VERSION "$Format:%h$"

NS_ :

BS_:

BU_: APB APP APS BCCEN BDY DAS DBG EAS EPAS EPAS2 EPAS3S EPB EPBM ESP GTW GTWU IBST IC MCU OCS PARK PARK3 RADAR RCM RT3000 SCCM SDM SEC TAS TAS2 TAS2DBG TOOL TPMS VCSEATD VCSEATP

BO_ 643 BODY_R1: 8 GTW
 SG_ DrRLtch_FL_Stat : 0|2@1+ (1,0) [0|0] "" Vector__XXX
 SG_ DrRLtch_FR_Stat : 2|2@1+ (1,0) [0|0] "" Vector__XXX
 SG_ DrRLtch_RL_Stat : 4|2@1+ (1,0) [0|0] "" Vector__XXX
 SG_ DrRLtch_RR_Stat : 6|2@1+ (1,0) [0|0] "" Vector__XXX
 SG_ DL_RLtch_Stat : 8|2@1+ (1,0) [0|0] "" Vector__XXX
 SG_ EngHd_Stat : 10|2@1+ (1,0) [0|0] "" Vector__XXX
 SG_ VTA_Alm_Actv : 13|1@1+ (1,0) [0|0] "" Vector__XXX
 SG_ LgtSens_Twlgt : 16|3@1+ (1,0) [0|7] "Steps" Vector__XXX
 SG_ LgtSens_SNA : 19|1@1+ (1,0) [0|0] "" Vector__XXX
 SG_ LgtSens_Tunnel : 20|1@1+ (1,0) [0|0] "" Vector__XXX
 SG_ LgtSens_Flt : 21|1@1+ (1,0) [0|0] "" Vector__XXX
 SG_ LgtSens_Night : 22|1@1+ (1,0) [0|0] "" SCCM
 SG_ ADL_LoBm_On_Rq : 23|1@1+ (1,0) [0|0] "" Vector__XXX
 SG_ Trlr_Stat : 24|2@1+ (1,0) [0|0] "" Vector__XXX
 SG_ Hrn_On : 26|1@1+ (1,0) [0|0] "" Vector__XXX
 SG_ Term54_Actv : 27|1@1+ (1,0) [0|0] "" Vector__XXX
 SG_ MPkBrk_Stat : 28|1@1+ (1,0) [0|0] "" Vector__XXX
 SG_ WprOutsdPkPosn : 29|1@1+ (1,0) [0|0] "" Vector__XXX
 SG_ LoBm_On_Rq : 32|1@1+ (1,0) [0|0] "" Vector__XXX
 SG_ HiBm_On : 33|1@1+ (1,0) [0|0] "" Vector__XXX
 SG_ IrLmp_D_Lt_Flt : 34|1@1+ (1,0) [0|0] "" Vector__XXX
 SG_ IrLmp_P_Rt_Flt : 35|1@1+ (1,0) [0|0] "" Vector__XXX
 SG_ LoBm_D_Lt_Flt : 36|1@1+ (1,0) [0|0] "" Vector__XXX
 SG_ LoBm_P_Rt_Flt : 37|1@1+ (1,0) [0|0] "" Vector__XXX
 SG_ RevGr_Engg : 38|2@1+ (1,0) [0|0] "" Vector__XXX
 SG_ AirTemp_Insd : 40|8@1+ (0.25,0) [0|58] "C" SCCM
 SG_ Bckl_Sw_RL_Stat_SAM_R : 48|2@1+ (1,0) [0|0] "" Vector__XXX
 SG_ Bckl_Sw_RR_Stat_SAM_R : 50|2@1+ (1,0) [0|0] "" Vector__XXX
 SG_ Bckl_Sw_RM_Stat_SAM_R : 52|2@1+ (1,0) [0|0] "" Vector__XXX
 SG_ StW_Cond_Stat : 54|2@1+ (1,0) [0|0] "" SCCM
 SG_ AirTemp_Outsd : 56|8@1+ (0.5,-40) [-40|85] "C" Vector__XXX

BO_ 15 CGW_STAT: 1 GTW
 SG_ CGW_Rout_Stat : 0|2@1+ (1,0) [0|0] "" SCCM
 SG_ BusFlt_PrmntActv : 2|1@1+ (1,0) [0|0] "" Vector__XXX

BO_ 556 CHG_status: 8 GTW
 SG_ CHG_evseAccept : 0|1@1+ (1,0) [0|0] "" Vector__XXX
 SG_ CHG_evseRequest : 1|1@1+ (1,0) [0|0] "" Vector__XXX
 SG_ CHG_retryCount : 2|2@1+ (1,0) [0|3] "" Vector__XXX
 SG_ CHG_mainState : 4|4@1+ (1,0) [0|0] "" Vector__XXX
 SG_ CHG_voltageLimitAchieved : 8|1@1+ (1,0) [0|0] "" Vector__XXX
 SG_ CHG_requestHVACPowerOn : 9|1@1+ (1,0) [0|0] "" Vector__XXX
 SG_ CHG_proximitySimUnlatched : 10|1@1+ (1,0) [0|0] "" Vector__XXX
 SG_ CHG_proximity : 11|2@1+ (1,0) [0|0] "" Vector__XXX
 SG_ CHG_pilot : 13|3@1+ (1,0) [0|0] "" Vector__XXX
 SG_ CHG_pilotCurrent : 16|8@1+ (0.5,0) [0|127.5] "A" Vector__XXX
 SG_ CHG_cableType : 24|3@1+ (1,0) [0|0] "" Vector__XXX
 SG_ CHG_cableState : 27|2@1+ (1,0) [0|0] "" EPB,EPBM
 SG_ CHG_phaseConfig : 29|3@1+ (1,0) [0|0] "" Vector__XXX
 SG_ CHG_v12V : 32|8@1+ (0.1,0) [0|0] "V" Vector__XXX
 SG_ CHG_lineChgShuttingDown : 40|1@1+ (1,0) [0|0] "" Vector__XXX
 SG_ CHG_subState : 41|6@1+ (1,0) [0|0] "" Vector__XXX
 SG_ CHG_waveformDataReady : 47|1@1+ (1,0) [0|0] "" Vector__XXX
 SG_ CHG_GFCICurrent : 48|7@1+ (0.4,0) [0|51] "mA" Vector__XXX
 SG_ CHG_maxLineCurrent : 55|7@1+ (1,0) [0|127] "A" Vector__XXX
 SG_ CHG_inputRelayState : 62|2@1+ (1,0) [0|0] "" Vector__XXX

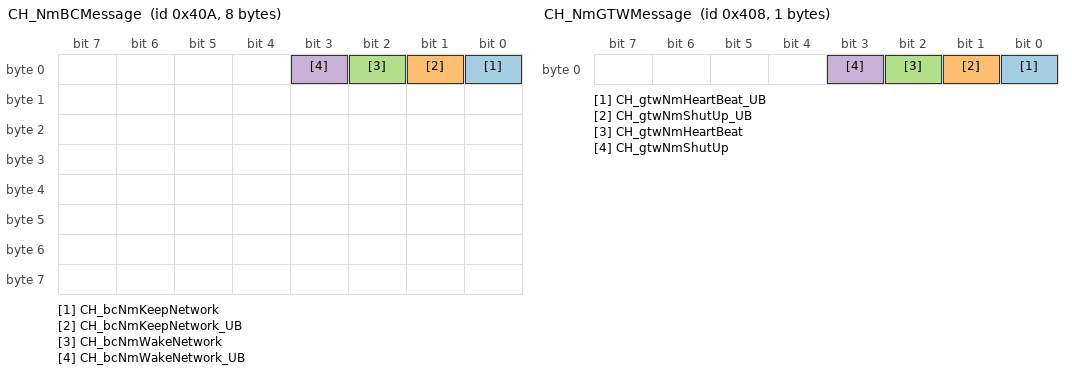
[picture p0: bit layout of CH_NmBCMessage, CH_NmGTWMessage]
BO_ 1034 CH_NmBCMessage: 8 BDY
 SG_ CH_bcNmKeepNetwork : 0|1@1+ (1,0) [0|0] "" GTW
 SG_ CH_bcNmKeepNetwork_UB : 1|1@1+ (1,0) [0|0] "" GTW
 SG_ CH_bcNmWakeNetwork : 2|1@1+ (1,0) [0|0] "" GTW
 SG_ CH_bcNmWakeNetwork_UB : 3|1@1+ (1,0) [0|0] "" GTW

BO_ 1032 CH_NmGTWMessage: 1 GTW
 SG_ CH_gtwNmHeartBeat_UB : 0|1@1+ (1,0) [0|0] "" BDY,SEC,BCCEN
 SG_ CH_gtwNmShutUp_UB : 1|1@1+ (1,0) [0|0] "" BDY,SEC,BCCEN
 SG_ CH_gtwNmHeartBeat : 2|1@1+ (1,0) [0|0] "" BDY,SEC,BCCEN
 SG_ CH_gtwNmShutUp : 3|1@1+ (1,0) [0|0] "" BDY,SEC,BCCEN

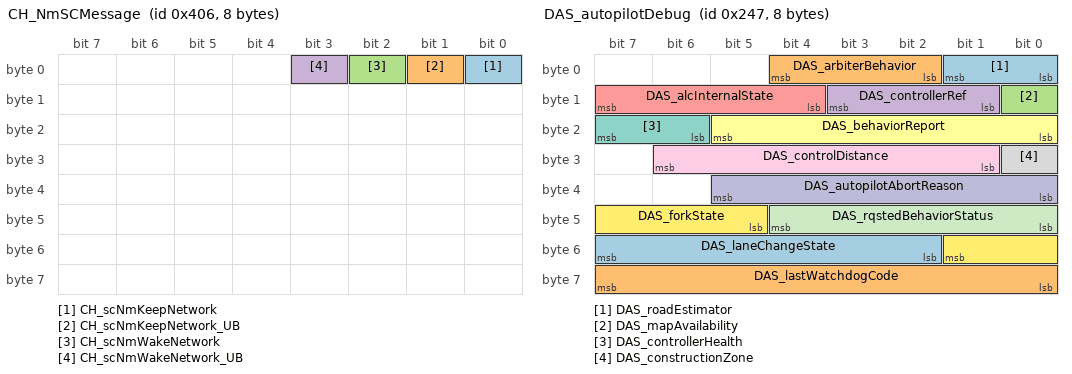
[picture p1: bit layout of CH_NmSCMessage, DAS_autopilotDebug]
BO_ 1030 CH_NmSCMessage: 8 SEC
 SG_ CH_scNmKeepNetwork : 0|1@1+ (1,0) [0|0] "" GTW
 SG_ CH_scNmKeepNetwork_UB : 1|1@1+ (1,0) [0|0] "" GTW
 SG_ CH_scNmWakeNetwork : 2|1@1+ (1,0) [0|0] "" GTW
 SG_ CH_scNmWakeNetwork_UB : 3|1@1+ (1,0) [0|0] "" GTW

BO_ 21 CTRL_U_A2: 4 GTW
 SG_ SwIllLvl : 0|8@1+ (1,0) [0|100] "%" SCCM
 SG_ DispBrt_IC : 8|8@1+ (1,0) [0|100] "%" Vector__XXX

BO_ 519 CVI: 8 GTW
 SG_ Group : 0|4@1+ (1,0) [0|0] "" SCCM
 SG_ Country : 4|4@1+ (1,0) [0|0] "" Vector__XXX
 SG_ VehLine : 8|6@1+ (1,0) [0|0] "" SCCM
 SG_ Guard : 14|2@1+ (1,0) [0|0] "" Vector__XXX
 SG_ VehLinePack : 16|2@1+ (1,0) [0|0] "" Vector__XXX
 SG_ VehLineYear : 18|5@1+ (1,2000) [2000|2029] "" Vector__XXX
 SG_ VSTS_Avl : 23|1@1+ (1,0) [0|0] "" Vector__XXX
 SG_ BodyStyle : 24|5@1+ (1,0) [0|0] "" Vector__XXX
 SG_ StStyle : 29|2@1+ (1,0) [0|0] "" SCCM
 SG_ PSTS_Avl : 31|1@1+ (1,0) [0|0] "" Vector__XXX
 SG_ EngStyle : 32|8@1+ (1,0) [0|0] "" Vector__XXX
 SG_ TCM_Avl : 40|1@1+ (1,0) [0|0] "" Vector__XXX
 SG_ HVAC_Avl : 41|1@1+ (1,0) [0|0] "" Vector__XXX
 SG_ TrlrHtch_Avl : 42|1@1+ (1,0) [0|0] "" Vector__XXX
 SG_ VTA_Avl : 43|1@1+ (1,0) [0|0] "" Vector__XXX
 SG_ PCD_Avl : 44|1@1+ (1,0) [0|0] "" Vector__XXX
 SG_ ICH_Avl : 45|1@1+ (1,0) [0|0] "" Vector__XXX
 SG_ LgtSens_Avl : 46|1@1+ (1,0) [0|0] "" Vector__XXX
 SG_ RainSens_Avl : 47|1@1+ (1,0) [0|0] "" Vector__XXX
 SG_ HVACStyle : 48|2@1+ (1,0) [0|0] "" Vector__XXX
 SG_ VehOPTPack : 50|2@1+ (1,0) [0|0] "" Vector__XXX
 SG_ Cplt_SL_Enbl : 52|1@1+ (1,0) [0|0] "" Vector__XXX
 SG_ RoofStyle : 53|3@1+ (1,0) [0|0] "" Vector__XXX
 SG_ CRC_CVI : 56|8@1+ (1,0) [0|0] "" Vector__XXX

BO_ 1817 DAS_IsotermAP: 8 DAS
 SG_ DAS_IsotermAP : 0|64@1+ (1,0) [0|0] "" DBG

BO_ 1849 DAS_IsotermSMS: 8 DAS
 SG_ DAS_IsotermSMS : 0|64@1+ (1,0) [0|0] "" DBG

BO_ 1465 DAS_alertLog: 8 DAS
 SG_ DAS_alertID M : 0|14@1+ (1,0) [0|0] "" GTW
 SG_ DAS_alertType : 15|1@1+ (1,0) [0|0] "" GTW
 SG_ DAS_alertDataW0 m0 : 16|16@1+ (1,0) [0|0] "" GTW
 SG_ DAS_alertDataW1 m0 : 32|16@1+ (1,0) [0|0] "" GTW
 SG_ DAS_alertDataW2 m0 : 48|16@1+ (1,0) [0|0] "" GTW
 SG_ DAS_sw004_radIssue m4 : 16|1@1+ (1,0) [0|0] "" GTW
 SG_ DAS_sw004_radHWFailure m4 : 17|1@1+ (1,0) [0|0] "" GTW
 SG_ DAS_sw004_radSensorBlind m4 : 18|1@1+ (1,0) [0|0] "" GTW
 SG_ DAS_sw004_radSGUFailure m4 : 19|1@1+ (1,0) [0|0] "" GTW
 SG_ DAS_sw004_radMia m4 : 20|1@1+ (1,0) [0|0] "" GTW
 SG_ DAS_sw004_radDynamicsError m4 : 21|1@1+ (1,0) [0|0] "" GTW
 SG_ DAS_sw004_espMIA m4 : 23|1@1+ (1,0) [0|0] "" GTW
 SG_ DAS_sw004_accState m4 : 24|4@1+ (1,0) [0|0] "" GTW
 SG_ DAS_sw004_appMobileyeStatus m4 : 28|5@1+ (1,0) [0|0] "" GTW
 SG_ DAS_sw004_diCruiseStateFault m4 : 33|1@1+ (1,0) [0|0] "" GTW
 SG_ DAS_sw004_diMIA m4 : 34|1@1+ (1,0) [0|0] "" GTW
 SG_ DAS_sw004_accelPedalInvalid m4 : 35|1@1+ (1,0) [0|0] "" GTW
 SG_ DAS_sw004_stwAngleInvalid m4 : 36|1@1+ (1,0) [0|0] "" GTW
 SG_ DAS_sw004_accelerationInvalid m4 : 37|1@1+ (1,0) [0|0] "" GTW
 SG_ DAS_sw004_diSpeedInvalid m4 : 38|1@1+ (1,0) [0|0] "" GTW
 SG_ DAS_sw004_DASFeaturesDisabled m4 : 40|1@1+ (1,0) [0|0] "" GTW
 SG_ DAS_sw004_appMobileyeNotInVision m4 : 41|1@1+ (1,0) [0|0] "" GTW
 SG_ DAS_sw004_CamCommonMIA m4 : 42|1@1+ (1,0) [0|0] "" GTW
 SG_ DAS_sw004_CamObjectsMIA m4 : 43|1@1+ (1,0) [0|0] "" GTW
 SG_ DAS_sw004_CamWatchdog m4 : 44|1@1+ (1,0) [0|0] "" GTW
 SG_ DAS_sw004_RadarLowVisibility m4 : 45|1@1+ (1,0) [0|0] "" GTW
 SG_ DAS_sw004_RadarMisalignment m4 : 46|1@1+ (1,0) [0|0] "" GTW
 SG_ DAS_sw004_OutOfFocusImage m4 : 47|1@1+ (1,0) [0|0] "" GTW
 SG_ DAS_sw004_ImpairedVD m4 : 48|1@1+ (1,0) [0|0] "" GTW
 SG_ DAS_sw004_SunRay m4 : 49|1@1+ (1,0) [0|0] "" GTW
 SG_ DAS_sw004_Splashes m4 : 50|1@1+ (1,0) [0|0] "" GTW
 SG_ DAS_sw004_BlurredImage m4 : 51|1@1+ (1,0) [0|0] "" GTW
 SG_ DAS_sw004_LowSun m4 : 52|1@1+ (1,0) [0|0] "" GTW
 SG_ DAS_sw004_SmearedSpots m4 : 53|1@1+ (1,0) [0|0] "" GTW
 SG_ DAS_sw004_PartialBlockage m4 : 54|1@1+ (1,0) [0|0] "" GTW
 SG_ DAS_sw004_AutofixOutOfCalib m4 : 55|1@1+ (1,0) [0|0] "" GTW
 SG_ DAS_sw004_AutofixOutOfCalibHorzn m4 : 56|1@1+ (1,0) [0|0] "" GTW
 SG_ DAS_sw004_AutofixOutOfCalibYaw m4 : 57|1@1+ (1,0) [0|0] "" GTW
 SG_ DAS_sw004_FullBlockage m4 : 58|1@1+ (1,0) [0|0] "" GTW
 SG_ DAS_sw004_SmearedHalos m4 : 59|1@1+ (1,0) [0|0] "" GTW
 SG_ DAS_sw004_FoggyLights m4 : 60|1@1+ (1,0) [0|0] "" GTW
 SG_ DAS_sw004_SelfGlare m4 : 61|1@1+ (1,0) [0|0] "" GTW
 SG_ DAS_sw004_visionNotRunning m4 : 62|1@1+ (1,0) [0|1] "" GTW
 SG_ DAS_sw005_AutofixOutOfCalib m5 : 16|1@1+ (1,0) [0|0] "" GTW
 SG_ DAS_sw005_AutofixOutOfCalibYaw m5 : 17|1@1+ (1,0) [0|0] "" GTW
 SG_ DAS_sw005_RadarMisalignment m5 : 18|1@1+ (1,0) [0|0] "" GTW
 SG_ DAS_sw005_partialBlockage m5 : 20|1@1+ (1,0) [0|0] "" GTW
 SG_ DAS_sw005_fullBlockage m5 : 21|1@1+ (1,0) [0|0] "" GTW
 SG_ DAS_sw005_camObjHeader m5 : 22|1@1+ (1,0) [0|0] "" GTW
 SG_ DAS_sw005_camCommonMsg m5 : 23|1@1+ (1,0) [0|0] "" GTW
 SG_ DAS_sw005_camFcwPcwMsg m5 : 24|1@1+ (1,0) [0|0] "" GTW
 SG_ DAS_sw005_radHWFailure m5 : 25|1@1+ (1,0) [0|0] "" GTW
 SG_ DAS_sw005_radSensorBlind m5 : 26|1@1+ (1,0) [0|0] "" GTW
 SG_ DAS_sw005_radSGUFailure m5 : 27|1@1+ (1,0) [0|0] "" GTW
 SG_ DAS_sw005_radMia m5 : 28|1@1+ (1,0) [0|0] "" GTW
 SG_ DAS_sw005_brakePedal m5 : 29|1@1+ (1,0) [0|0] "" GTW
 SG_ DAS_sw005_steeringAngle m5 : 30|1@1+ (1,0) [0|0] "" GTW
 SG_ DAS_sw005_steeringAngleRate m5 : 31|1@1+ (1,0) [0|0] "" GTW
 SG_ DAS_sw005_speed m5 : 32|1@1+ (1,0) [0|0] "" GTW
 SG_ DAS_sw005_gear m5 : 33|1@1+ (1,0) [0|0] "" GTW
 SG_ DAS_sw005_stabilityControl m5 : 34|1@1+ (1,0) [0|0] "" GTW
 SG_ DAS_sw005_blinkers m5 : 35|1@1+ (1,0) [0|0] "" GTW
 SG_ DAS_sw005_yaw m5 : 36|1@1+ (1,0) [0|0] "" GTW
 SG_ DAS_sw005_longAccel m5 : 37|1@1+ (1,0) [0|0] "" GTW
 SG_ DAS_sw005_accelPedal m5 : 38|1@1+ (1,0) [0|0] "" GTW
 SG_ DAS_sw005_fcmSensitivity m5 : 41|1@1+ (1,0) [0|0] "" GTW
 SG_ DAS_sw005_dasDisabled m5 : 42|1@1+ (1,0) [0|0] "" GTW
 SG_ DAS_sw005_speedDerivative m5 : 43|1@1+ (1,0) [0|0] "" GTW
 SG_ DAS_sw005_camWatchdog m5 : 44|1@1+ (1,0) [0|0] "" GTW
 SG_ DAS_sw005_AutofixOutOfCalibHorzn m5 : 45|1@1+ (1,0) [0|0] "" GTW
 SG_ DAS_sw005_RadarLowVisibility m5 : 46|1@1+ (1,0) [0|0] "" GTW
 SG_ DAS_sw005_radCalibration m5 : 47|1@1+ (1,0) [0|0] "" GTW
 SG_ DAS_sw006_RadarLowVisibility m6 : 16|1@1+ (1,0) [0|0] "" GTW
 SG_ DAS_sw006_RadarMisaligned m6 : 17|1@1+ (1,0) [0|0] "" GTW
 SG_ DAS_sw006_OutOfFocusImage m6 : 18|1@1+ (1,0) [0|0] "" GTW
 SG_ DAS_sw006_SunRay m6 : 19|1@1+ (1,0) [0|0] "" GTW
 SG_ DAS_sw006_Splashes m6 : 20|1@1+ (1,0) [0|0] "" GTW
 SG_ DAS_sw006_BlurredImage m6 : 21|1@1+ (1,0) [0|0] "" GTW
 SG_ DAS_sw006_LowSun m6 : 22|1@1+ (1,0) [0|0] "" GTW
 SG_ DAS_sw006_SmearedSpots m6 : 23|1@1+ (1,0) [0|0] "" GTW
 SG_ DAS_sw006_PartialBlockage m6 : 24|1@1+ (1,0) [0|0] "" GTW
 SG_ DAS_sw006_AutofixOutOfCalib m6 : 25|1@1+ (1,0) [0|0] "" GTW
 SG_ DAS_sw006_AutofixOutOfCalibHorzn m6 : 26|1@1+ (1,0) [0|0] "" GTW
 SG_ DAS_sw006_AutofixOutOfCalibYaw m6 : 27|1@1+ (1,0) [0|0] "" GTW
 SG_ DAS_sw006_FullBlockage m6 : 28|1@1+ (1,0) [0|0] "" GTW
 SG_ DAS_sw006_SmearedHalos m6 : 29|1@1+ (1,0) [0|0] "" GTW
 SG_ DAS_sw006_FoggyLights m6 : 30|1@1+ (1,0) [0|0] "" GTW
 SG_ DAS_sw006_SelfGlare m6 : 31|1@1+ (1,0) [0|0] "" GTW
 SG_ DAS_sw006_blinkers m6 : 32|1@1+ (1,0) [0|0] "" GTW
 SG_ DAS_sw006_seatbelt m6 : 33|1@1+ (1,0) [0|0] "" GTW
 SG_ DAS_sw006_accelPedal m6 : 34|1@1+ (1,0) [0|0] "" GTW
 SG_ DAS_sw006_radMia m6 : 35|1@1+ (1,0) [0|0] "" GTW
 SG_ DAS_sw006_radHWFailure m6 : 37|1@1+ (1,0) [0|0] "" GTW
 SG_ DAS_sw006_radSensorBlind m6 : 38|1@1+ (1,0) [0|0] "" GTW
 SG_ DAS_sw006_radSGUFailure m6 : 39|1@1+ (1,0) [0|0] "" GTW
 SG_ DAS_sw006_brakePedal m6 : 40|1@1+ (1,0) [0|0] "" GTW
 SG_ DAS_sw006_steeringAngle m6 : 41|1@1+ (1,0) [0|0] "" GTW
 SG_ DAS_sw006_steeringAngleRate m6 : 42|1@1+ (1,0) [0|0] "" GTW
 SG_ DAS_sw006_speed m6 : 43|1@1+ (1,0) [0|0] "" GTW
 SG_ DAS_sw006_gear m6 : 44|1@1+ (1,0) [0|0] "" GTW
 SG_ DAS_sw006_stabilityControl m6 : 45|1@1+ (1,0) [0|0] "" GTW
 SG_ DAS_sw006_dasDisabled m6 : 47|1@1+ (1,0) [0|0] "" GTW
 SG_ DAS_sw006_speedDerivative m6 : 48|1@1+ (1,0) [0|0] "" GTW
 SG_ DAS_sw006_camWatchdog m6 : 49|1@1+ (1,0) [0|0] "" GTW
 SG_ DAS_sw006_camObjHeader m6 : 50|1@1+ (1,0) [0|0] "" GTW
 SG_ DAS_sw006_camCommonMsg m6 : 51|1@1+ (1,0) [0|0] "" GTW
 SG_ DAS_sw006_camFcwPcwMsg m6 : 52|1@1+ (1,0) [0|0] "" GTW
 SG_ DAS_sw006_longAccel m6 : 53|1@1+ (1,0) [0|0] "" GTW
 SG_ DAS_sw006_yawRate m6 : 54|1@1+ (1,0) [0|0] "" GTW
 SG_ DAS_sw006_DIaebState_SNA m6 : 55|1@1+ (1,0) [0|0] "" GTW
 SG_ DAS_sw006_DIaebStateUnavailable m6 : 56|1@1+ (1,0) [0|0] "" GTW
 SG_ DAS_sw006_brakeLights m6 : 57|1@1+ (1,0) [0|0] "" GTW
 SG_ DAS_sw006_trailerMode m6 : 58|1@1+ (1,0) [0|0] "" GTW
 SG_ DAS_sw006_timeOfDay m6 : 59|2@1+ (1,0) [0|0] "" GTW
 SG_ DAS_sw006_radCalibration m6 : 61|1@1+ (1,0) [0|0] "" GTW
 SG_ DAS_sw009_DIaebState_fault m9 : 16|1@1+ (1,0) [0|0] "" GTW
 SG_ DAS_sw009_DI_aeb_unresponsive m9 : 17|1@1+ (1,0) [0|0] "" GTW
 SG_ DAS_sw009_DI_MIA m9 : 18|1@1+ (1,0) [0|0] "" GTW
 SG_ DAS_sw010_a04calibNotDone m10 : 16|1@1+ (1,0) [0|0] "" GTW
 SG_ DAS_sw010_a05calibReqd m10 : 17|1@1+ (1,0) [0|0] "" GTW
 SG_ DAS_sw010_a06calibNotOK m10 : 18|1@1+ (1,0) [0|0] "" GTW
 SG_ DAS_sw010_a08PlantMode m10 : 19|1@1+ (1,0) [0|0] "" GTW
 SG_ DAS_sw010_HorizontalMisalignment m10 : 20|16@1+ (0.00137332,-45) [-45|45.0005262] "deg" GTW
 SG_ DAS_sw010_VerticalMisalignment m10 : 36|10@1+ (0.087977,-45) [-45|45.000471] "deg" GTW
 SG_ DAS_sw010_unusedBits m10 : 46|2@1+ (1,0) [0|0] "" GTW
 SG_ DAS_sw010_VmaPlausibility m10 : 48|16@1+ (1.52587890625005E-05,0) [0|0.99998474121097] "" GTW
 SG_ DAS_sw011_scaState m11 : 16|3@1+ (1,0) [0|7] "" GTW
 SG_ DAS_sw011_scaLeft m11 : 19|1@1+ (1,0) [0|1] "" GTW
 SG_ DAS_sw011_scaRight m11 : 20|1@1+ (1,0) [0|1] "" GTW
 SG_ DAS_sw011_scaBlinker m11 : 21|2@1+ (1,0) [0|3] "" GTW
 SG_ DAS_sw011_scaThreshold m11 : 23|1@1+ (1,0) [0|1] "" GTW
 SG_ DAS_sw011_scaSpeed m11 : 24|7@1+ (1,0) [0|127] "MPH" GTW
 SG_ DAS_sw011_scaSonicDist m11 : 31|5@1+ (0.05,0) [0|1.5] "m" GTW
 SG_ DAS_sw011_scaSteerAngle m11 : 38|10@1+ (0.1,-51.2) [-51.2|51.1] "deg" GTW
 SG_ DAS_sw011_egoRightOfCenter m11 : 48|1@1+ (1,0) [0|1] "" GTW
 SG_ DAS_sw011_egoMovingRight m11 : 49|1@1+ (1,0) [0|1] "" GTW
 SG_ DAS_sw011_egoLeftOfCenter m11 : 50|1@1+ (1,0) [0|1] "" GTW
 SG_ DAS_sw011_egoMovingLeft m11 : 51|1@1+ (1,0) [0|1] "" GTW
 SG_ DAS_sw011_polyValid m11 : 52|1@1+ (1,0) [0|1] "" GTW
 SG_ DAS_sw011_egoCentered m11 : 53|1@1+ (1,0) [0|1] "" GTW
 SG_ DAS_sw011_scaReasonEldw m11 : 54|1@1+ (1,0) [0|1] "" GTW
 SG_ DAS_sw011_laneWidth m11 : 56|8@1+ (0.025,0) [0|6.375] "m" GTW
 SG_ DAS_sw012_bootTestResults m12 : 16|16@1+ (1,0) [0|65535] "" GTW
 SG_ DAS_sw012_bootDDRTempStatus m12 : 32|2@1+ (1,0) [0|3] "" GTW
 SG_ DAS_sw012_mespFatalErrCode m12 : 34|8@1+ (1,0) [0|255] "" GTW
 SG_ DAS_sw012_mespFatalErrDetails m12 : 42|8@1+ (1,0) [0|255] "" GTW
 SG_ DAS_sw012_mespDDRTempStatus m12 : 50|3@1+ (1,0) [0|7] "" GTW
 SG_ DAS_sw012_freescaleTemp m12 : 56|8@1- (1,0) [-128|127] "degC" GTW
 SG_ DAS_sw013_stateBeforeWatchdog m13 : 16|5@1+ (1,0) [0|0] "" GTW
 SG_ DAS_sw013_numEyeqResets m13 : 21|3@1+ (1,0) [0|0] "" GTW
 SG_ DAS_sw013_numCrcErrors m13 : 24|8@1+ (1,0) [0|0] "" GTW
 SG_ DAS_sw013_numSeqErrors m13 : 32|8@1+ (1,0) [0|0] "" GTW
 SG_ DAS_sw013_numNaksReceived m13 : 40|8@1+ (1,0) [0|0] "" GTW
 SG_ DAS_sw013_highestSeqRecd m13 : 48|12@1+ (1,0) [0|0] "" GTW
 SG_ DAS_sw013_numTransportErrors m13 : 60|4@1+ (1,0) [0|0] "" GTW
 SG_ DAS_sw014_fileNameHash m14 : 16|16@1+ (1,0) [0|0] "" GTW
 SG_ DAS_sw014_lineNumberInCode m14 : 32|16@1+ (1,0) [0|0] "" GTW
 SG_ DAS_sw014_assertData m14 : 48|16@1+ (1,0) [0|0] "" GTW
 SG_ DAS_sw015_RadarLowVisibility m15 : 16|2@1+ (1,0) [0|1] "" GTW
 SG_ DAS_sw015_RadarMisalignment m15 : 18|2@1+ (1,0) [0|1] "" GTW
 SG_ DAS_sw015_LowSun m15 : 20|2@1+ (1,0) [0|1] "" GTW
 SG_ DAS_sw015_BlurredImage m15 : 22|2@1+ (1,0) [0|1] "" GTW
 SG_ DAS_sw015_FullBlockage m15 : 24|2@1+ (1,0) [0|1] "" GTW
 SG_ DAS_sw015_PartialBlockage m15 : 26|2@1+ (1,0) [0|1] "" GTW
 SG_ DAS_sw015_AutofixOutOfCalib m15 : 28|2@1+ (1,0) [0|1] "" GTW
 SG_ DAS_sw015_AutofixOutOfCalibYaw m15 : 30|2@1+ (1,0) [0|1] "" GTW
 SG_ DAS_sw015_AutofixOOfCalibHorizon m15 : 32|2@1+ (1,0) [0|1] "" GTW
 SG_ DAS_sw015_Splashes m15 : 34|2@1+ (1,0) [0|1] "" GTW
 SG_ DAS_sw015_SmearedSpots m15 : 36|2@1+ (1,0) [0|1] "" GTW
 SG_ DAS_sw015_SmearedHalos m15 : 38|2@1+ (1,0) [0|1] "" GTW
 SG_ DAS_sw015_FoggyLights m15 : 40|2@1+ (1,0) [0|1] "" GTW
 SG_ DAS_sw015_SunRay m15 : 42|2@1+ (1,0) [0|1] "" GTW
 SG_ DAS_sw015_ImpairedVD m15 : 44|2@1+ (1,0) [0|1] "" GTW
 SG_ DAS_sw015_SelfGlare m15 : 46|2@1+ (1,0) [0|1] "" GTW
 SG_ DAS_sw015_OutOfFocusImage m15 : 48|2@1+ (1,0) [0|1] "" GTW
 SG_ DAS_sw016_targetDist m16 : 16|9@1+ (0.2,0) [0|102.2] "m" GTW
 SG_ DAS_sw016_targetRelSpeed m16 : 25|9@1+ (0.0625,-31) [-31|0.9375] "m/s" GTW
 SG_ DAS_sw016_targetOverlap m16 : 34|6@1+ (0.1,0) [0|6.3] "m" GTW
 SG_ DAS_sw016_hostSpeed m16 : 40|8@1+ (1,0) [0|255] "kph" GTW
 SG_ DAS_sw016_hostLongAccel m16 : 48|7@1+ (0.15625,-10) [-10|10] "m/s^2" GTW
 SG_ DAS_sw016_driverPressedAccelPed m16 : 55|1@1+ (1,0) [0|1] "" GTW
 SG_ DAS_sw016_driverPressedBrakePed m16 : 56|1@1+ (1,0) [0|1] "" GTW
 SG_ DAS_sw016_aebEnable m16 : 57|1@1+ (1,0) [0|1] "" GTW
 SG_ DAS_sw016_overrideBlinker m16 : 58|1@1+ (1,0) [0|1] "" GTW
 SG_ DAS_sw016_overrideBrake m16 : 59|1@1+ (1,0) [0|1] "" GTW
 SG_ DAS_sw016_overrideSteer m16 : 60|1@1+ (1,0) [0|1] "" GTW
 SG_ DAS_sw016_fcmModeAtEvent m16 : 61|2@1+ (1,0) [0|3] "" GTW
 SG_ DAS_sw016_accActive m16 : 63|1@1+ (1,0) [0|1] "" GTW
 SG_ DAS_sw017_Camera_Msg_Lanes_MIA m17 : 16|1@1+ (1,0) [0|1] "" GTW
 SG_ DAS_sw017_Camera_Msg_Objects_MIA m17 : 17|1@1+ (1,0) [0|1] "" GTW
 SG_ DAS_sw017_Camera_Msg_Tsr_MIA m17 : 18|1@1+ (1,0) [0|1] "" GTW
 SG_ DAS_sw017_Camera_Msg_Hlb_MIA m17 : 19|1@1+ (1,0) [0|1] "" GTW
 SG_ DAS_sw017_Camera_Msg_Common_MIA m17 : 20|1@1+ (1,0) [0|1] "" GTW
 SG_ DAS_sw017_Camera_Msg_FCW_PCW_MIA m17 : 21|1@1+ (1,0) [0|1] "" GTW
 SG_ DAS_sw017_Camera_Msg_TFL_MIA m17 : 22|1@1+ (1,0) [0|1] "" GTW
 SG_ DAS_sw017_Any_Lanes_Msg_Recd m17 : 23|1@1+ (1,0) [0|1] "" GTW
 SG_ DAS_sw017_Any_Objects_Msg_Recd m17 : 24|1@1+ (1,0) [0|1] "" GTW
 SG_ DAS_sw017_Any_TFL_Msg_Recd m17 : 25|1@1+ (1,0) [0|1] "" GTW
 SG_ DAS_sw017_numCrcErrors m17 : 26|6@1+ (1,0) [0|63] "" GTW
 SG_ DAS_sw017_numSeqErrors m17 : 32|8@1+ (1,0) [0|255] "" GTW
 SG_ DAS_sw017_numTransportErrors m17 : 40|8@1+ (1,0) [0|0] "" GTW
 SG_ DAS_sw017_highestSeqRecd m17 : 48|12@1+ (1,0) [0|0] "" GTW
 SG_ DAS_sw017_Any_Tsr_Msg_Recd m17 : 60|1@1+ (1,0) [0|1] "" GTW
 SG_ DAS_sw017_Any_Hlb_Msg_Recd m17 : 61|1@1+ (1,0) [0|1] "" GTW
 SG_ DAS_sw017_Any_Common_Msg_Recd m17 : 62|1@1+ (1,0) [0|1] "" GTW
 SG_ DAS_sw017_Any_FCW_PCW_Msg_Recd m17 : 63|1@1+ (1,0) [0|1] "" GTW
 SG_ DAS_sw018_minThreshold m18 : 16|13@1+ (1,0) [0|4500] "mV" GTW
 SG_ DAS_sw018_railID m18 : 29|2@1+ (1,0) [0|3] "" GTW
 SG_ DAS_sw018_powerSequnceError m18 : 31|1@1+ (1,0) [0|3] "" GTW
 SG_ DAS_sw018_maxThreshold m18 : 32|15@1+ (1,0) [50|5500] "mV" GTW
 SG_ DAS_sw018_railControl m18 : 47|1@1+ (1,0) [0|1] "" GTW
 SG_ DAS_sw018_currentVoltage m18 : 48|16@1+ (1,0) [0|6600] "mV" GTW
 SG_ DAS_sw019_taskId m19 : 16|8@1+ (1,0) [0|0] "" GTW
 SG_ DAS_sw019_numFreeBytes m19 : 24|8@1+ (1,-191) [-191|64] "# of bytes" GTW
 SG_ DAS_sw019_timeStamp m19 : 32|32@1+ (1,0) [0|4294967295] "ms" GTW
 SG_ DAS_sw020_unusedW0 m20 : 16|16@1+ (1,0) [0|0] "" GTW
 SG_ DAS_sw020_unusedW1 m20 : 32|16@1+ (1,0) [0|0] "" GTW
 SG_ DAS_sw020_unusedW2 m20 : 48|16@1+ (1,0) [0|0] "" GTW
 SG_ DAS_sw021_tempSensorId m21 : 16|8@1+ (1,0) [0|4] "" GTW
 SG_ DAS_sw021_minThreshold m21 : 24|8@1- (1,0) [-128|127] "degC" GTW
 SG_ DAS_sw021_maxThreshold m21 : 32|8@1- (1,0) [-128|127] "degC" GTW
 SG_ DAS_sw021_currentTemperature m21 : 40|8@1- (1,0) [-128|127] "degC" GTW
 SG_ DAS_sw021_unusedWord m21 : 48|16@1+ (1,0) [0|0] "" GTW
 SG_ DAS_sw022_operation m22 : 16|4@1+ (1,0) [0|0] "" GTW
 SG_ DAS_sw022_recordId m22 : 20|12@1+ (1,0) [0|0] "" GTW
 SG_ DAS_sw022_errorCode m22 : 32|32@1+ (1,0) [0|0] "" GTW
 SG_ DAS_sw024_Task_ID m24 : 16|4@1+ (1,0) [0|0] "" GTW
 SG_ DAS_sw024_numVirtualLaneVeh m24 : 20|4@1+ (1,0) [0|0] "" GTW
 SG_ DAS_sw024_currentVehicleApp m24 : 24|8@1+ (1,0) [0|0] "" GTW
 SG_ DAS_sw024_taskProgramCounter m24 : 32|32@1+ (1,0) [0|0] "" GTW
 SG_ DAS_sw025_state_before_override m25 : 16|4@1+ (1,0) [0|15] "" GTW
 SG_ DAS_sw025_road_class m25 : 20|3@1+ (1,0) [0|0] "" GTW
 SG_ DAS_sw025_road_match m25 : 23|1@1+ (1,0) [0|0] "" GTW
 SG_ DAS_sw025_controlled_access m25 : 24|1@1+ (1,0) [0|0] "" GTW
 SG_ DAS_sw025_leftLaneUsage m25 : 25|2@1+ (1,0) [0|3] "" GTW
 SG_ DAS_sw025_rightLaneUsage m25 : 27|2@1+ (1,0) [0|3] "" GTW
 SG_ DAS_sw025_vehiclesUsage m25 : 29|2@1+ (1,0) [0|3] "" GTW
 SG_ DAS_sw025_hppUsage m25 : 31|2@1+ (1,0) [0|3] "" GTW
 SG_ DAS_sw025_navigationUsage m25 : 33|2@1+ (1,0) [0|3] "" GTW
 SG_ DAS_sw025_modelUsage m25 : 35|2@1+ (1,0) [0|3] "" GTW
 SG_ DAS_sw025_bottsDotsUsage m25 : 37|2@1+ (1,0) [0|3] "" GTW
 SG_ DAS_sw025_offsetSide m25 : 39|2@1+ (1,0) [0|3] "" GTW
 SG_ DAS_sw025_torsionBarTorque m25 : 41|8@1+ (0.1,-12.8) [-12.8|12.7] "Nm" GTW
 SG_ DAS_sw026_task_id m26 : 16|2@1+ (1,0) [0|3] "" GTW
 SG_ DAS_sw026_tardiness m26 : 18|9@1+ (0.25,0) [0|127.75] "ms" GTW
 SG_ DAS_sw026_execution_time m26 : 27|9@1+ (0.125,0) [0|65.411] "ms" GTW
 SG_ DAS_sw026_can_mean_utilization m26 : 36|7@1+ (1,0) [0|127] "percent" GTW
 SG_ DAS_sw026_uds_mean_utilization m26 : 43|7@1+ (1,0) [0|127] "percent" GTW
 SG_ DAS_sw026_mob_mean_utilization m26 : 50|7@1+ (1,0) [0|127] "percent" GTW
 SG_ DAS_sw026_veh_mean_utilization m26 : 57|7@1+ (1,0) [0|127] "percent" GTW
 SG_ DAS_sw027_JTAG_Reset m27 : 16|1@1+ (1,0) [0|0] "" GTW
 SG_ DAS_sw027_Core_Reset m27 : 17|1@1+ (1,0) [0|0] "" GTW
 SG_ DAS_sw027_Unused_Bit_0 m27 : 18|1@1+ (1,0) [0|0] "" GTW
 SG_ DAS_sw027_CPU_Checkstop_Error m27 : 19|1@1+ (1,0) [0|0] "" GTW
 SG_ DAS_sw027_PLL_0_Failure m27 : 20|1@1+ (1,0) [0|0] "" GTW
 SG_ DAS_sw027_Clock_Monitor_0_Low m27 : 21|1@1+ (1,0) [0|0] "" GTW
 SG_ DAS_sw027_Clock_Monitor_0_Off m27 : 22|1@1+ (1,0) [0|0] "" GTW
 SG_ DAS_sw027_LVD_4v5 m27 : 23|1@1+ (1,0) [0|0] "" GTW
 SG_ DAS_sw027_Flash_Fatal_Error m27 : 24|1@1+ (1,0) [0|0] "" GTW
 SG_ DAS_sw027_PLL_1_Failure m27 : 25|1@1+ (1,0) [0|0] "" GTW
 SG_ DAS_sw027_Unused_Bit_1 m27 : 26|1@1+ (1,0) [0|0] "" GTW
 SG_ DAS_sw027_f_PLL_1_Off m27 : 27|1@1+ (1,0) [0|0] "" GTW
 SG_ DAS_sw027_Unused_Nibble m27 : 28|4@1+ (1,0) [0|0] "" GTW
 SG_ DAS_sw027_LVD_1v2 m27 : 32|1@1+ (1,0) [0|0] "" GTW
 SG_ DAS_sw027_Unused_Bit_2 m27 : 33|1@1+ (1,0) [0|0] "" GTW
 SG_ DAS_sw027_Watchdog m27 : 34|1@1+ (1,0) [0|0] "" GTW
 SG_ DAS_sw027_Unused_Bit_3 m27 : 35|1@1+ (1,0) [0|0] "" GTW
 SG_ DAS_sw027_LVD_2v7_VREG m27 : 36|1@1+ (1,0) [0|0] "" GTW
 SG_ DAS_sw027_LVD_2v7_Flash m27 : 37|1@1+ (1,0) [0|0] "" GTW
 SG_ DAS_sw027_LVD_2v7_IO m27 : 38|1@1+ (1,0) [0|0] "" GTW
 SG_ DAS_sw027_Unused_Bit_4 m27 : 39|1@1+ (1,0) [0|0] "" GTW
 SG_ DAS_sw027_Unused_Byte m27 : 40|8@1+ (1,0) [0|0] "" GTW
 SG_ DAS_sw027_ESR0 m27 : 48|1@1+ (1,0) [0|0] "" GTW
 SG_ DAS_sw027_ESR1 m27 : 49|1@1+ (1,0) [0|0] "" GTW
 SG_ DAS_sw027_SW m27 : 50|1@1+ (1,0) [0|0] "" GTW
 SG_ DAS_sw027_STM0 m27 : 51|1@1+ (1,0) [0|0] "" GTW
 SG_ DAS_sw027_STM1 m27 : 52|1@1+ (1,0) [0|0] "" GTW
 SG_ DAS_sw027_STM2 m27 : 53|1@1+ (1,0) [0|0] "" GTW
 SG_ DAS_sw027_CBS_SYSTEM m27 : 54|1@1+ (1,0) [0|0] "" GTW
 SG_ DAS_sw027_CBS_DEBUG m27 : 55|1@1+ (1,0) [0|0] "" GTW
 SG_ DAS_sw027_CBS_APP m27 : 56|1@1+ (1,0) [0|0] "" GTW
 SG_ DAS_sw027_EVR13 m27 : 57|1@1+ (1,0) [0|0] "" GTW
 SG_ DAS_sw027_EVR33 m27 : 58|1@1+ (1,0) [0|0] "" GTW
 SG_ DAS_sw027_SWD m27 : 59|1@1+ (1,0) [0|0] "" GTW
 SG_ DAS_sw027_STDBY_WDG m27 : 60|1@1+ (1,0) [0|0] "" GTW
 SG_ DAS_sw027_PORST m27 : 61|1@1+ (1,0) [0|0] "" GTW
 SG_ DAS_sw027_Unused_word m27 : 62|2@1+ (1,0) [0|0] "" GTW
 SG_ DAS_sw028_rx_buffer_full m28 : 16|1@1+ (1,0) [0|0] "" GTW
 SG_ DAS_sw028_rx_inv_len m28 : 17|1@1+ (1,0) [0|0] "" GTW
 SG_ DAS_sw028_inv_multifrm_1st m28 : 18|1@1+ (1,0) [0|0] "" GTW
 SG_ DAS_sw028_inv_multifrm_id m28 : 19|1@1+ (1,0) [0|0] "" GTW
 SG_ DAS_sw028_inv_multifrm_next m28 : 20|1@1+ (1,0) [0|0] "" GTW
 SG_ DAS_sw028_unusedBits m28 : 21|11@1+ (1,0) [0|0] "" GTW
 SG_ DAS_sw028_highestSeqRcvd m28 : 32|16@1+ (1,0) [0|0] "" GTW
 SG_ DAS_sw028_multifrm_rx_len m28 : 48|16@1+ (1,0) [0|0] "" GTW
 SG_ DAS_sw029_tx_buffer_full m29 : 16|1@1+ (1,0) [0|0] "" GTW
 SG_ DAS_sw029_unusedBits m29 : 17|15@1+ (1,0) [0|0] "" GTW
 SG_ DAS_sw029_highestSeqRcvd m29 : 32|16@1+ (1,0) [0|0] "" GTW
 SG_ DAS_sw029_unusedW1 m29 : 48|16@1+ (1,0) [0|0] "" GTW
 SG_ DAS_sw030_heaterState m30 : 16|8@1+ (1,0) [0|0] "" GTW
 SG_ DAS_sw030_unusedByte m30 : 24|8@1+ (1,0) [0|0] "" GTW
 SG_ DAS_sw030_unusedW0 m30 : 32|16@1+ (1,0) [0|0] "" GTW
 SG_ DAS_sw030_unusedW1 m30 : 48|16@1+ (1,0) [0|0] "" GTW
 SG_ DAS_sw031_canBus m31 : 16|4@1+ (1,0) [0|0] "" GTW
 SG_ DAS_sw031_errorType m31 : 24|8@1+ (1,0) [0|0] "" GTW
 SG_ DAS_sw031_errorData1 m31 : 32|16@1+ (1,0) [0|0] "" GTW
 SG_ DAS_sw031_errorData2 m31 : 48|16@1+ (1,0) [0|0] "" GTW
 SG_ DAS_sw032_canBus m32 : 16|4@1+ (1,0) [0|0] "" GTW
 SG_ DAS_sw032_errorType m32 : 24|8@1+ (1,0) [0|0] "" GTW
 SG_ DAS_sw032_errorData1 m32 : 32|16@1+ (1,0) [0|0] "" GTW
 SG_ DAS_sw032_errorData2 m32 : 48|16@1+ (1,0) [0|0] "" GTW
 SG_ DAS_sw033_gtwMia m33 : 16|8@1+ (1,0) [0|0] "" GTW
 SG_ DAS_sw033_unusedByte m33 : 24|8@1+ (1,0) [0|0] "" GTW
 SG_ DAS_sw033_bcStatus m33 : 32|1@1+ (1,0) [0|0] "" GTW
 SG_ DAS_sw033_carConfig m33 : 33|1@1+ (1,0) [0|0] "" GTW
 SG_ DAS_sw033_carState m33 : 34|1@1+ (1,0) [0|0] "" GTW
 SG_ DAS_sw033_chNm m33 : 35|1@1+ (1,0) [0|0] "" GTW
 SG_ DAS_sw033_odo m33 : 36|1@1+ (1,0) [0|0] "" GTW
 SG_ DAS_sw033_status m33 : 37|1@1+ (1,0) [0|0] "" GTW
 SG_ DAS_sw033_vip m33 : 38|1@1+ (1,0) [0|0] "" GTW
 SG_ DAS_sw034_sccmMia m34 : 16|8@1+ (1,0) [0|0] "" GTW
 SG_ DAS_sw034_unusedByte m34 : 24|8@1+ (1,0) [0|0] "" GTW
 SG_ DAS_sw034_sbwRq m34 : 32|1@1+ (1,0) [0|0] "" GTW
 SG_ DAS_sw034_stwActnRq m34 : 33|1@1+ (1,0) [0|0] "" GTW
 SG_ DAS_sw034_stwAnglHpStat m34 : 34|1@1+ (1,0) [0|0] "" GTW
 SG_ DAS_sw035_espMia m35 : 16|8@1+ (1,0) [0|0] "" GTW
 SG_ DAS_sw035_unusedByte m35 : 24|8@1+ (1,0) [0|0] "" GTW
 SG_ DAS_sw035_115h m35 : 32|1@1+ (1,0) [0|0] "" GTW
 SG_ DAS_sw035_125h m35 : 33|1@1+ (1,0) [0|0] "" GTW
 SG_ DAS_sw035_135h m35 : 34|1@1+ (1,0) [0|0] "" GTW
 SG_ DAS_sw035_145h m35 : 35|1@1+ (1,0) [0|0] "" GTW
 SG_ DAS_sw035_B m35 : 36|1@1+ (1,0) [0|0] "" GTW
 SG_ DAS_sw035_C m35 : 37|1@1+ (1,0) [0|0] "" GTW
 SG_ DAS_sw035_wheelSpeeds m35 : 38|1@1+ (1,0) [0|0] "" GTW
 SG_ DAS_sw036_bdyMia m36 : 16|8@1+ (1,0) [0|0] "" GTW
 SG_ DAS_sw036_unusedByte m36 : 24|8@1+ (1,0) [0|0] "" GTW
 SG_ DAS_sw036_status m36 : 32|1@1+ (1,0) [0|0] "" GTW
 SG_ DAS_sw037_camera m37 : 16|8@1+ (1,0) [0|0] "" GTW
 SG_ DAS_sw037_issue m37 : 24|8@1+ (1,0) [0|0] "" GTW
 SG_ DAS_sw037_unusedW0 m37 : 32|16@1+ (1,0) [0|0] "" GTW
 SG_ DAS_sw037_unusedW1 m37 : 48|16@1+ (1,0) [0|0] "" GTW
 SG_ DAS_sw038_RadarMisalignment m38 : 17|1@1+ (1,0) [0|1] "" GTW
 SG_ DAS_sw038_OutOfFocusImage m38 : 18|1@1+ (1,0) [0|1] "" GTW
 SG_ DAS_sw038_AutofixOutOfCalib m38 : 19|1@1+ (1,0) [0|1] "" GTW
 SG_ DAS_sw038_AutofixOutOfCalibHorzn m38 : 20|1@1+ (1,0) [0|1] "" GTW
 SG_ DAS_sw038_AutofixOutOfCalibYaw m38 : 21|1@1+ (1,0) [0|1] "" GTW
 SG_ DAS_sw038_FullBlockage m38 : 22|1@1+ (1,0) [0|1] "" GTW
 SG_ DAS_sw038_TooManyResets m38 : 23|1@1+ (1,0) [0|1] "" GTW
 SG_ DAS_sw039_sdm_rcm_Mia m39 : 16|8@1+ (1,0) [0|0] "" GTW
 SG_ DAS_sw039_unusedByte m39 : 24|8@1+ (1,0) [0|0] "" GTW
 SG_ DAS_sw039_status m39 : 32|1@1+ (1,0) [0|0] "" GTW
 SG_ DAS_sw039_sdm1 m39 : 33|1@1+ (1,0) [0|0] "" GTW
 SG_ DAS_sw040_accel_pedal_pos m40 : 16|8@1+ (0.5,0) [0|127.5] "%" GTW
 SG_ DAS_sw040_ego_veh_speed m40 : 24|8@1+ (0.2,0) [0|51] "m/s" GTW
 SG_ DAS_sw040_das_steering_req m40 : 32|8@1+ (1,-128) [-128|127] "deg" GTW
 SG_ DAS_sw040_epas_internal_sas m40 : 40|8@1+ (1,-128) [-128|127] "deg" GTW
 SG_ DAS_sw040_torsion_bar_torque m40 : 48|8@1+ (0.1,-12.8) [-12.8|12.7] "Nm" GTW
 SG_ DAS_sw040_view_range m40 : 56|8@1+ (1,0) [0|255] "m" GTW
 SG_ DAS_sw041_rate m41 : 16|10@1- (1,0) [-512|511] "deg/s" GTW
 SG_ DAS_sw041_max_rate m41 : 26|10@1- (1,0) [-512|511] "deg/s" GTW
 SG_ DAS_sw041_ego_speed m41 : 36|10@1+ (0.05,0) [0|51.15] "m/s" GTW
 SG_ DAS_sw041_unusedW2 m41 : 46|18@1+ (1,0) [0|0] "" GTW
 SG_ DAS_sw042_health_state m42 : 16|3@1+ (1,0) [0|0] "" GTW
 SG_ DAS_sw042_abort_reason m42 : 19|5@1+ (1,0) [0|31] "" GTW
 SG_ DAS_sw042_view_range m42 : 24|8@1+ (1,0) [0|0] "" GTW
 SG_ DAS_sw042_state_before_abort m42 : 32|4@1+ (1,0) [0|15] "" GTW
 SG_ DAS_sw042_epas_error_code m42 : 36|4@1+ (1,0) [0|15] "" GTW
 SG_ DAS_sw042_cam_SunRay m42 : 40|1@1+ (1,0) [0|1] "" GTW
 SG_ DAS_sw042_cam_RoadSpray m42 : 41|1@1+ (1,0) [0|1] "" GTW
 SG_ DAS_sw042_cam_BlurredImage m42 : 42|1@1+ (1,0) [0|1] "" GTW
 SG_ DAS_sw042_cam_LowSun m42 : 43|1@1+ (1,0) [0|1] "" GTW
 SG_ DAS_sw042_cam_SmearedSpots m42 : 44|1@1+ (1,0) [0|1] "" GTW
 SG_ DAS_sw042_cam_PartialBlock m42 : 45|1@1+ (1,0) [0|1] "" GTW
 SG_ DAS_sw042_cam_Autofix m42 : 46|1@1+ (1,0) [0|1] "" GTW
 SG_ DAS_sw042_cam_AutofixHorizon m42 : 47|1@1+ (1,0) [0|1] "" GTW
 SG_ DAS_sw042_cam_AutofixYaw m42 : 48|1@1+ (1,0) [0|1] "" GTW
 SG_ DAS_sw042_cam_FullBlock m42 : 49|1@1+ (1,0) [0|1] "" GTW
 SG_ DAS_sw042_cam_SmearedHalos m42 : 50|1@1+ (1,0) [0|1] "" GTW
 SG_ DAS_sw042_cam_FoggySpots m42 : 51|1@1+ (1,0) [0|1] "" GTW
 SG_ DAS_sw042_cam_SelfGlare m42 : 52|1@1+ (1,0) [0|1] "" GTW
 SG_ DAS_sw042_cam_OutofFocus m42 : 53|1@1+ (1,0) [0|1] "" GTW
 SG_ DAS_sw042_road_match m42 : 54|1@1+ (1,0) [0|1] "" GTW
 SG_ DAS_sw042_controlled_access m42 : 55|1@1+ (1,0) [0|1] "" GTW
 SG_ DAS_sw042_road_class m42 : 56|3@1+ (1,0) [0|7] "" GTW
 SG_ DAS_sw043_mobileye_status m43 : 16|16@1+ (1,0) [0|0] "" GTW
 SG_ DAS_sw043_mesp_health_main_state m43 : 32|16@1+ (1,0) [0|0] "" GTW
 SG_ DAS_sw043_camLongRunTime_unused m43 : 48|16@1+ (1,0) [0|0] "" GTW
 SG_ DAS_sw044_countLSB m44 : 16|8@1+ (1,0) [0|0] "" GTW
 SG_ DAS_sw044_meMainState m44 : 28|4@1+ (1,0) [0|15] "" GTW
 SG_ DAS_sw044_timestampms m44 : 32|24@1+ (1,0) [0|16777215] "ms" GTW
 SG_ DAS_sw044_appStatus m44 : 56|8@1+ (1,0) [0|63] "" GTW
 SG_ DAS_sw045_radMia m45 : 16|8@1+ (1,0) [0|0] "" GTW
 SG_ DAS_sw045_unusedByte m45 : 24|8@1+ (1,0) [0|0] "" GTW
 SG_ DAS_sw045_radcAlertMatrix m45 : 32|1@1+ (1,0) [0|0] "" GTW
 SG_ DAS_sw045_radcInfo m45 : 33|1@1+ (1,0) [0|0] "" GTW
 SG_ DAS_sw045_radcAccTargObj1A m45 : 34|1@1+ (1,0) [0|0] "" GTW
 SG_ DAS_sw045_lrrAlertMatrix0 m45 : 35|1@1+ (1,0) [0|0] "" GTW
 SG_ DAS_sw045_lrrPacketEnder m45 : 36|1@1+ (1,0) [0|0] "" GTW
 SG_ DAS_sw045_lrrRadarStatus m45 : 37|1@1+ (1,0) [0|0] "" GTW
 SG_ DAS_sw045_lrrObj00A m45 : 38|1@1+ (1,0) [0|0] "" GTW
 SG_ DAS_sw046_recordId m46 : 16|16@1+ (1,0) [0|0] "" GTW
 SG_ DAS_sw046_errorCode m46 : 32|32@1+ (1,0) [0|0] "" GTW
 SG_ DAS_sw047_edrStatus m47 : 16|4@1+ (1,0) [0|0] "" GTW
 SG_ DAS_sw047_roadClass m47 : 20|3@1+ (1,0) [0|0] "" GTW
 SG_ DAS_sw047_controlledAccess m47 : 23|1@1+ (1,0) [0|0] "" GTW
 SG_ DAS_sw047_edrType m47 : 24|6@1+ (1,0) [0|0] "" GTW
 SG_ DAS_sw047_edrBlackBox m47 : 30|2@1+ (1,0) [0|0] "" GTW
 SG_ DAS_sw047_edrReturn m47 : 32|16@1+ (1,0) [0|0] "" GTW
 SG_ DAS_sw047_edrStateMachine m47 : 48|8@1+ (1,0) [0|0] "" GTW
 SG_ DAS_sw047_edrLoggerBuffer m47 : 56|2@1+ (1,0) [0|0] "" GTW
 SG_ DAS_sw047_unused m47 : 58|6@1+ (1,0) [0|0] "" GTW
 SG_ DAS_sw048_swAssert m48 : 16|1@1+ (1,0) [0|1] "" GTW
 SG_ DAS_sw048_thermalIssue m48 : 17|1@1+ (1,0) [0|1] "" GTW
 SG_ DAS_sw048_powerIssue m48 : 18|1@1+ (1,0) [0|1] "" GTW
 SG_ DAS_sw048_stackOverflow m48 : 19|1@1+ (1,0) [0|1] "" GTW
 SG_ DAS_sw048_checkStop m48 : 20|1@1+ (1,0) [0|1] "" GTW
 SG_ DAS_sw048_ecuWatchdog m48 : 21|1@1+ (1,0) [0|1] "" GTW
 SG_ DAS_sw048_ecuReset m48 : 22|1@1+ (1,0) [0|1] "" GTW
 SG_ DAS_sw048_radcVersionMismatch m48 : 23|1@1+ (1,0) [0|1] "" GTW
 SG_ DAS_sw048_radcCalibration m48 : 24|1@1+ (1,0) [0|1] "" GTW
 SG_ DAS_sw048_radcMia m48 : 25|1@1+ (1,0) [0|1] "" GTW
 SG_ DAS_sw048_eyeQVersionMismatch m48 : 26|1@1+ (1,0) [0|1] "" GTW
 SG_ DAS_sw048_camIssue m48 : 27|1@1+ (1,0) [0|1] "" GTW
 SG_ DAS_sw048_parkerIssue m48 : 28|1@1+ (1,0) [0|1] "" GTW
 SG_ DAS_sw048_prolongedUiMia m48 : 29|1@1+ (1,0) [0|1] "" GTW
 SG_ DAS_sw048_uiMiaAtBootup m48 : 30|1@1+ (1,0) [0|1] "" GTW
 SG_ DAS_sw049_boot_version_msw m49 : 16|16@1+ (1,0) [0|0] "" GTW
 SG_ DAS_sw049_app_version_msw m49 : 32|16@1+ (1,0) [0|0] "" GTW
 SG_ DAS_sw049_ffs_version_msw m49 : 48|16@1+ (1,0) [0|0] "" GTW
 SG_ DAS_sw050_targetDist m50 : 16|9@1+ (0.2,0) [0|102.2] "m" GTW
 SG_ DAS_sw050_targetRelSpeed m50 : 25|9@1+ (0.0625,-31) [-31|0.9375] "m/s" GTW
 SG_ DAS_sw050_targetOverlap m50 : 34|6@1+ (0.1,0) [0|6.3] "m" GTW
 SG_ DAS_sw050_hostSpeed m50 : 40|8@1+ (1,0) [0|255] "kph" GTW
 SG_ DAS_sw050_hostLongAccel m50 : 48|7@1+ (0.15625,-10) [-10|10] "m/s^2" GTW
 SG_ DAS_sw050_driverPressedAccelPed m50 : 55|1@1+ (1,0) [0|1] "" GTW
 SG_ DAS_sw050_driverPressedBrakePed m50 : 56|1@1+ (1,0) [0|1] "" GTW
 SG_ DAS_sw050_aebEnable m50 : 57|1@1+ (1,0) [0|1] "" GTW
 SG_ DAS_sw050_overrideBlinker m50 : 58|1@1+ (1,0) [0|1] "" GTW
 SG_ DAS_sw050_overrideBrake m50 : 59|1@1+ (1,0) [0|1] "" GTW
 SG_ DAS_sw050_overrideSteer m50 : 60|1@1+ (1,0) [0|1] "" GTW
 SG_ DAS_sw050_fcmModeAtEvent m50 : 61|2@1+ (1,0) [0|3] "" GTW
 SG_ DAS_sw050_accActive m50 : 63|1@1+ (1,0) [0|1] "" GTW
 SG_ DAS_sw051_a01ecuInternalPerf m51 : 16|1@1+ (1,0) [0|1] "" GTW
 SG_ DAS_sw051_a02flashPerformance m51 : 17|1@1+ (1,0) [0|1] "" GTW
 SG_ DAS_sw051_a03vBatHigh m51 : 18|1@1+ (1,0) [0|1] "" GTW
 SG_ DAS_sw051_a09configMismatch m51 : 19|1@1+ (1,0) [0|1] "" GTW
 SG_ DAS_sw051_a52radomeHtrInop m51 : 20|1@1+ (1,0) [0|1] "" GTW
 SG_ DAS_sw051_unused m51 : 21|3@1+ (1,0) [0|1] "" GTW
 SG_ DAS_sw051_SCUTemperature m51 : 24|8@1- (1,0) [-128|127] "" GTW
 SG_ DAS_sw051_HWFail m51 : 32|1@1+ (1,0) [0|1] "" GTW
 SG_ DAS_sw051_SGUFail m51 : 33|1@1+ (1,0) [0|1] "" GTW
 SG_ DAS_sw051_unusedBits m51 : 34|6@1+ (1,0) [0|1] "" GTW
 SG_ DAS_sw051_unusedB0 m51 : 40|8@1+ (1,0) [0|1] "" GTW
 SG_ DAS_sw051_unusedW1 m51 : 48|16@1+ (1,0) [0|1] "" GTW
 SG_ DAS_sw052_a07sensorBlinded m52 : 16|1@1+ (1,0) [0|1] "" GTW
 SG_ DAS_sw052_sensorDirty m52 : 17|1@1+ (1,0) [0|1] "" GTW
 SG_ DAS_sw052_HWFail m52 : 18|1@1+ (1,0) [0|1] "" GTW
 SG_ DAS_sw052_overTemperature m52 : 19|1@1+ (1,0) [0|1] "" GTW
 SG_ DAS_sw052_underTemperature m52 : 20|1@1+ (1,0) [0|1] "" GTW
 SG_ DAS_sw052_chirpError m52 : 21|1@1+ (1,0) [0|1] "" GTW
 SG_ DAS_sw052_rspError m52 : 22|1@1+ (1,0) [0|1] "" GTW
 SG_ DAS_sw052_sensorBlocked m52 : 23|1@1+ (1,0) [0|1] "" GTW
 SG_ DAS_sw053_a10canBusOff m53 : 16|1@1+ (1,0) [0|1] "" GTW
 SG_ DAS_sw053_a11bdyMIA m53 : 17|1@1+ (1,0) [0|1] "" GTW
 SG_ DAS_sw053_a12espMIA m53 : 18|1@1+ (1,0) [0|1] "" GTW
 SG_ DAS_sw053_a13gtwMIA m53 : 19|1@1+ (1,0) [0|1] "" GTW
 SG_ DAS_sw053_a14sccmMIA m53 : 20|1@1+ (1,0) [0|1] "" GTW
 SG_ DAS_sw053_a15adasMIA m53 : 21|1@1+ (1,0) [0|1] "" GTW
 SG_ DAS_sw053_a16bdyInvalidCount m53 : 22|1@1+ (1,0) [0|1] "" GTW
 SG_ DAS_sw053_a17adasInvalidCount m53 : 23|1@1+ (1,0) [0|1] "" GTW
 SG_ DAS_sw053_a18espInvalidCount m53 : 24|1@1+ (1,0) [0|1] "" GTW
 SG_ DAS_sw053_a19sccmInvalidCount m53 : 25|1@1+ (1,0) [0|1] "" GTW
 SG_ DAS_sw053_a20bdyInvalidChkSm m53 : 26|1@1+ (1,0) [0|1] "" GTW
 SG_ DAS_sw053_a21espInvalidChkSm m53 : 27|1@1+ (1,0) [0|1] "" GTW
 SG_ DAS_sw053_a22sccmInvalidChkSm m53 : 28|1@1+ (1,0) [0|1] "" GTW
 SG_ DAS_sw053_a23sccmInvalidChkSm m53 : 29|1@1+ (1,0) [0|1] "" GTW
 SG_ DAS_sw053_a24absValidity m53 : 30|1@1+ (1,0) [0|1] "" GTW
 SG_ DAS_sw053_a25ambTValidity m53 : 31|1@1+ (1,0) [0|1] "" GTW
 SG_ DAS_sw053_a26brakeValidity m53 : 32|1@1+ (1,0) [0|1] "" GTW
 SG_ DAS_sw053_a27CntryCdValidity m53 : 33|1@1+ (1,0) [0|1] "" GTW
 SG_ DAS_sw053_a28espValidity m53 : 34|1@1+ (1,0) [0|0] "" GTW
 SG_ DAS_sw053_a29longAccOffValidity m53 : 35|1@1+ (1,0) [0|1] "" GTW
 SG_ DAS_sw053_a30longAccValidity m53 : 36|1@1+ (1,0) [0|1] "" GTW
 SG_ DAS_sw053_a31odoValidity m53 : 37|1@1+ (1,0) [0|1] "" GTW
 SG_ DAS_sw053_a32gearValidity m53 : 38|1@1+ (1,0) [0|1] "" GTW
 SG_ DAS_sw053_a33steerAngValidity m53 : 39|1@1+ (1,0) [0|1] "" GTW
 SG_ DAS_sw053_a34steerAngSpdValidity m53 : 40|1@1+ (1,0) [0|1] "" GTW
 SG_ DAS_sw053_a35indctrValidity m53 : 41|1@1+ (1,0) [0|1] "" GTW
 SG_ DAS_sw053_a36vehStndStllValidty m53 : 42|1@1+ (1,0) [0|1] "" GTW
 SG_ DAS_sw053_a37vinValidity m53 : 43|1@1+ (1,0) [0|1] "" GTW
 SG_ DAS_sw053_a38whlRotValidity m53 : 44|1@1+ (1,0) [0|1] "" GTW
 SG_ DAS_sw053_a39whlSpdValidity m53 : 45|1@1+ (1,0) [0|1] "" GTW
 SG_ DAS_sw053_a40whlStndStllValidty m53 : 46|1@1+ (1,0) [0|1] "" GTW
 SG_ DAS_sw053_a41wiperValidity m53 : 47|1@1+ (1,0) [0|1] "" GTW
 SG_ DAS_sw053_a42xwdValidity m53 : 48|1@1+ (1,0) [0|1] "" GTW
 SG_ DAS_sw053_a43yawOffValidity m53 : 49|1@1+ (1,0) [0|1] "" GTW
 SG_ DAS_sw053_a44yawValidity m53 : 50|1@1+ (1,0) [0|1] "" GTW
 SG_ DAS_sw053_a48steerAngOffSanity m53 : 51|1@1+ (1,0) [0|1] "" GTW
 SG_ DAS_sw053_a49tireSizeSanity m53 : 52|1@1+ (1,0) [0|1] "" GTW
 SG_ DAS_sw053_a50velocitySanity m53 : 53|1@1+ (1,0) [0|1] "" GTW
 SG_ DAS_sw053_a51yawSanity m53 : 54|1@1+ (1,0) [0|1] "" GTW
 SG_ DAS_sw053_a53espmodValidity m53 : 55|1@1+ (1,0) [0|1] "" GTW
 SG_ DAS_sw053_a54gtwmodValidity m53 : 56|1@1+ (1,0) [0|1] "" GTW
 SG_ DAS_sw053_a55stwmodValidity m53 : 57|1@1+ (1,0) [0|1] "" GTW
 SG_ DAS_sw053_a56bcmodValidity m53 : 58|1@1+ (1,0) [0|1] "" GTW
 SG_ DAS_sw053_a57dimodValidity m53 : 59|1@1+ (1,0) [0|1] "" GTW
 SG_ DAS_sw053_a59drmiInvalidChkSm m53 : 60|1@1+ (1,0) [0|1] "" GTW
 SG_ DAS_sw053_a60drmiInvalidCount m53 : 61|1@1+ (1,0) [0|1] "" GTW
 SG_ DAS_sw053_a61radPositionMismatch m53 : 62|1@1+ (1,0) [0|1] "" GTW
 SG_ DAS_sw053_a62strRackMismatch m53 : 63|1@1+ (1,0) [0|1] "" GTW
 SG_ DAS_sw054_Autofix_cnvrgnceStatus m54 : 16|8@1+ (1,0) [0|0] "" GTW
 SG_ DAS_sw054_Autofix_horizon m54 : 24|8@1+ (1,0) [0|0] "" GTW
 SG_ DAS_sw054_Autofix_yaw m54 : 32|8@1+ (1,0) [0|0] "" GTW
 SG_ DAS_sw054_unusedByte m54 : 40|8@1+ (1,0) [0|0] "" GTW
 SG_ DAS_sw054_unusedW0 m54 : 48|16@1+ (1,0) [0|0] "" GTW
 SG_ DAS_sw055_detectedRadcVersion m55 : 16|32@1+ (1,0) [0|0] "" GTW
 SG_ DAS_sw055_expectedCrcLsw m55 : 48|16@1+ (1,0) [0|0] "" GTW
 SG_ DAS_sw056_diMia m56 : 16|8@1+ (1,0) [0|1] "" GTW
 SG_ DAS_sw056_unusedByte m56 : 24|8@1+ (1,0) [0|0] "" GTW
 SG_ DAS_sw056_espControl m56 : 32|1@1+ (1,0) [0|0] "" GTW
 SG_ DAS_sw056_state2 m56 : 33|1@1+ (1,0) [0|0] "" GTW
 SG_ DAS_sw056_state m56 : 34|1@1+ (1,0) [0|0] "" GTW
 SG_ DAS_sw056_torque1 m56 : 35|1@1+ (1,0) [0|0] "" GTW
 SG_ DAS_sw056_torque2 m56 : 36|1@1+ (1,0) [0|0] "" GTW
 SG_ DAS_sw057_chCtrlMia m57 : 32|1@1+ (1,0) [0|1] "" GTW
 SG_ DAS_sw057_csaOfframpCurvMia m57 : 33|1@1+ (1,0) [0|1] "" GTW
 SG_ DAS_sw057_csaRoadCurvMia m57 : 34|1@1+ (1,0) [0|1] "" GTW
 SG_ DAS_sw057_dasControlMia m57 : 35|1@1+ (1,0) [0|1] "" GTW
 SG_ DAS_sw057_dasMapDataMia m57 : 36|1@1+ (1,0) [0|1] "" GTW
 SG_ DAS_sw057_gpsVehSpeedMia m57 : 37|1@1+ (1,0) [0|1] "" GTW
 SG_ DAS_sw057_locStatusMia m57 : 38|1@1+ (1,0) [0|1] "" GTW
 SG_ DAS_sw057_radarMapDataMia m57 : 39|1@1+ (1,0) [0|1] "" GTW
 SG_ DAS_sw057_roadCurvMia m57 : 40|1@1+ (1,0) [0|1] "" GTW
 SG_ DAS_sw057_solarDataMia m57 : 41|1@1+ (1,0) [0|1] "" GTW
 SG_ DAS_sw057_telemetryControlMia m57 : 42|1@1+ (1,0) [0|1] "" GTW
 SG_ DAS_sw057_statusMia m57 : 43|1@1+ (1,0) [0|1] "" GTW
 SG_ DAS_sw057_autopilotControlMia m57 : 44|1@1+ (1,0) [0|1] "" GTW
 SG_ DAS_sw057_phoneLocStatusMia m57 : 45|1@1+ (1,0) [0|1] "" GTW
 SG_ DAS_sw058_epbMia m58 : 16|8@1+ (1,0) [0|1] "" GTW
 SG_ DAS_sw058_unusedByte m58 : 24|8@1+ (1,0) [0|0] "" GTW
 SG_ DAS_sw058_status m58 : 32|1@1+ (1,0) [0|0] "" GTW
 SG_ DAS_sw059_parkMia m59 : 16|8@1+ (1,0) [0|1] "" GTW
 SG_ DAS_sw059_unusedByte m59 : 24|8@1+ (1,0) [0|0] "" GTW
 SG_ DAS_sw059_oloDict m59 : 32|1@1+ (1,0) [0|0] "" GTW
 SG_ DAS_sw059_oocStatus m59 : 33|1@1+ (1,0) [0|0] "" GTW
 SG_ DAS_sw059_pasFrontMiddle m59 : 34|1@1+ (1,0) [0|0] "" GTW
 SG_ DAS_sw059_pasRearMiddle m59 : 35|1@1+ (1,0) [0|0] "" GTW
 SG_ DAS_sw059_pscStatus m59 : 36|1@1+ (1,0) [0|0] "" GTW
 SG_ DAS_sw059_pscVehSlot m59 : 37|1@1+ (1,0) [0|0] "" GTW
 SG_ DAS_sw059_sdiFront m59 : 38|1@1+ (1,0) [0|0] "" GTW
 SG_ DAS_sw059_sdiRear m59 : 39|1@1+ (1,0) [0|0] "" GTW
 SG_ DAS_sw059_sensorStatusFront m59 : 40|1@1+ (1,0) [0|0] "" GTW
 SG_ DAS_sw059_sensorStatusRear m59 : 41|1@1+ (1,0) [0|0] "" GTW
 SG_ DAS_sw059_status2 m59 : 42|1@1+ (1,0) [0|0] "" GTW
 SG_ DAS_sw059_status m59 : 43|1@1+ (1,0) [0|0] "" GTW
 SG_ DAS_sw060_targetDist m60 : 16|9@1+ (0.2,0) [0|102.2] "m" GTW
 SG_ DAS_sw060_targetRelSpeed m60 : 25|9@1+ (0.0625,-31) [-31|0.9375] "m/s" GTW
 SG_ DAS_sw060_targetOverlap m60 : 34|6@1+ (0.1,0) [0|6.3] "m" GTW
 SG_ DAS_sw060_hostSpeed m60 : 40|7@1+ (2,0) [0|254] "kph" GTW
 SG_ DAS_sw060_hostLongAccel m60 : 47|4@1+ (1,-7.5) [-7.5|7.5] "m/s^2" GTW
 SG_ DAS_sw060_RadarAssociationAge m60 : 51|4@1+ (100,0) [0|1500] "ms" GTW
 SG_ DAS_sw060_driverPressedBrakePed m60 : 55|1@1+ (1,0) [0|1] "" GTW
 SG_ DAS_sw060_overrideAccelPed m60 : 56|1@1+ (1,0) [0|1] "" GTW
 SG_ DAS_sw060_overrideBlinker m60 : 57|1@1+ (1,0) [0|1] "" GTW
 SG_ DAS_sw060_overrideBrake m60 : 58|1@1+ (1,0) [0|1] "" GTW
 SG_ DAS_sw060_overrideSteer m60 : 59|1@1+ (1,0) [0|1] "" GTW
 SG_ DAS_sw060_collisionWarningSource m60 : 60|3@1+ (1,0) [0|7] "" GTW
 SG_ DAS_sw060_accActive m60 : 63|1@1+ (1,0) [0|1] "" GTW
 SG_ DAS_sw061_airSuspensionMia m61 : 16|8@1+ (1,0) [0|1] "" GTW
 SG_ DAS_sw061_unusedByte m61 : 24|8@1+ (1,0) [0|0] "" GTW
 SG_ DAS_sw061_asdA2 m61 : 32|1@1+ (1,0) [0|0] "" GTW
 SG_ DAS_sw061_states m61 : 33|1@1+ (1,0) [0|0] "" GTW
 SG_ DAS_sw062_HorizontalMisalignment m62 : 16|16@1+ (0.00137332,-45) [-45|45.0005262] "deg" GTW
 SG_ DAS_sw062_VerticalMisalignment m62 : 32|10@1+ (0.087977,-45) [-45|45.000471] "deg" GTW
 SG_ DAS_sw062_unusedBits m62 : 42|6@1+ (1,0) [0|1] "" GTW
 SG_ DAS_sw062_VmaPlausibility m62 : 48|16@1+ (1.52587890625005E-05,0) [0|0.99998474121097] "" GTW
 SG_ DAS_sw063_expectedMajorVer m63 : 16|8@1+ (1,0) [0|255] "" GTW
 SG_ DAS_sw063_detectedMajorVer m63 : 24|8@1+ (1,0) [0|255] "" GTW
 SG_ DAS_sw063_expectedMinorVer m63 : 32|8@1+ (1,0) [0|255] "" GTW
 SG_ DAS_sw063_detectedMinorVer m63 : 40|8@1+ (1,0) [0|255] "" GTW
 SG_ DAS_sw063_expectedSubMinorVer m63 : 48|8@1+ (1,0) [0|255] "" GTW
 SG_ DAS_sw063_detectedSubMinorVer m63 : 56|8@1+ (1,0) [0|255] "" GTW
 SG_ DAS_sw064_epasMia m64 : 16|8@1+ (1,0) [0|1] "" GTW
 SG_ DAS_sw064_unusedByte m64 : 24|8@1+ (1,0) [0|0] "" GTW
 SG_ DAS_sw064_sysStatus m64 : 32|1@1+ (1,0) [0|0] "" GTW
 SG_ DAS_sw065_app_mobileye_status m65 : 16|8@1+ (1,0) [0|21] "" GTW
 SG_ DAS_sw065_mobileye_main_state m65 : 24|8@1+ (1,0) [0|255] "" GTW
 SG_ DAS_sw065_unusedW0 m65 : 32|16@1+ (1,0) [0|0] "" GTW
 SG_ DAS_sw065_unusedW1 m65 : 48|16@1+ (1,0) [0|0] "" GTW
 SG_ DAS_sw066_app_mobileye_status m66 : 16|8@1+ (1,0) [0|21] "" GTW
 SG_ DAS_sw066_mobileye_main_state m66 : 24|8@1+ (1,0) [0|255] "" GTW
 SG_ DAS_sw066_unusedW0 m66 : 32|16@1+ (1,0) [0|0] "" GTW
 SG_ DAS_sw066_unusedW1 m66 : 48|16@1+ (1,0) [0|0] "" GTW
 SG_ DAS_sw067_sccmSTW m67 : 16|14@1+ (0.1,-819.2) [-819.2|819] "deg" GTW
 SG_ DAS_sw067_epasSTW m67 : 30|14@1+ (0.1,-819.2) [-819.2|819] "deg" GTW
 SG_ DAS_sw067_vehSpeed m67 : 44|12@1+ (0.1,-50) [-50|359.6] "kph" GTW
 SG_ DAS_sw067_offsetEstimator m67 : 56|8@1+ (0.1,-12.8) [-12.8|12.8] "deg" GTW
 SG_ DAS_sw068_percentConsistency m68 : 16|10@1+ (0.1,0) [0|100] "%" GTW
 SG_ DAS_sw068_virtualLaneSTW m68 : 32|14@1+ (0.1,-819.2) [-819.2|819.2] "deg" GTW
 SG_ DAS_sw068_navigationSTW m68 : 48|14@1+ (0.1,-819.2) [-819.2|819.2] "deg" GTW
 SG_ DAS_sw069_epasMia m69 : 16|1@1+ (1,0) [0|1] "" GTW
 SG_ DAS_sw069_espMia m69 : 17|1@1+ (1,0) [0|1] "" GTW
 SG_ DAS_sw069_parkMia m69 : 18|1@1+ (1,0) [0|1] "" GTW
 SG_ DAS_sw069_sccmMia m69 : 19|1@1+ (1,0) [0|1] "" GTW
 SG_ DAS_sw069_parkMismatch m69 : 20|1@1+ (1,0) [0|1] "" GTW
 SG_ DAS_sw069_eacStatus m69 : 21|4@1+ (1,0) [0|1] "" GTW
 SG_ DAS_sw069_diAPState m69 : 25|4@1+ (1,0) [0|1] "" GTW
 SG_ DAS_sw069_parkCal m69 : 29|1@1+ (1,0) [0|1] "" GTW
 SG_ DAS_sw069_torsionBar m69 : 32|12@1+ (0.01,-20.5) [-20.5|20.45] "Nm" GTW
 SG_ DAS_sw069_roadClass m69 : 44|4@1+ (1,0) [0|15] "" GTW
 SG_ DAS_sw069_drivingLaneLeft m69 : 48|8@1+ (1,0) [0|255] "" GTW
 SG_ DAS_sw069_drivingLaneRight m69 : 56|8@1+ (1,0) [0|255] "" GTW
 SG_ DAS_sw070_currTireFitment m70 : 16|3@1+ (1,0) [0|7] "" GTW
 SG_ DAS_sw070_lastTireFitment m70 : 19|3@1+ (1,0) [0|7] "" GTW
 SG_ DAS_sw070_diGear m70 : 22|3@1+ (1,0) [0|7] "" GTW
 SG_ DAS_sw070_driveRail m70 : 25|1@1+ (1,0) [0|1] "" GTW
 SG_ DAS_sw070_accRail m70 : 26|1@1+ (1,0) [0|1] "" GTW
 SG_ DAS_sw070_temperature m70 : 32|8@1+ (0.5,-40) [-40|87.5] "C" GTW
 SG_ DAS_sw070_currentSpeed m70 : 40|12@1+ (0.1,-204.7) [-204.7|204.8] "mph" GTW
 SG_ DAS_sw071_selfParkType m71 : 16|4@1+ (1,0) [0|15] "" GTW
 SG_ DAS_sw071_endPosX m71 : 20|10@1+ (0.05,-25.6) [-25.6|25.5] "m" GTW
 SG_ DAS_sw071_endPosY m71 : 30|10@1+ (0.05,-25.6) [-25.6|25.5] "m" GTW
 SG_ DAS_sw071_roadClass m71 : 40|3@1+ (1,0) [0|7] "" GTW
 SG_ DAS_sw071_driverPresent m71 : 43|1@1+ (1,0) [0|1] "" GTW
 SG_ DAS_sw071_airSuspension m71 : 44|3@1+ (1,0) [0|7] "" GTW
 SG_ DAS_sw071_temperature m71 : 47|8@1+ (0.5,-40) [-40|87.5] "C" GTW
 SG_ DAS_sw071_activationType m71 : 55|2@1+ (1,0) [0|3] "" GTW
 SG_ DAS_sw072_vehicleX m72 : 16|10@1+ (0.05,-25.6) [-25.6|25.5] "m" GTW
 SG_ DAS_sw072_vehicleY m72 : 26|10@1+ (0.05,-25.6) [-25.6|25.5] "m" GTW
 SG_ DAS_sw072_vehicleHeading m72 : 36|10@1+ (0.005,-2.56) [-2.56|2.55] "rad" GTW
 SG_ DAS_sw072_endDistance m72 : 46|8@1+ (1,0) [0|255] "cm" GTW
 SG_ DAS_sw072_guidanceComplete m72 : 54|1@1+ (1,0) [0|1] "" GTW
 SG_ DAS_sw072_guidanceRunaway m72 : 55|1@1+ (1,0) [0|1] "" GTW
 SG_ DAS_sw072_guidanceTimer m72 : 56|1@1+ (1,0) [0|1] "" GTW
 SG_ DAS_sw072_handlePress m72 : 57|1@1+ (1,0) [0|1] "" GTW
 SG_ DAS_sw072_keyfobPress m72 : 58|1@1+ (1,0) [0|1] "" GTW
 SG_ DAS_sw072_garageOpened m72 : 59|1@1+ (1,0) [0|1] "" GTW
 SG_ DAS_sw072_userTimeout m72 : 60|1@1+ (1,0) [0|1] "" GTW
 SG_ DAS_sw073_escalateLDWs m73 : 16|1@1+ (1,0) [0|1] "" GTW
 SG_ DAS_sw073_silentEscalatedLDW m73 : 17|1@1+ (1,0) [0|1] "" GTW
 SG_ DAS_sw073_escalateLDWreason m73 : 18|2@1+ (1,0) [0|3] "" GTW
 SG_ DAS_sw073_rawMobileyeLDW m73 : 20|2@1+ (1,0) [0|3] "" GTW
 SG_ DAS_sw073_freespaceLDW m73 : 22|2@1+ (1,0) [0|3] "" GTW
 SG_ DAS_sw073_freespaceLeftC0 m73 : 24|8@1+ (0.1,-12.8) [-12.8|12.7] "m" GTW
 SG_ DAS_sw073_freespaceRightC0 m73 : 32|8@1+ (0.1,-12.8) [-12.8|12.7] "m" GTW
 SG_ DAS_sw073_freespaceLeftC1 m73 : 40|8@1+ (0.0016,-0.2) [-0.2|0.2] "rad" GTW
 SG_ DAS_sw073_freespaceRightC1 m73 : 48|8@1+ (0.0016,-0.2) [-0.2|0.2] "rad" GTW
 SG_ DAS_sw073_freespaceLeftFarZ m73 : 56|4@1+ (4,0) [0|60] "m" GTW
 SG_ DAS_sw073_freespaceRightFarZ m73 : 60|4@1+ (4,0) [0|60] "m" GTW
 SG_ DAS_sw074_ipsoDx m74 : 16|6@1+ (2,0) [0|126] "m" GTW
 SG_ DAS_sw074_ipsoDy m74 : 22|6@1+ (0.1,-3.2) [-3.2|3.1] "m" GTW
 SG_ DAS_sw074_ipsoDz m74 : 28|6@1+ (0.2,-6.4) [-6.4|6.2] "m" GTW
 SG_ DAS_sw074_ipsoRCS m74 : 34|8@1+ (1,0) [0|255] "db" GTW
 SG_ DAS_sw074_ipsoConfidence m74 : 42|6@1+ (2,0) [0|126] "percent" GTW
 SG_ DAS_sw074_ipsowExist m74 : 48|5@1+ (1,0) [0|31] "" GTW
 SG_ DAS_sw074_roadClass m74 : 54|3@1+ (1,0) [0|7] "" GTW
 SG_ DAS_sw074_cruiseActive m74 : 57|1@1+ (1,0) [0|1] "" GTW
 SG_ DAS_sw074_autopilotActive m74 : 58|1@1+ (1,0) [0|1] "" GTW
 SG_ DAS_sw075_scMia m75 : 16|8@1+ (1,0) [0|255] "" GTW
 SG_ DAS_sw075_unusedByte m75 : 24|8@1+ (1,0) [0|0] "" GTW
 SG_ DAS_sw075_status m75 : 32|1@1+ (1,0) [0|0] "" GTW
 SG_ DAS_sw076_targetDist m76 : 16|9@1+ (0.2,0) [0|102.2] "m" GTW
 SG_ DAS_sw076_targetRelSpeed m76 : 25|9@1+ (0.0625,-31) [-31|0.9375] "m/s" GTW
 SG_ DAS_sw076_targetOverlap m76 : 34|6@1+ (0.1,0) [0|6.3] "m" GTW
 SG_ DAS_sw076_hostSpeed m76 : 40|8@1+ (1,0) [0|255] "kph" GTW
 SG_ DAS_sw076_hostLongAccel m76 : 48|7@1+ (0.15625,-10) [-10|10] "m/s^2" GTW
 SG_ DAS_sw076_driverPressedAccelPed m76 : 55|1@1+ (1,0) [0|1] "" GTW
 SG_ DAS_sw076_driverPressedBrakePed m76 : 56|1@1+ (1,0) [0|1] "" GTW
 SG_ DAS_sw076_overrideAccelPed m76 : 57|1@1+ (1,0) [0|1] "" GTW
 SG_ DAS_sw076_overrideBlinker m76 : 58|1@1+ (1,0) [0|1] "" GTW
 SG_ DAS_sw076_overrideBrake m76 : 59|1@1+ (1,0) [0|1] "" GTW
 SG_ DAS_sw076_overrideSteer m76 : 60|1@1+ (1,0) [0|1] "" GTW
 SG_ DAS_sw076_fcmModeAtEvent m76 : 61|2@1+ (1,0) [0|3] "" GTW
 SG_ DAS_sw076_accActive m76 : 63|1@1+ (1,0) [0|1] "" GTW
 SG_ DAS_sw077_oocDistance m77 : 16|9@1+ (1,0) [0|512] "cm" GTW
 SG_ DAS_sw077_oocConfidence m77 : 25|7@1+ (1,0) [0|100] "%" GTW
 SG_ DAS_sw077_oocCollisionSide m77 : 32|3@1+ (1,0) [0|7] "" GTW
 SG_ DAS_sw077_oocHeight m77 : 35|2@1+ (1,0) [0|4] "" GTW
 SG_ DAS_sw077_vehicleSpeed m77 : 37|10@1+ (0.05,-25) [-25|26.15] "MPH" GTW
 SG_ DAS_sw077_oocUntrackedTime m77 : 48|6@1+ (0.1,0) [0|6.3] "s" GTW
 SG_ DAS_sw077_oocOffCourseDist_cm m77 : 54|10@1- (1,0) [-512|511] "" GTW
 SG_ DAS_sw078_camCipv_dx m78 : 16|8@1+ (0.2,0) [0|51] "m" GTW
 SG_ DAS_sw078_ttc m78 : 24|8@1+ (0.02,0) [0|5.11] "seconds" GTW
 SG_ DAS_sw078_radarTarg5_dx m78 : 32|8@1+ (0.0625,0) [0|15.9375] "m" GTW
 SG_ DAS_sw078_radarTarg5_VxRel m78 : 40|8@1+ (0.2,-25.6) [-25.6|25.4] "m/s" GTW
 SG_ DAS_sw078_radarTarg1_dx m78 : 48|8@1+ (0.0625,0) [0|15.9375] "m" GTW
 SG_ DAS_sw078_radarTarg1_VxRel m78 : 56|8@1+ (0.2,-25.6) [-25.6|25.4] "m/s" GTW
 SG_ DAS_sw080_sensors_healty_check m80 : 16|1@1+ (1,0) [0|1] "" GTW
 SG_ DAS_sw080_dist_travelled_check m80 : 17|1@1+ (1,0) [0|1] "" GTW
 SG_ DAS_sw080_road_class_check m80 : 18|1@1+ (1,0) [0|1] "" GTW
 SG_ DAS_sw080_stw_angle_check m80 : 19|1@1+ (1,0) [0|1] "" GTW
 SG_ DAS_sw080_rad_tar_5_check m80 : 20|1@1+ (1,0) [0|1] "" GTW
 SG_ DAS_sw080_ultrasonic_obs_check m80 : 21|1@1+ (1,0) [0|1] "" GTW
 SG_ DAS_sw080_freespace_check m80 : 22|1@1+ (1,0) [0|1] "" GTW
 SG_ DAS_sw080_pedestrian_check m80 : 23|1@1+ (1,0) [0|1] "" GTW
 SG_ DAS_sw080_rad_tar_5_dist m80 : 24|6@1+ (1,0) [0|63] "m" GTW
 SG_ DAS_sw080_stw_angle_deg m80 : 32|8@1+ (1,0) [0|255] "deg" GTW
 SG_ DAS_sw080_road_class m80 : 40|3@1+ (1,0) [0|7] "" GTW
 SG_ DAS_sw080_ego_speed m80 : 43|5@1+ (1,0) [0|31] "mph" GTW
 SG_ DAS_sw080_cipv_valid m80 : 48|1@1+ (1,0) [0|1] "" GTW
 SG_ DAS_sw080_min_speed_check m80 : 49|1@1+ (1,0) [0|1] "" GTW
 SG_ DAS_sw080_cruise_lever_state m80 : 50|3@1+ (1,0) [0|7] "" GTW
 SG_ DAS_sw080_cruise_speed_check m80 : 53|1@1+ (1,0) [0|1] "" GTW
 SG_ DAS_sw081_radarDistance m81 : 16|8@1+ (0.0625,0) [0|15.9375] "m" GTW
 SG_ DAS_sw081_radarTTC m81 : 24|8@1+ (0.02,0) [0|5.11] "seconds" GTW
 SG_ DAS_sw081_cameraDistance m81 : 32|8@1+ (0.0625,0) [0|15.9375] "m" GTW
 SG_ DAS_sw081_cameraTTC m81 : 40|8@1+ (0.02,0) [0|5.11] "seconds" GTW
 SG_ DAS_sw081_pedalPosition m81 : 48|7@1+ (1,0) [0|127] "%" GTW
 SG_ DAS_sw082_L_VL m82 : 16|8@1+ (0.05,-6.4) [-6.4|6.35] "m" GTW
 SG_ DAS_sw082_R_VL m82 : 24|8@1+ (0.05,-6.4) [-6.4|6.35] "m" GTW
 SG_ DAS_sw082_L_Lane m82 : 32|8@1+ (0.05,-6.4) [-6.4|6.35] "m" GTW
 SG_ DAS_sw082_R_Lane m82 : 40|8@1+ (0.05,-6.4) [-6.4|6.35] "m" GTW
 SG_ DAS_sw082_road_class m82 : 48|3@1+ (1,0) [0|7] "" GTW
 SG_ DAS_sw083_Targ5_RCS m83 : 16|16@1+ (0.0039063096,0) [0|256] "dB" GTW
 SG_ DAS_sw083_Targ5_dx m83 : 32|12@1+ (0.0625,0) [0|255.9375] "m" GTW
 SG_ DAS_sw083_Targ5_dz m83 : 44|6@1+ (0.25,-5) [-5|10.75] "m" GTW
 SG_ DAS_sw083_Targ5_wObj m83 : 50|5@1+ (0.03125,0) [0|0.96875] "%" GTW
 SG_ DAS_sw083_Targ5_wNonObj m83 : 55|5@1+ (0.03125,0) [0|0.96875] "%" GTW
 SG_ DAS_sw084_ipsoTTC m84 : 16|8@1+ (0.02,0) [0|5.11] "seconds" GTW
 SG_ DAS_sw084_ipsoDx m84 : 24|8@1+ (0.1,0) [0|25.5] "m" GTW
 SG_ DAS_sw084_ipsoRCS m84 : 32|8@1+ (1,0) [0|255] "" GTW
 SG_ DAS_sw084_ipsoDy m84 : 40|8@1+ (0.1,-12.6) [-12.6|12.8] "m" GTW
 SG_ DAS_sw085_radarDistance m85 : 16|8@1+ (0.0625,0) [0|15.9375] "m" GTW
 SG_ DAS_sw085_radarTTC m85 : 24|8@1+ (0.02,0) [0|5.11] "seconds" GTW
 SG_ DAS_sw085_roadClass m85 : 32|3@1+ (1,0) [0|7] "" GTW
 SG_ DAS_sw085_leftLaneExist m85 : 36|6@1+ (2,0) [0|128] "%" GTW
 SG_ DAS_sw085_rightLaneExist m85 : 42|6@1+ (2,0) [0|128] "%" GTW
 SG_ DAS_sw085_averageSpeedHist m85 : 48|6@1+ (0.25,0) [0|16] "mps" GTW
 SG_ DAS_sw085_freeSpaceC0Left m85 : 54|5@1+ (1,-15) [-15|16] "m" GTW
 SG_ DAS_sw085_freeSpaceC0Right m85 : 59|5@1+ (1,-15) [-15|16] "m" GTW
 SG_ DAS_sw086_distanceException m86 : 16|8@1+ (1,-90) [90|165] "m" GTW
 SG_ DAS_sw086_distanceEllipse m86 : 24|8@1+ (0.5,0) [0|127.5] "m" GTW
 SG_ DAS_sw086_ellipseWidth m86 : 32|8@1+ (0.1,0) [0|25.5] "m" GTW
 SG_ DAS_sw086_ellipseOverlap m86 : 40|8@1+ (0.1,-12.5) [-12.5|12.5] "m" GTW
 SG_ DAS_sw086_ellipseAge m86 : 48|3@1+ (1,0) [0|7] "" GTW
 SG_ DAS_sw086_activeBraking m86 : 51|1@1+ (1,0) [0|1] "" GTW
 SG_ DAS_sw086_cipvValid m86 : 52|1@1+ (1,0) [0|1] "" GTW
 SG_ DAS_sw086_mcvlValid m86 : 53|1@1+ (1,0) [0|1] "" GTW
 SG_ DAS_sw086_mcvrValid m86 : 54|1@1+ (1,0) [0|1] "" GTW
 SG_ DAS_sw086_roadClass m86 : 55|3@1+ (1,0) [0|7] "" GTW
 SG_ DAS_sw086_ipsoApproved m86 : 58|1@1+ (1,0) [0|1] "" GTW
 SG_ DAS_sw086_controlledAccess m86 : 59|1@1+ (1,0) [0|1] "" GTW
 SG_ DAS_sw086_driverHandsOn m86 : 60|1@1+ (1,0) [0|1] "" GTW
 SG_ DAS_sw103_objectDx m103 : 16|8@1+ (0.5,0) [0|127.5] "m" GTW
 SG_ DAS_sw103_objectRCS m103 : 24|8@1+ (1,0) [0|255] "" GTW
 SG_ DAS_sw103_objectDy m103 : 32|8@1+ (0.5,-15.5) [-15.5|16] "m" GTW
 SG_ DAS_sw103_objectDz m103 : 40|8@1+ (0.25,-5) [-5|10.75] "m" GTW
 SG_ DAS_sw103_distanceEllipse m103 : 48|8@1+ (0.5,0) [0|127.5] "m" GTW
 SG_ DAS_sw103_ipsoApproved m103 : 56|1@1+ (1,0) [0|1] "" GTW
 SG_ DAS_sw103_constArea m103 : 57|2@1+ (1,0) [0|3] "" GTW
 SG_ DAS_sw103_radAlignment m103 : 59|5@1+ (0.015625,-0.2343) [-0.2343|0.25] "rad" GTW
 SG_ DAS_sw106_torsionBarOffset m106 : 16|8@1+ (0.005,-0.64) [-0.64|0.63] "Nm" GTW
 SG_ DAS_sw193_outOfFocusImage m193 : 16|1@1+ (1,0) [0|1] "" GTW
 SG_ DAS_sw193_impairedVD m193 : 17|1@1+ (1,0) [0|1] "" GTW
 SG_ DAS_sw193_blurredImage m193 : 18|1@1+ (1,0) [0|1] "" GTW
 SG_ DAS_sw193_smearedSpots m193 : 19|1@1+ (1,0) [0|1] "" GTW
 SG_ DAS_sw193_partialBlockage m193 : 20|1@1+ (1,0) [0|1] "" GTW
 SG_ DAS_sw193_fullBlockage m193 : 21|1@1+ (1,0) [0|1] "" GTW
 SG_ DAS_sw193_smearedHalos m193 : 22|1@1+ (1,0) [0|1] "" GTW
 SG_ DAS_sw194_numObstacles m194 : 16|4@1+ (1,0) [0|7] "" GTW
 SG_ DAS_sw194_numPedstrian m194 : 20|4@1+ (1,0) [0|7] "" GTW
 SG_ DAS_sw194_timeInHold m194 : 31|16@0+ (1,0) [0|1] "" GTW
 SG_ DAS_sw194_leadDx m194 : 40|8@1+ (0.1,0) [0|25] "m" GTW
 SG_ DAS_sw194_leadVx m194 : 48|6@1- (0.2,0) [-6|6] "m/s" GTW
 SG_ DAS_sw194_leadAx m194 : 54|6@1- (0.2,0) [-6|6] "m/s^2" GTW
 SG_ DAS_sw194_reasonForHold m194 : 60|4@1+ (1,0) [0|15] "" GTW
 SG_ DAS_sw195_sdiSystemStatus m195 : 16|1@1+ (1,0) [0|1] "" GTW
 SG_ DAS_sw195_sdiSystemNoise m195 : 17|2@1+ (1,0) [0|3] "" GTW
 SG_ DAS_sw195_sdiFrontCC m195 : 24|5@1+ (1,0) [0|31] "" GTW
 SG_ DAS_sw195_s1Blocked m195 : 29|1@1+ (1,0) [0|1] "" GTW
 SG_ DAS_sw195_s6Blocked m195 : 30|1@1+ (1,0) [0|1] "" GTW
 SG_ DAS_sw195_s7Blocked m195 : 31|1@1+ (1,0) [0|1] "" GTW
 SG_ DAS_sw195_sdiRearCC m195 : 32|5@1+ (1,0) [0|31] "" GTW
 SG_ DAS_sw195_s11Blocked m195 : 37|1@1+ (1,0) [0|1] "" GTW
 SG_ DAS_sw195_s12Blocked m195 : 38|1@1+ (1,0) [0|1] "" GTW
 SG_ DAS_sw195_s8Blocked m195 : 39|1@1+ (1,0) [0|1] "" GTW
 SG_ DAS_sw195_vehicleSpeed m195 : 40|12@1+ (0.1,0) [0|409.6] "kph" GTW
 SG_ DAS_sw198_tsrMsgInvalid m198 : 16|1@1+ (1,0) [0|1] "" GTW
 SG_ DAS_sw198_tflMsgInvalid m198 : 17|1@1+ (1,0) [0|1] "" GTW
 SG_ DAS_sw198_partialBlockage m198 : 18|1@1+ (1,0) [0|1] "" GTW
 SG_ DAS_sw198_fullBlockage m198 : 19|1@1+ (1,0) [0|1] "" GTW
 SG_ DAS_sw199_numShifts m199 : 16|4@1+ (1,0) [0|15] "" GTW
 SG_ DAS_sw199_internalState m199 : 20|4@1+ (1,0) [0|15] "" GTW
 SG_ DAS_sw199_abortCodePARK m199 : 24|5@1+ (1,0) [0|15] "" GTW
 SG_ DAS_sw199_currentSTW m199 : 29|14@1+ (0.1,-819.2) [-819.2|819] "deg" GTW
 SG_ DAS_sw199_abortCodeDas m199 : 43|5@1+ (1,0) [0|31] "" GTW
 SG_ DAS_sw199_maxSpeed m199 : 48|8@1+ (0.1,-12.2) [-12.2|12.2] "mph" GTW
 SG_ DAS_sw199_currentSpeed m199 : 56|8@1+ (0.1,-12.2) [-12.2|12.2] "mph" GTW
 SG_ DAS_sw200_startSpeed m200 : 16|10@1+ (0.1,-50) [-10|92.3] "m/s" GTW
 SG_ DAS_sw200_endSpeed m200 : 26|10@1+ (0.1,-50) [-10|92.3] "m/s" GTW
 SG_ DAS_sw200_epasHandsOnDetected m200 : 36|1@1+ (1,0) [0|1] "" GTW
 SG_ DAS_sw200_autopilotRestricted m200 : 37|1@1+ (1,0) [0|1] "" GTW
 SG_ DAS_sw200_autopilotIntState m200 : 40|4@1+ (1,0) [0|1] "" GTW
 SG_ DAS_sw201_timeHorizon m201 : 16|8@1+ (0.1,0) [0|25.5] "s" GTW
 SG_ DAS_sw201_vehSpeed m201 : 24|8@1+ (1,0) [0|255] "kph" GTW
 SG_ DAS_sw201_stwAngleReq m201 : 32|8@1- (1,0) [-128|127] "deg" GTW
 SG_ DAS_sw201_viewRangeOAL m201 : 43|3@1+ (1,0) [0|5] "" GTW
 SG_ DAS_sw201_steeringErrorOAL m201 : 55|3@1+ (1,0) [0|5] "" GTW
 SG_ DAS_sw201_virtualLaneInputOAL m201 : 61|3@1+ (1,0) [0|5] "" GTW
 SG_ DAS_sw202_sdiSystemStatus m202 : 16|1@1+ (1,0) [0|1] "" GTW
 SG_ DAS_sw202_sdiSystemNoise m202 : 17|2@1+ (1,0) [0|3] "" GTW
 SG_ DAS_sw202_sdiFrontCC m202 : 24|5@1+ (1,0) [0|31] "" GTW
 SG_ DAS_sw202_s1Blocked m202 : 29|1@1+ (1,0) [0|1] "" GTW
 SG_ DAS_sw202_s6Blocked m202 : 30|1@1+ (1,0) [0|1] "" GTW
 SG_ DAS_sw202_s7Blocked m202 : 31|1@1+ (1,0) [0|1] "" GTW
 SG_ DAS_sw202_sdiRearCC m202 : 32|5@1+ (1,0) [0|31] "" GTW
 SG_ DAS_sw202_s8Blocked m202 : 37|1@1+ (1,0) [0|1] "" GTW
 SG_ DAS_sw202_s11Blocked m202 : 38|1@1+ (1,0) [0|1] "" GTW
 SG_ DAS_sw202_s12Blocked m202 : 39|1@1+ (1,0) [0|1] "" GTW
 SG_ DAS_sw202_vehicleSpeed m202 : 40|12@1+ (0.1,0) [0|409.6] "kph" GTW
 SG_ DAS_sw203_slotSizeX m203 : 16|8@1+ (4,0) [0|1020] "cm" GTW
 SG_ DAS_sw203_slotSizeY m203 : 24|8@1+ (4,0) [0|1020] "cm" GTW
 SG_ DAS_sw203_startDistance m203 : 32|11@1+ (1,0) [0|2047] "cm" GTW
 SG_ DAS_sw203_roadClass m203 : 43|3@1+ (1,0) [0|7] "" GTW
 SG_ DAS_sw203_curbType m203 : 46|2@1+ (1,0) [0|3] "" GTW
 SG_ DAS_sw203_controlType m203 : 48|4@1+ (1,0) [0|15] "" GTW
 SG_ DAS_sw203_vehicleSkew m203 : 52|12@1+ (0.002,0) [0|8.19] "radians" GTW
 SG_ DAS_sw204_frLeftMiddle m204 : 16|8@1+ (1,0) [0|255] "cm" GTW
 SG_ DAS_sw204_frRightMiddle m204 : 24|8@1+ (1,0) [0|255] "cm" GTW
 SG_ DAS_sw204_frRight m204 : 32|8@1+ (1,0) [0|255] "cm" GTW
 SG_ DAS_sw204_frLeft m204 : 40|8@1+ (1,0) [0|255] "cm" GTW
 SG_ DAS_sw204_frMiddle m204 : 48|8@1+ (1,0) [0|255] "cm" GTW
 SG_ DAS_sw204_maxSpeed m204 : 56|8@1+ (0.1,-12.2) [-12.2|12.2] "mph" GTW
 SG_ DAS_sw205_rrRightMiddle m205 : 16|8@1+ (1,0) [0|255] "cm" GTW
 SG_ DAS_sw205_rrLeftMiddle m205 : 24|8@1+ (1,0) [0|255] "cm" GTW
 SG_ DAS_sw205_rrRight m205 : 32|8@1+ (1,0) [0|255] "cm" GTW
 SG_ DAS_sw205_rrLeft m205 : 40|8@1+ (1,0) [0|255] "cm" GTW
 SG_ DAS_sw205_rrMiddle m205 : 48|8@1+ (1,0) [0|255] "cm" GTW
 SG_ DAS_sw205_oocDistance m205 : 56|8@1+ (1,0) [0|255] "cm" GTW
 SG_ DAS_sw207_lcUnavailableReason m207 : 16|8@1+ (1,0) [0|255] "" GTW
 SG_ DAS_sw207_appMobileyeStatus m207 : 24|8@1+ (1,0) [0|255] "" GTW
 SG_ DAS_sw207_eyeq3MainState m207 : 32|8@1+ (1,0) [0|255] "" GTW
 SG_ DAS_sw213_startSpeed m213 : 16|10@1+ (0.1,-50) [-10|92.3] "m/s" GTW
 SG_ DAS_sw213_endSpeed m213 : 26|10@1+ (0.1,-50) [-10|92.3] "m/s" GTW
 SG_ DAS_sw213_epasHandsOnDetected m213 : 36|1@1+ (1,0) [0|1] "" GTW
 SG_ DAS_sw213_autopilotRestricted m213 : 37|1@1+ (1,0) [0|1] "" GTW
 SG_ DAS_sw213_autopilotIntState m213 : 40|4@1+ (1,0) [0|1] "" GTW
 SG_ DAS_sw218_pedalPosition m218 : 16|7@1+ (1,0) [0|127] "%" GTW
 SG_ DAS_sw218_cipvDist m218 : 24|8@1+ (0.2,0) [0|51] "m" GTW
 SG_ DAS_sw218_handsOnState m218 : 32|4@1+ (1,0) [0|0] "" GTW
 SG_ DAS_sw218_mcuAutosteerRestricted m218 : 36|1@1+ (1,0) [0|0] "" GTW
 SG_ DAS_sw218_drivingOnHighway m218 : 37|1@1+ (1,0) [0|0] "" GTW
 SG_ DAS_sw219_vehicleSpeed m219 : 16|12@1+ (0.05,-25) [-25|179.75] "mph" GTW
 SG_ DAS_sw219_controlledAccess m219 : 28|1@1+ (1,0) [0|0] "" GTW
 SG_ DAS_sw219_roadClass m219 : 29|3@1+ (1,0) [0|0] "" GTW
 SG_ DAS_sw220_vehicleSpeed m220 : 16|12@1+ (0.05,-25) [-25|179.75] "mph" GTW
 SG_ DAS_sw220_controlledAccess m220 : 28|1@1+ (1,0) [0|0] "" GTW
 SG_ DAS_sw220_roadClass m220 : 29|3@1+ (1,0) [0|0] "" GTW
 SG_ DAS_sw227_sensorSide m227 : 16|4@1+ (1,0) [0|15] "" GTW
 SG_ DAS_sw227_sensorNumber m227 : 20|4@1+ (1,0) [0|15] "" GTW
 SG_ DAS_sw227_sensorMeasurement m227 : 24|9@1+ (1,0) [0|511] "cm" GTW
 SG_ DAS_sw227_vehicleSpeed m227 : 33|12@1+ (0.05,-25) [-25|179.75] "mph" GTW
 SG_ DAS_sw227_ambientTemperature m227 : 45|8@1+ (0.5,-40) [-40|87.5] "C" GTW
 SG_ DAS_sw230_sensor1Blocked m230 : 16|1@1+ (1,0) [0|1] "" GTW
 SG_ DAS_sw230_sensor2Blocked m230 : 17|1@1+ (1,0) [0|1] "" GTW
 SG_ DAS_sw230_sensor3Blocked m230 : 18|1@1+ (1,0) [0|1] "" GTW
 SG_ DAS_sw230_sensor4Blocked m230 : 19|1@1+ (1,0) [0|1] "" GTW
 SG_ DAS_sw230_sensor5Blocked m230 : 20|1@1+ (1,0) [0|1] "" GTW
 SG_ DAS_sw230_sensor6Blocked m230 : 21|1@1+ (1,0) [0|1] "" GTW
 SG_ DAS_sw230_sensor7Blocked m230 : 22|1@1+ (1,0) [0|1] "" GTW
 SG_ DAS_sw230_sensor8Blocked m230 : 23|1@1+ (1,0) [0|1] "" GTW
 SG_ DAS_sw230_sensor9Blocked m230 : 24|1@1+ (1,0) [0|1] "" GTW
 SG_ DAS_sw230_sensor10Blocked m230 : 25|1@1+ (1,0) [0|1] "" GTW
 SG_ DAS_sw230_sensor11Blocked m230 : 26|1@1+ (1,0) [0|1] "" GTW
 SG_ DAS_sw230_sensor12Blocked m230 : 27|1@1+ (1,0) [0|1] "" GTW
 SG_ DAS_sw231_timeToImpact m231 : 16|9@1+ (1,0) [0|511] "ms" GTW
 SG_ DAS_sw231_predImpactVelocity m231 : 25|7@1+ (0.5,0) [0|63.5] "m/s" GTW
 SG_ DAS_sw231_targetDistance m231 : 32|7@1+ (0.1,0) [0|12.7] "m" GTW
 SG_ DAS_sw231_targetRelVelocity m231 : 39|6@1+ (0.5,0) [0|31.5] "m/s" GTW
 SG_ DAS_sw231_targetRelAcceleration m231 : 45|8@1+ (0.1,-12.8) [-12.8|12.7] "m/s2" GTW
 SG_ DAS_sw231_targetIsACar m231 : 53|1@1+ (1,0) [0|0] "" GTW
 SG_ DAS_sw231_egoVehicleSpeed m231 : 54|5@1+ (5,0) [0|155] "kph" GTW
 SG_ DAS_sw231_steeringOverride m231 : 59|1@1+ (1,0) [0|1] "" GTW
 SG_ DAS_sw231_predOverlap m231 : 60|4@1+ (10,0) [0|150] "%" GTW

BO_ 583 DAS_autopilotDebug: 8 DAS
 SG_ DAS_roadEstimator : 0|2@1+ (1,0) [0|3] "" GTW
 SG_ DAS_arbiterBehavior : 2|3@1+ (1,0) [0|7] "" GTW
 SG_ DAS_mapAvailability : 8|1@1+ (1,0) [0|1] "" GTW
 SG_ DAS_controllerRef : 9|3@1+ (1,0) [0|3] "" GTW
 SG_ DAS_alcInternalState : 12|4@1+ (1,0) [0|15] "" GTW
 SG_ DAS_behaviorReport : 16|6@1+ (1,0) [0|63] "" GTW
 SG_ DAS_controllerHealth : 22|2@1+ (1,0) [0|3] "" GTW
 SG_ DAS_constructionZone : 24|1@1+ (1,0) [0|1] "" GTW
 SG_ DAS_controlDistance : 25|6@1+ (2,0) [0|126] "m" GTW
 SG_ DAS_autopilotAbortReason : 32|6@1+ (1,0) [0|63] "" GTW
 SG_ DAS_rqstedBehaviorStatus : 40|5@1+ (1,0) [0|31] "" GTW
 SG_ DAS_forkState : 45|5@1+ (1,0) [0|31] "" GTW
 SG_ DAS_laneChangeState : 50|6@1+ (1,0) [0|63] "" GTW
 SG_ DAS_lastWatchdogCode : 56|8@1+ (1,0) [0|255] "" GTW

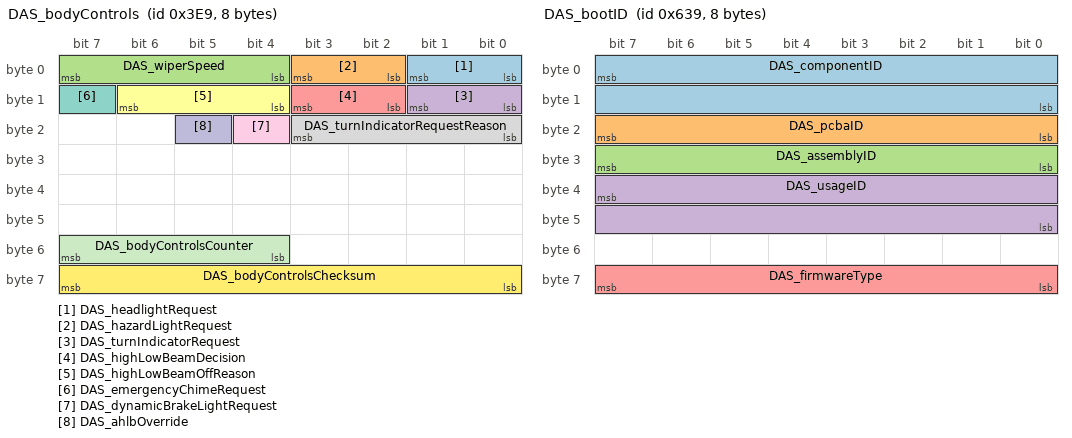
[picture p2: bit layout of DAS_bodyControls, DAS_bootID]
BO_ 1001 DAS_bodyControls: 8 DAS
 SG_ DAS_headlightRequest : 0|2@1+ (1,0) [0|3] "" GTW,APS
 SG_ DAS_hazardLightRequest : 2|2@1+ (1,0) [0|3] "" GTW,APS
 SG_ DAS_wiperSpeed : 4|4@1+ (1,0) [0|15] "" GTW,APS
 SG_ DAS_turnIndicatorRequest : 8|2@1+ (1,0) [0|3] "" GTW,APS
 SG_ DAS_highLowBeamDecision : 10|2@1+ (1,0) [0|3] "" GTW,APS
 SG_ DAS_highLowBeamOffReason : 12|3@1+ (1,0) [0|4] "" GTW,APS
 SG_ DAS_emergencyChimeRequest : 15|1@1+ (1,0) [0|1] "" GTW,APS
 SG_ DAS_turnIndicatorRequestReason : 16|4@1+ (1,0) [0|15] "" GTW,APS
 SG_ DAS_dynamicBrakeLightRequest : 20|1@1+ (1,0) [0|1] "" GTW,APS
 SG_ DAS_ahlbOverride : 21|1@1+ (1,0) [0|1] "" GTW,APS
 SG_ DAS_bodyControlsCounter : 52|4@1+ (1,0) [0|15] "" GTW,APS
 SG_ DAS_bodyControlsChecksum : 56|8@1+ (1,0) [0|255] "" GTW,APS

BO_ 1593 DAS_bootID: 8 DAS
 SG_ DAS_componentID : 7|16@0+ (1,0) [0|65535] "" Vector__XXX
 SG_ DAS_pcbaID : 23|8@0+ (1,0) [0|255] "" Vector__XXX
 SG_ DAS_assemblyID : 31|8@0+ (1,0) [0|255] "" Vector__XXX
 SG_ DAS_usageID : 39|16@0+ (1,0) [0|65535] "" Vector__XXX
 SG_ DAS_firmwareType : 63|8@0+ (1,0) [0|255] "" Vector__XXX

CM_ SG_ 643 DrRLtch_FL_Stat "Rotary latch door front left state";
CM_ SG_ 643 DrRLtch_FR_Stat "Rotary latch door front right state";
CM_ SG_ 643 DrRLtch_RL_Stat "Rotary latch door rear left state";
CM_ SG_ 643 DrRLtch_RR_Stat "Rotary latch door rear right state";
CM_ SG_ 643 DL_RLtch_Stat "Deck lid rotary latch state";
CM_ SG_ 643 EngHd_Stat "Engine hood state";
CM_ SG_ 643 VTA_Alm_Actv "Alarm activated by vehicle theft alarm";
CM_ SG_ 643 LgtSens_Twlgt "Twilight state light sensor";
CM_ SG_ 643 LgtSens_SNA "Light sensor information not available";
CM_ SG_ 643 LgtSens_Tunnel "Light sensor 'tunnel' detected";
CM_ SG_ 643 LgtSens_Flt "Light sensor fault";
CM_ SG_ 643 LgtSens_Night "Light sensor detects night mode";
CM_ SG_ 643 ADL_LoBm_On_Rq "Low beam on request by automatic driving light";
CM_ SG_ 643 Trlr_Stat "Trailer detected";
CM_ SG_ 643 Hrn_On "Horn is on";
CM_ SG_ 643 Term54_Actv "Terminal 54 (brake light) active (from SAM_R)";
CM_ SG_ 643 MPkBrk_Stat "Mech. parking brake state";
CM_ SG_ 643 WprOutsdPkPosn "Wiper outside park position";
CM_ SG_ 643 LoBm_On_Rq "Low beam on request";
CM_ SG_ 643 HiBm_On "High beam is on";
CM_ SG_ 643 IrLmp_D_Lt_Flt "Infrared lamp driver side or left (depending on vehicle line) fault";
CM_ SG_ 643 IrLmp_P_Rt_Flt "Infrared lamp passenger side or right (depending on vehicle line) fault";
CM_ SG_ 643 LoBm_D_Lt_Flt "Low beam driver side or left (depending on vehicle line) fault";
CM_ SG_ 643 LoBm_P_Rt_Flt "Low beam passenger side or right (depending on vehicle line) fault";
CM_ SG_ 643 RevGr_Engg "Reverse gear engaged";
CM_ SG_ 643 AirTemp_Insd "Inside air temperature";
CM_ SG_ 643 Bckl_Sw_RL_Stat_SAM_R "Buckle switch rear left state (by SAM_R)";
CM_ SG_ 643 Bckl_Sw_RR_Stat_SAM_R "Buckle switch rear right state (by SAM_R)";
CM_ SG_ 643 Bckl_Sw_RM_Stat_SAM_R "Buckle switch rear middle state (by SAM_R)";
CM_ SG_ 643 StW_Cond_Stat "Steering wheel conditioning state";
CM_ SG_ 643 AirTemp_Outsd "Outside air temperature";
CM_ SG_ 15 CGW_Rout_Stat "CGW routing status";
CM_ SG_ 15 BusFlt_PrmntActv "Bus faulty, permanent active";
CM_ SG_ 556 CHG_evseAccept "Charger has turned on evse accept signal";
CM_ SG_ 556 CHG_phaseConfig "CHG Phase Config";
CM_ SG_ 21 SwIllLvl "Switch illumination level (Term. 58d)";
CM_ SG_ 21 DispBrt_IC "Display brightness instrument cluster";
CM_ SG_ 519 Group "DC group";
CM_ SG_ 519 Country "Country code";
CM_ SG_ 519 VehLine "Vehicle line";
CM_ SG_ 519 Guard "Guard level";
CM_ SG_ 519 VehLinePack "Vehicle line version: package";
CM_ SG_ 519 VehLineYear "Vehicle line version: year";
CM_ SG_ 519 VSTS_Avl "Vario Steering System available";
CM_ SG_ 519 BodyStyle "Vehicle body style";
CM_ SG_ 519 StStyle "Steering variant";
CM_ SG_ 519 PSTS_Avl "Parametric Steering System available";
CM_ SG_ 519 EngStyle "Engine (Bit 7: Otto-engine => 0, Diesel-engine => 1)";
CM_ SG_ 519 TCM_Avl "Transmission control available";
CM_ SG_ 519 HVAC_Avl "Air Condition available";
CM_ SG_ 519 TrlrHtch_Avl "Trailer Hitch available";
CM_ SG_ 519 VTA_Avl "Vehicle theft alarm available";
CM_ SG_ 519 PCD_Avl "Passenger compartment detection available";
CM_ SG_ 519 ICH_Avl "Independent car heater available";
CM_ SG_ 519 LgtSens_Avl "Light sensor available";
CM_ SG_ 519 RainSens_Avl "Rain sensor available";
CM_ SG_ 519 HVACStyle "HVAC style";
CM_ SG_ 519 VehOPTPack "Vehicle options package";
CM_ SG_ 519 Cplt_SL_Enbl "Complete substitution lights enabled";
CM_ SG_ 519 RoofStyle "Vehicle roof style";
CM_ SG_ 519 CRC_CVI "CRC-checksum byte 1 to 7 according to SAE J1850";
CM_ SG_ 1465 DAS_sw019_numFreeBytes "A positive value denotes the number of bytes remaining in the stack before it will overflow. A negative value indicates that the stack has overflown by those many bytes. Any overflow beyond 191 bytes is snapped back and reported as -191 byte overflow.";
CM_ SG_ 1465 DAS_sw019_timeStamp "Time stamp in milliseconds after the ECU health monitor gets initialized.";
CM_ SG_ 1465 DAS_sw027_Clock_Monitor_0_Low "External crystal oscillator, PLL 0 or Internal RC oscillator  under the rated frequency limits.";
CM_ SG_ 1465 DAS_sw027_Clock_Monitor_0_Off "External crystal oscillator, PLL 0 or Internal RC oscillator either over or under the rated frequency limits.";
CM_ SG_ 1465 DAS_sw027_f_PLL_1_Off "PLL 1 frequency over or under allowable limits.";
CM_ SG_ 1465 DAS_sw194_timeInHold "Time in ms since ACC entered HOLD state";
CM_ SG_ 1001 DAS_bodyControlsChecksum "Checksum method for DAS_bodyControls is sum of all bytes in message + originating CAN ID (0x3 + 0xE9) = 0xEC";
BA_DEF_ BO_ "AlertLogSubSystemId" INT 0 0;
BA_DEF_ BO_ "AlertType" INT 0 4;
BA_DEF_ BO_ "AppBotschaft" ENUM "nein","ja";
BA_DEF_ BO_ "DiagRequest" ENUM "No","Yes";
BA_DEF_ BO_ "DiagResponse" ENUM "No","Yes";
BA_DEF_ BO_ "ETHGatewayMessageSendType" ENUM "UseGenMsgSendType","onWrite","noAutoCode";
BA_DEF_ BO_ "ETHId" STRING ;
BA_DEF_ BO_ "GatewayHandlerEnum" ENUM "noHandler","uds","alertLog","messageLogOnReception","udsClient";
BA_DEF_ BO_ "GatewayMessageAtomic" ENUM "No","Yes";
BA_DEF_ BO_ "GatewayMessageSendType" ENUM "UseGenMsgSendType","onWrite","noAutoCode";
BA_DEF_ BO_ "GenMsgCycleTime" INT 0 0;
BA_DEF_ BO_ "GenMsgCycleTimeFast" INT 0 0;
BA_DEF_ BO_ "GenMsgDelayTime" INT 0 0;
BA_DEF_ BO_ "GenMsgForceMiaCheck" ENUM "No","Yes";
BA_DEF_ BO_ "GenMsgGatewayNotification" STRING ;
BA_DEF_ BO_ "GenMsgILSupport" ENUM "No","Yes";
BA_DEF_ BO_ "GenMsgSaltingFunction" ENUM "No","Yes";
BA_DEF_ BO_ "GenMsgSendType" ENUM "Cyclic","NotUsed","NotUsed","NotUsed","NotUsed","NotUsed","NotUsed","IfActive","NoMsgSendType","Sporadic";
BA_DEF_ BO_ "GenMsgStartValue" STRING ;
BA_DEF_ BO_ "GenMsgTimeOut" INT 0 0;
BA_DEF_ BO_ "MessageIdType" ENUM "normal","udsRequest","udsResponse","udsReserved","udsFunctionalRequest","networkManagement","bootloader","xcp","dtc","diagnostic","vendorExempt";
BA_DEF_ BO_ "NWMBotschaft" ENUM "nein","ja";
BA_DEF_ BO_ "NmMessage" ENUM "No","Yes";
BA_DEF_ BO_ "SubSystemId" INT 0 256;
BA_DEF_ BO_ "UsesChecksum" ENUM "No","Yes";
BA_DEF_ SG_ "FieldType" STRING ;
BA_DEF_ SG_ "FlexKomComment" STRING ;
BA_DEF_ SG_ "FlexKomIsMotorola" ENUM "nein","ja";
BA_DEF_ SG_ "FlexKomSID" INT 0 2147483647;
BA_DEF_ SG_ "FlexKomSigLaenge" INT 0 64;
BA_DEF_ SG_ "FlexKomSigName" STRING ;
BA_DEF_ SG_ "FlexKomSigStartPos" INT 0 63;
BA_DEF_ SG_ "FlexKomSigStartValue" STRING ;
BA_DEF_ SG_ "Gatewaysignal" INT 0 1;
BA_DEF_ SG_ "GenSigCycleTime" INT 0 0;
BA_DEF_ SG_ "GenSigCycleTimeActive" INT 0 0;
BA_DEF_ SG_ "GenSigPersistent" ENUM "No","Yes";
BA_DEF_ SG_ "GenSigSNA" STRING ;
BA_DEF_ SG_ "GenSigSendType" ENUM "Cyclic","OnWrite","OnWriteWithRepetition","OnChange","OnChangeWithRepetition","IfActive","IfActiveWithRepetition","NoSigSendType","NotUsed","NotUsed","NotUsed","NotUsed","NotUsed";
BA_DEF_ SG_ "GenSigStartValue" INT 0 0;
BA_DEF_ SG_ "GenSigTimeout_CGW" INT 0 65535;
BA_DEF_ SG_ "GenSigTimeout_DRVU" INT 0 65535;
BA_DEF_ SG_ "GenSigTimeout_ECM" INT 0 65535;
BA_DEF_ SG_ "GenSigTimeout_EIS" INT 0 65535;
BA_DEF_ SG_ "GenSigTimeout_EPS" INT 0 65535;
BA_DEF_ SG_ "GenSigTimeout_ESP_ABR" INT 0 65535;
BA_DEF_ SG_ "GenSigTimeout_IC" INT 0 65535;
BA_DEF_ SG_ "GenSigTimeout_MPC" INT 0 65535;
BA_DEF_ SG_ "GenSigTimeout_NV" INT 0 65535;
BA_DEF_ SG_ "GenSigTimeout_ORC" INT 0 65535;
BA_DEF_ SG_ "GenSigTimeout_PTS" INT 0 65535;
BA_DEF_ SG_ "GenSigTimeout_RBTM_FL" INT 0 65535;
BA_DEF_ SG_ "GenSigTimeout_RBTM_FR" INT 0 65535;
BA_DEF_ SG_ "GenSigTimeout_RDU" INT 0 65535;
BA_DEF_ SG_ "GenSigTimeout_SCCM" INT 0 65535;
BA_DEF_ SG_ "GenSigTimeout_SPC" INT 0 65535;
BA_DEF_ SG_ "GenSigTimeout_TPM" INT 0 65535;
BA_DEF_ SG_ "LogSignal" STRING ;
BA_DEF_ SG_ "PektronUpdateBitType" ENUM "Not used","Has update bit","Is update bit";
BA_DEF_REL_ BU_SG_REL_ "GenSigTimeoutTime" INT 0 0;

BA_DEF_DEF_ "AlertLogSubSystemId" 0;
BA_DEF_DEF_ "AlertType" 4;
BA_DEF_DEF_ "AppBotschaft" "nein";
BA_DEF_DEF_ "DiagRequest" "No";
BA_DEF_DEF_ "DiagResponse" "No";
BA_DEF_DEF_ "ETHGatewayMessageSendType" "UseGenMsgSendType";
BA_DEF_DEF_ "ETHId" "";
BA_DEF_DEF_ "FieldType" "";
BA_DEF_DEF_ "FlexKomComment" "";
BA_DEF_DEF_ "FlexKomIsMotorola" "";
BA_DEF_DEF_ "FlexKomSID" 0;
BA_DEF_DEF_ "FlexKomSigLaenge" 0;
BA_DEF_DEF_ "FlexKomSigName" "";
BA_DEF_DEF_ "FlexKomSigStartPos" 0;
BA_DEF_DEF_ "FlexKomSigStartValue" "";
BA_DEF_DEF_ "GatewayHandlerEnum" "noHandler";
BA_DEF_DEF_ "GatewayMessageAtomic" "No";
BA_DEF_DEF_ "GatewayMessageSendType" "UseGenMsgSendType";
BA_DEF_DEF_ "Gatewaysignal" 0;
BA_DEF_DEF_ "GenMsgCycleTime" 0;
BA_DEF_DEF_ "GenMsgCycleTimeFast" 0;
BA_DEF_DEF_ "GenMsgDelayTime" 0;
BA_DEF_DEF_ "GenMsgForceMiaCheck" "No";
BA_DEF_DEF_ "GenMsgGatewayNotification" "";
BA_DEF_DEF_ "GenMsgILSupport" "Yes";
BA_DEF_DEF_ "GenMsgSaltingFunction" "No";
BA_DEF_DEF_ "GenMsgSendType" "Cyclic";
BA_DEF_DEF_ "GenMsgStartValue" "";
BA_DEF_DEF_ "GenMsgTimeOut" 0;
BA_DEF_DEF_ "GenSigCycleTime" 0;
BA_DEF_DEF_ "GenSigCycleTimeActive" 0;
BA_DEF_DEF_ "GenSigPersistent" "No";
BA_DEF_DEF_ "GenSigSNA" "";
BA_DEF_DEF_ "GenSigSendType" "Cyclic";
BA_DEF_DEF_ "GenSigStartValue" 0;
BA_DEF_DEF_ "GenSigTimeout_CGW" 0;
BA_DEF_DEF_ "GenSigTimeout_DRVU" 0;
BA_DEF_DEF_ "GenSigTimeout_ECM" 0;
BA_DEF_DEF_ "GenSigTimeout_EIS" 0;
BA_DEF_DEF_ "GenSigTimeout_EPS" 0;
BA_DEF_DEF_ "GenSigTimeout_ESP_ABR" 0;
BA_DEF_DEF_ "GenSigTimeout_IC" 0;
BA_DEF_DEF_ "GenSigTimeout_MPC" 0;
BA_DEF_DEF_ "GenSigTimeout_NV" 0;
BA_DEF_DEF_ "GenSigTimeout_ORC" 0;
BA_DEF_DEF_ "GenSigTimeout_PTS" 0;
BA_DEF_DEF_ "GenSigTimeout_RBTM_FL" 0;
BA_DEF_DEF_ "GenSigTimeout_RBTM_FR" 0;
BA_DEF_DEF_ "GenSigTimeout_RDU" 0;
BA_DEF_DEF_ "GenSigTimeout_SCCM" 0;
BA_DEF_DEF_ "GenSigTimeout_SPC" 0;
BA_DEF_DEF_ "GenSigTimeout_TPM" 0;
BA_DEF_DEF_ "LogSignal" "";
BA_DEF_DEF_ "MessageIdType" "normal";
BA_DEF_DEF_ "NWMBotschaft" "nein";
BA_DEF_DEF_ "NmMessage" "No";
BA_DEF_DEF_ "PektronUpdateBitType" "Not used";
BA_DEF_DEF_ "SubSystemId" 0;
BA_DEF_DEF_ "UsesChecksum" "No";
BA_DEF_DEF_REL_ "GenSigTimeoutTime" 0;
BA_ "GenMsgCycleTime" BO_ 643 1000;
BA_ "GenMsgStartValue" BO_ 643 "FF0F0803C0FF3FFFh";
BA_ "MessageIdType" BO_ 643 10;
BA_ "GenMsgSendType" BO_ 15 8;
BA_ "GenMsgStartValue" BO_ 15 "00h";
BA_ "MessageIdType" BO_ 15 10;
BA_ "GatewayMessageSendType" BO_ 556 1;
BA_ "GenMsgCycleTime" BO_ 556 100;
BA_ "GenMsgCycleTime" BO_ 1034 100;
BA_ "GenMsgILSupport" BO_ 1034 0;
BA_ "NmMessage" BO_ 1034 1;
BA_ "GenMsgCycleTime" BO_ 1032 100;
BA_ "NmMessage" BO_ 1032 1;
BA_ "GenMsgCycleTime" BO_ 1030 100;
BA_ "GenMsgILSupport" BO_ 1030 0;
BA_ "NmMessage" BO_ 1030 1;
BA_ "GatewayMessageSendType" BO_ 21 1;
BA_ "GenMsgCycleTime" BO_ 21 500;
BA_ "GenMsgStartValue" BO_ 21 "FFFFFFFFh";
BA_ "MessageIdType" BO_ 21 10;
BA_ "GenMsgSendType" BO_ 519 8;
BA_ "GenMsgStartValue" BO_ 519 "FFFF7F7FFF00EFFFh";
BA_ "GenMsgSendType" BO_ 1817 8;
BA_ "MessageIdType" BO_ 1817 9;
BA_ "GenMsgSendType" BO_ 1849 8;
BA_ "MessageIdType" BO_ 1849 9;
BA_ "AlertLogSubSystemId" BO_ 1465 195;
BA_ "GatewayHandlerEnum" BO_ 1465 2;
BA_ "GenMsgSendType" BO_ 1465 8;
BA_ "GatewayMessageSendType" BO_ 583 1;
BA_ "GenMsgCycleTime" BO_ 583 100;
BA_ "GatewayMessageSendType" BO_ 1001 1;
BA_ "GenMsgCycleTime" BO_ 1001 500;
BA_ "GenMsgCycleTime" BO_ 1593 500;
BA_ "FlexKomComment" SG_ 643 DrRLtch_FL_Stat "Rotary latch door front left state";
BA_ "FlexKomIsMotorola" SG_ 643 DrRLtch_FL_Stat 1;
BA_ "FlexKomSID" SG_ 643 DrRLtch_FL_Stat 117440519;
BA_ "FlexKomSigLaenge" SG_ 643 DrRLtch_FL_Stat 2;
BA_ "FlexKomSigName" SG_ 643 DrRLtch_FL_Stat "DrRLtch_FL_Stat";
BA_ "FlexKomSigStartPos" SG_ 643 DrRLtch_FL_Stat 1;
BA_ "FlexKomSigStartValue" SG_ 643 DrRLtch_FL_Stat "03h";
BA_ "GenSigCycleTime" SG_ 643 DrRLtch_FL_Stat 500;
BA_ "GenSigSNA" SG_ 643 DrRLtch_FL_Stat "3";
BA_ "GenSigSendType" SG_ 643 DrRLtch_FL_Stat 5;
BA_ "GenSigStartValue" SG_ 643 DrRLtch_FL_Stat 3;
BA_ "FlexKomComment" SG_ 643 DrRLtch_FR_Stat "Rotary latch door front right state";
BA_ "FlexKomIsMotorola" SG_ 643 DrRLtch_FR_Stat 1;
BA_ "FlexKomSID" SG_ 643 DrRLtch_FR_Stat 117440520;
BA_ "FlexKomSigLaenge" SG_ 643 DrRLtch_FR_Stat 2;
BA_ "FlexKomSigName" SG_ 643 DrRLtch_FR_Stat "DrRLtch_FR_Stat";
BA_ "FlexKomSigStartPos" SG_ 643 DrRLtch_FR_Stat 1;
BA_ "FlexKomSigStartValue" SG_ 643 DrRLtch_FR_Stat "03h";
BA_ "GenSigCycleTime" SG_ 643 DrRLtch_FR_Stat 500;
BA_ "GenSigSNA" SG_ 643 DrRLtch_FR_Stat "3";
BA_ "GenSigSendType" SG_ 643 DrRLtch_FR_Stat 5;
BA_ "GenSigStartValue" SG_ 643 DrRLtch_FR_Stat 3;
BA_ "FlexKomComment" SG_ 643 DrRLtch_RL_Stat "Rotary latch door rear left state";
BA_ "FlexKomIsMotorola" SG_ 643 DrRLtch_RL_Stat 1;
BA_ "FlexKomSID" SG_ 643 DrRLtch_RL_Stat 117440521;
BA_ "FlexKomSigLaenge" SG_ 643 DrRLtch_RL_Stat 2;
BA_ "FlexKomSigName" SG_ 643 DrRLtch_RL_Stat "DrRLtch_RL_Stat";
BA_ "FlexKomSigStartPos" SG_ 643 DrRLtch_RL_Stat 5;
BA_ "FlexKomSigStartValue" SG_ 643 DrRLtch_RL_Stat "03h";
BA_ "GenSigCycleTime" SG_ 643 DrRLtch_RL_Stat 100;
BA_ "GenSigSNA" SG_ 643 DrRLtch_RL_Stat "3";
BA_ "GenSigSendType" SG_ 643 DrRLtch_RL_Stat 5;
BA_ "GenSigStartValue" SG_ 643 DrRLtch_RL_Stat 3;
BA_ "GenSigTimeout_DRVU" SG_ 643 DrRLtch_RL_Stat 1050;
BA_ "GenSigTimeout_SPC" SG_ 643 DrRLtch_RL_Stat 1050;
BA_ "FlexKomComment" SG_ 643 DrRLtch_RR_Stat "Rotary latch door rear right state";
BA_ "FlexKomIsMotorola" SG_ 643 DrRLtch_RR_Stat 1;
BA_ "FlexKomSID" SG_ 643 DrRLtch_RR_Stat 117440522;
BA_ "FlexKomSigLaenge" SG_ 643 DrRLtch_RR_Stat 2;
BA_ "FlexKomSigName" SG_ 643 DrRLtch_RR_Stat "DrRLtch_RR_Stat";
BA_ "FlexKomSigStartPos" SG_ 643 DrRLtch_RR_Stat 7;
BA_ "FlexKomSigStartValue" SG_ 643 DrRLtch_RR_Stat "03h";
BA_ "GenSigCycleTime" SG_ 643 DrRLtch_RR_Stat 100;
BA_ "GenSigSNA" SG_ 643 DrRLtch_RR_Stat "3";
BA_ "GenSigSendType" SG_ 643 DrRLtch_RR_Stat 5;
BA_ "GenSigStartValue" SG_ 643 DrRLtch_RR_Stat 3;
BA_ "GenSigTimeout_DRVU" SG_ 643 DrRLtch_RR_Stat 1050;
BA_ "GenSigTimeout_SPC" SG_ 643 DrRLtch_RR_Stat 1050;
BA_ "FlexKomComment" SG_ 643 DL_RLtch_Stat "Deck lid rotary latch state";
BA_ "FlexKomIsMotorola" SG_ 643 DL_RLtch_Stat 1;
BA_ "FlexKomSID" SG_ 643 DL_RLtch_Stat 117440523;
BA_ "FlexKomSigLaenge" SG_ 643 DL_RLtch_Stat 2;
BA_ "FlexKomSigName" SG_ 643 DL_RLtch_Stat "DL_RLtch_Stat";
BA_ "FlexKomSigStartPos" SG_ 643 DL_RLtch_Stat 9;
BA_ "FlexKomSigStartValue" SG_ 643 DL_RLtch_Stat "03h";
BA_ "GenSigCycleTime" SG_ 643 DL_RLtch_Stat 100;
BA_ "GenSigSNA" SG_ 643 DL_RLtch_Stat "3";
BA_ "GenSigSendType" SG_ 643 DL_RLtch_Stat 5;
BA_ "GenSigStartValue" SG_ 643 DL_RLtch_Stat 3;
BA_ "GenSigTimeout_DRVU" SG_ 643 DL_RLtch_Stat 1050;
BA_ "GenSigTimeout_SPC" SG_ 643 DL_RLtch_Stat 1050;
BA_ "FlexKomComment" SG_ 643 EngHd_Stat "Engine hood state";
BA_ "FlexKomIsMotorola" SG_ 643 EngHd_Stat 1;
BA_ "FlexKomSID" SG_ 643 EngHd_Stat 117440524;
BA_ "FlexKomSigLaenge" SG_ 643 EngHd_Stat 2;
BA_ "FlexKomSigName" SG_ 643 EngHd_Stat "EngHd_Stat";
BA_ "FlexKomSigStartPos" SG_ 643 EngHd_Stat 11;
BA_ "FlexKomSigStartValue" SG_ 643 EngHd_Stat "03h";
BA_ "GenSigCycleTime" SG_ 643 EngHd_Stat 100;
BA_ "GenSigSNA" SG_ 643 EngHd_Stat "3";
BA_ "GenSigSendType" SG_ 643 EngHd_Stat 5;
BA_ "GenSigStartValue" SG_ 643 EngHd_Stat 3;
BA_ "GenSigTimeout_ESP_ABR" SG_ 643 EngHd_Stat 1550;
BA_ "FlexKomComment" SG_ 643 VTA_Alm_Actv "Alarm activated by vehicle theft alarm";
BA_ "FlexKomIsMotorola" SG_ 643 VTA_Alm_Actv 1;
BA_ "FlexKomSID" SG_ 643 VTA_Alm_Actv 117442366;
BA_ "FlexKomSigLaenge" SG_ 643 VTA_Alm_Actv 1;
BA_ "FlexKomSigName" SG_ 643 VTA_Alm_Actv "VTA_Alm_Actv";
BA_ "FlexKomSigStartPos" SG_ 643 VTA_Alm_Actv 13;
BA_ "FlexKomSigStartValue" SG_ 643 VTA_Alm_Actv "00h";
BA_ "GenSigCycleTime" SG_ 643 VTA_Alm_Actv 100;
BA_ "GenSigSendType" SG_ 643 VTA_Alm_Actv 5;
BA_ "FlexKomComment" SG_ 643 LgtSens_Twlgt "State light sensor";
BA_ "FlexKomIsMotorola" SG_ 643 LgtSens_Twlgt 1;
BA_ "FlexKomSID" SG_ 643 LgtSens_Twlgt 117443752;
BA_ "FlexKomSigLaenge" SG_ 643 LgtSens_Twlgt 8;
BA_ "FlexKomSigName" SG_ 643 LgtSens_Twlgt "LgtSens_Stat_C";
BA_ "FlexKomSigStartPos" SG_ 643 LgtSens_Twlgt 23;
BA_ "FlexKomSigStartValue" SG_ 643 LgtSens_Twlgt "08h";
BA_ "GenSigCycleTime" SG_ 643 LgtSens_Twlgt 100;
BA_ "GenSigSendType" SG_ 643 LgtSens_Twlgt 5;
BA_ "GenSigTimeout_ESP_ABR" SG_ 643 LgtSens_Twlgt 1550;
BA_ "GenSigTimeout_MPC" SG_ 643 LgtSens_Twlgt 1050;
BA_ "FlexKomComment" SG_ 643 LgtSens_SNA "State light sensor";
BA_ "FlexKomIsMotorola" SG_ 643 LgtSens_SNA 1;
BA_ "FlexKomSID" SG_ 643 LgtSens_SNA 117443752;
BA_ "FlexKomSigLaenge" SG_ 643 LgtSens_SNA 8;
BA_ "FlexKomSigName" SG_ 643 LgtSens_SNA "LgtSens_Stat_C";
BA_ "FlexKomSigStartPos" SG_ 643 LgtSens_SNA 23;
BA_ "FlexKomSigStartValue" SG_ 643 LgtSens_SNA "08h";
BA_ "GenSigCycleTime" SG_ 643 LgtSens_SNA 100;
BA_ "GenSigSendType" SG_ 643 LgtSens_SNA 5;
BA_ "GenSigStartValue" SG_ 643 LgtSens_SNA 1;
BA_ "GenSigTimeout_ESP_ABR" SG_ 643 LgtSens_SNA 1550;
BA_ "GenSigTimeout_MPC" SG_ 643 LgtSens_SNA 1050;
BA_ "FlexKomComment" SG_ 643 LgtSens_Tunnel "State light sensor";
BA_ "FlexKomIsMotorola" SG_ 643 LgtSens_Tunnel 1;
BA_ "FlexKomSID" SG_ 643 LgtSens_Tunnel 117443752;
BA_ "FlexKomSigLaenge" SG_ 643 LgtSens_Tunnel 8;
BA_ "FlexKomSigName" SG_ 643 LgtSens_Tunnel "LgtSens_Stat_C";
BA_ "FlexKomSigStartPos" SG_ 643 LgtSens_Tunnel 23;
BA_ "FlexKomSigStartValue" SG_ 643 LgtSens_Tunnel "08h";
BA_ "GenSigCycleTime" SG_ 643 LgtSens_Tunnel 100;
BA_ "GenSigSendType" SG_ 643 LgtSens_Tunnel 5;
BA_ "GenSigTimeout_ESP_ABR" SG_ 643 LgtSens_Tunnel 1550;
BA_ "GenSigTimeout_MPC" SG_ 643 LgtSens_Tunnel 1050;
BA_ "FlexKomComment" SG_ 643 LgtSens_Flt "State light sensor";
BA_ "FlexKomIsMotorola" SG_ 643 LgtSens_Flt 1;
BA_ "FlexKomSID" SG_ 643 LgtSens_Flt 117443752;
BA_ "FlexKomSigLaenge" SG_ 643 LgtSens_Flt 8;
BA_ "FlexKomSigName" SG_ 643 LgtSens_Flt "LgtSens_Stat_C";
BA_ "FlexKomSigStartPos" SG_ 643 LgtSens_Flt 23;
BA_ "FlexKomSigStartValue" SG_ 643 LgtSens_Flt "08h";
BA_ "GenSigCycleTime" SG_ 643 LgtSens_Flt 100;
BA_ "GenSigSendType" SG_ 643 LgtSens_Flt 5;
BA_ "GenSigTimeout_ESP_ABR" SG_ 643 LgtSens_Flt 1550;
BA_ "GenSigTimeout_MPC" SG_ 643 LgtSens_Flt 1050;
BA_ "FlexKomComment" SG_ 643 LgtSens_Night "State light sensor";
BA_ "FlexKomIsMotorola" SG_ 643 LgtSens_Night 1;
BA_ "FlexKomSID" SG_ 643 LgtSens_Night 117443752;
BA_ "FlexKomSigLaenge" SG_ 643 LgtSens_Night 8;
BA_ "FlexKomSigName" SG_ 643 LgtSens_Night "LgtSens_Stat_C";
BA_ "FlexKomSigStartPos" SG_ 643 LgtSens_Night 23;
BA_ "FlexKomSigStartValue" SG_ 643 LgtSens_Night "08h";
BA_ "GenSigCycleTime" SG_ 643 LgtSens_Night 100;
BA_ "GenSigSendType" SG_ 643 LgtSens_Night 5;
BA_ "GenSigTimeout_DRVU" SG_ 643 LgtSens_Night 1050;
BA_ "GenSigTimeout_ESP_ABR" SG_ 643 LgtSens_Night 1550;
BA_ "GenSigTimeout_MPC" SG_ 643 LgtSens_Night 1050;
BA_ "GenSigTimeout_PTS" SG_ 643 LgtSens_Night 1050;
BA_ "GenSigTimeout_SCCM" SG_ 643 LgtSens_Night 1050;
BA_ "FlexKomComment" SG_ 643 ADL_LoBm_On_Rq "State light sensor";
BA_ "FlexKomIsMotorola" SG_ 643 ADL_LoBm_On_Rq 1;
BA_ "FlexKomSID" SG_ 643 ADL_LoBm_On_Rq 117443752;
BA_ "FlexKomSigLaenge" SG_ 643 ADL_LoBm_On_Rq 8;
BA_ "FlexKomSigName" SG_ 643 ADL_LoBm_On_Rq "LgtSens_Stat_C";
BA_ "FlexKomSigStartPos" SG_ 643 ADL_LoBm_On_Rq 23;
BA_ "FlexKomSigStartValue" SG_ 643 ADL_LoBm_On_Rq "08h";
BA_ "GenSigCycleTime" SG_ 643 ADL_LoBm_On_Rq 100;
BA_ "GenSigSendType" SG_ 643 ADL_LoBm_On_Rq 5;
BA_ "FlexKomComment" SG_ 643 Trlr_Stat "Trailer detected";
BA_ "FlexKomIsMotorola" SG_ 643 Trlr_Stat 1;
BA_ "FlexKomSID" SG_ 643 Trlr_Stat 117441760;
BA_ "FlexKomSigLaenge" SG_ 643 Trlr_Stat 2;
BA_ "FlexKomSigName" SG_ 643 Trlr_Stat "Trlr_Stat";
BA_ "FlexKomSigStartPos" SG_ 643 Trlr_Stat 25;
BA_ "FlexKomSigStartValue" SG_ 643 Trlr_Stat "03h";
BA_ "GenSigCycleTime" SG_ 643 Trlr_Stat 100;
BA_ "GenSigSNA" SG_ 643 Trlr_Stat "3";
BA_ "GenSigSendType" SG_ 643 Trlr_Stat 5;
BA_ "GenSigStartValue" SG_ 643 Trlr_Stat 3;
BA_ "GenSigTimeout_ESP_ABR" SG_ 643 Trlr_Stat 1550;
BA_ "GenSigTimeout_PTS" SG_ 643 Trlr_Stat 1050;
BA_ "GenSigTimeout_SPC" SG_ 643 Trlr_Stat 1050;
BA_ "FlexKomComment" SG_ 643 Hrn_On "Horn is on";
BA_ "FlexKomIsMotorola" SG_ 643 Hrn_On 1;
BA_ "FlexKomSID" SG_ 643 Hrn_On 117441022;
BA_ "FlexKomSigLaenge" SG_ 643 Hrn_On 1;
BA_ "FlexKomSigName" SG_ 643 Hrn_On "Hrn_On";
BA_ "FlexKomSigStartPos" SG_ 643 Hrn_On 26;
BA_ "FlexKomSigStartValue" SG_ 643 Hrn_On "00h";
BA_ "GenSigCycleTime" SG_ 643 Hrn_On 100;
BA_ "GenSigSendType" SG_ 643 Hrn_On 5;
BA_ "FlexKomComment" SG_ 643 Term54_Actv "Terminal 54 (brake light) active (from SAM_R)";
BA_ "FlexKomIsMotorola" SG_ 643 Term54_Actv 1;
BA_ "FlexKomSID" SG_ 643 Term54_Actv 117441762;
BA_ "FlexKomSigLaenge" SG_ 643 Term54_Actv 1;
BA_ "FlexKomSigName" SG_ 643 Term54_Actv "Term54_Actv";
BA_ "FlexKomSigStartPos" SG_ 643 Term54_Actv 27;
BA_ "FlexKomSigStartValue" SG_ 643 Term54_Actv "00h";
BA_ "GenSigCycleTime" SG_ 643 Term54_Actv 100;
BA_ "GenSigSendType" SG_ 643 Term54_Actv 5;
BA_ "FlexKomComment" SG_ 643 MPkBrk_Stat "Mech. parking brake state";
BA_ "FlexKomIsMotorola" SG_ 643 MPkBrk_Stat 1;
BA_ "FlexKomSID" SG_ 643 MPkBrk_Stat 117443386;
BA_ "FlexKomSigLaenge" SG_ 643 MPkBrk_Stat 1;
BA_ "FlexKomSigName" SG_ 643 MPkBrk_Stat "MPkBrk_Stat";
BA_ "FlexKomSigStartPos" SG_ 643 MPkBrk_Stat 28;
BA_ "FlexKomSigStartValue" SG_ 643 MPkBrk_Stat "00h";
BA_ "GenSigCycleTime" SG_ 643 MPkBrk_Stat 100;
BA_ "GenSigSendType" SG_ 643 MPkBrk_Stat 5;
BA_ "GenSigTimeout_ESP_ABR" SG_ 643 MPkBrk_Stat 1550;
BA_ "GenSigTimeout_PTS" SG_ 643 MPkBrk_Stat 1050;
BA_ "FlexKomComment" SG_ 643 WprOutsdPkPosn "Wiper outside park position";
BA_ "FlexKomIsMotorola" SG_ 643 WprOutsdPkPosn 1;
BA_ "FlexKomSID" SG_ 643 WprOutsdPkPosn 117441764;
BA_ "FlexKomSigLaenge" SG_ 643 WprOutsdPkPosn 1;
BA_ "FlexKomSigName" SG_ 643 WprOutsdPkPosn "WprOutsdPkPosn";
BA_ "FlexKomSigStartPos" SG_ 643 WprOutsdPkPosn 29;
BA_ "FlexKomSigStartValue" SG_ 643 WprOutsdPkPosn "00h";
BA_ "GenSigCycleTime" SG_ 643 WprOutsdPkPosn 100;
BA_ "GenSigSendType" SG_ 643 WprOutsdPkPosn 5;
BA_ "GenSigTimeout_ESP_ABR" SG_ 643 WprOutsdPkPosn 1550;
BA_ "GenSigTimeout_MPC" SG_ 643 WprOutsdPkPosn 1050;
BA_ "FlexKomComment" SG_ 643 LoBm_On_Rq "Exterior lamps state";
BA_ "FlexKomIsMotorola" SG_ 643 LoBm_On_Rq 1;
BA_ "FlexKomSID" SG_ 643 LoBm_On_Rq 117440543;
BA_ "FlexKomSigLaenge" SG_ 643 LoBm_On_Rq 16;
BA_ "FlexKomSigName" SG_ 643 LoBm_On_Rq "ExtLmp_Stat";
BA_ "FlexKomSigStartPos" SG_ 643 LoBm_On_Rq 7;
BA_ "FlexKomSigStartValue" SG_ 643 LoBm_On_Rq "0018h";
BA_ "GenSigCycleTime" SG_ 643 LoBm_On_Rq 100;
BA_ "GenSigSendType" SG_ 643 LoBm_On_Rq 5;
BA_ "FlexKomComment" SG_ 643 HiBm_On "High beam is on";
BA_ "FlexKomIsMotorola" SG_ 643 HiBm_On 1;
BA_ "FlexKomSID" SG_ 643 HiBm_On 117440529;
BA_ "FlexKomSigLaenge" SG_ 643 HiBm_On 1;
BA_ "FlexKomSigName" SG_ 643 HiBm_On "HiBm_On";
BA_ "FlexKomSigStartPos" SG_ 643 HiBm_On 33;
BA_ "FlexKomSigStartValue" SG_ 643 HiBm_On "00h";
BA_ "GenSigCycleTime" SG_ 643 HiBm_On 100;
BA_ "GenSigSendType" SG_ 643 HiBm_On 5;
BA_ "GenSigTimeout_MPC" SG_ 643 HiBm_On 1050;
BA_ "FlexKomComment" SG_ 643 IrLmp_D_Lt_Flt "Infrared lamp driver side or left (depending on ve";
BA_ "FlexKomIsMotorola" SG_ 643 IrLmp_D_Lt_Flt 1;
BA_ "FlexKomSID" SG_ 643 IrLmp_D_Lt_Flt 117443714;
BA_ "FlexKomSigLaenge" SG_ 643 IrLmp_D_Lt_Flt 1;
BA_ "FlexKomSigName" SG_ 643 IrLmp_D_Lt_Flt "IrLmp_D_Lt_Flt";
BA_ "FlexKomSigStartPos" SG_ 643 IrLmp_D_Lt_Flt 34;
BA_ "FlexKomSigStartValue" SG_ 643 IrLmp_D_Lt_Flt "00h";
BA_ "GenSigCycleTime" SG_ 643 IrLmp_D_Lt_Flt 100;
BA_ "GenSigSendType" SG_ 643 IrLmp_D_Lt_Flt 5;
BA_ "FlexKomComment" SG_ 643 IrLmp_P_Rt_Flt "Infrared lamp passenger side or right (depending o";
BA_ "FlexKomIsMotorola" SG_ 643 IrLmp_P_Rt_Flt 1;
BA_ "FlexKomSID" SG_ 643 IrLmp_P_Rt_Flt 117443713;
BA_ "FlexKomSigLaenge" SG_ 643 IrLmp_P_Rt_Flt 1;
BA_ "FlexKomSigName" SG_ 643 IrLmp_P_Rt_Flt "IrLmp_P_Rt_Flt";
BA_ "FlexKomSigStartPos" SG_ 643 IrLmp_P_Rt_Flt 35;
BA_ "FlexKomSigStartValue" SG_ 643 IrLmp_P_Rt_Flt "00h";
BA_ "GenSigCycleTime" SG_ 643 IrLmp_P_Rt_Flt 100;
BA_ "GenSigSendType" SG_ 643 IrLmp_P_Rt_Flt 5;
BA_ "FlexKomComment" SG_ 643 LoBm_D_Lt_Flt "Low beam driver side or left (depending on vehicle";
BA_ "FlexKomIsMotorola" SG_ 643 LoBm_D_Lt_Flt 1;
BA_ "FlexKomSID" SG_ 643 LoBm_D_Lt_Flt 117443715;
BA_ "FlexKomSigLaenge" SG_ 643 LoBm_D_Lt_Flt 1;
BA_ "FlexKomSigName" SG_ 643 LoBm_D_Lt_Flt "LoBm_D_Lt_Flt";
BA_ "FlexKomSigStartPos" SG_ 643 LoBm_D_Lt_Flt 36;
BA_ "FlexKomSigStartValue" SG_ 643 LoBm_D_Lt_Flt "00h";
BA_ "GenSigCycleTime" SG_ 643 LoBm_D_Lt_Flt 100;
BA_ "GenSigSendType" SG_ 643 LoBm_D_Lt_Flt 5;
BA_ "FlexKomComment" SG_ 643 LoBm_P_Rt_Flt "Low beam passenger side or right (depending on veh";
BA_ "FlexKomIsMotorola" SG_ 643 LoBm_P_Rt_Flt 1;
BA_ "FlexKomSID" SG_ 643 LoBm_P_Rt_Flt 117443716;
BA_ "FlexKomSigLaenge" SG_ 643 LoBm_P_Rt_Flt 1;
BA_ "FlexKomSigName" SG_ 643 LoBm_P_Rt_Flt "LoBm_P_Rt_Flt";
BA_ "FlexKomSigStartPos" SG_ 643 LoBm_P_Rt_Flt 37;
BA_ "FlexKomSigStartValue" SG_ 643 LoBm_P_Rt_Flt "00h";
BA_ "GenSigCycleTime" SG_ 643 LoBm_P_Rt_Flt 100;
BA_ "GenSigSendType" SG_ 643 LoBm_P_Rt_Flt 5;
BA_ "FlexKomComment" SG_ 643 RevGr_Engg "Reverse gear engaged";
BA_ "FlexKomIsMotorola" SG_ 643 RevGr_Engg 1;
BA_ "FlexKomSID" SG_ 643 RevGr_Engg 117440888;
BA_ "FlexKomSigLaenge" SG_ 643 RevGr_Engg 2;
BA_ "FlexKomSigName" SG_ 643 RevGr_Engg "RevGr_Engg";
BA_ "FlexKomSigStartPos" SG_ 643 RevGr_Engg 39;
BA_ "FlexKomSigStartValue" SG_ 643 RevGr_Engg "03h";
BA_ "GenSigCycleTime" SG_ 643 RevGr_Engg 100;
BA_ "GenSigSNA" SG_ 643 RevGr_Engg "3";
BA_ "GenSigSendType" SG_ 643 RevGr_Engg 5;
BA_ "GenSigStartValue" SG_ 643 RevGr_Engg 3;
BA_ "GenSigTimeout_ESP_ABR" SG_ 643 RevGr_Engg 1550;
BA_ "GenSigTimeout_PTS" SG_ 643 RevGr_Engg 550;
BA_ "GenSigTimeout_TPM" SG_ 643 RevGr_Engg 1550;
BA_ "FlexKomComment" SG_ 643 AirTemp_Insd "Inside air temperature";
BA_ "FlexKomIsMotorola" SG_ 643 AirTemp_Insd 1;
BA_ "FlexKomSID" SG_ 643 AirTemp_Insd 117441463;
BA_ "FlexKomSigLaenge" SG_ 643 AirTemp_Insd 8;
BA_ "FlexKomSigName" SG_ 643 AirTemp_Insd "AirTemp_Insd";
BA_ "FlexKomSigStartPos" SG_ 643 AirTemp_Insd 47;
BA_ "FlexKomSigStartValue" SG_ 643 AirTemp_Insd "FFh";
BA_ "GenSigCycleTime" SG_ 643 AirTemp_Insd 100;
BA_ "GenSigSNA" SG_ 643 AirTemp_Insd "255";
BA_ "GenSigSendType" SG_ 643 AirTemp_Insd 7;
BA_ "GenSigStartValue" SG_ 643 AirTemp_Insd 255;
BA_ "GenSigTimeout_NV" SG_ 643 AirTemp_Insd 2050;
BA_ "GenSigTimeout_RBTM_FL" SG_ 643 AirTemp_Insd 2050;
BA_ "GenSigTimeout_RBTM_FR" SG_ 643 AirTemp_Insd 2050;
BA_ "FlexKomComment" SG_ 643 Bckl_Sw_RL_Stat_SAM_R "Buckle switch rear left state (by SAM_R)";
BA_ "FlexKomIsMotorola" SG_ 643 Bckl_Sw_RL_Stat_SAM_R 1;
BA_ "FlexKomSID" SG_ 643 Bckl_Sw_RL_Stat_SAM_R 117440526;
BA_ "FlexKomSigLaenge" SG_ 643 Bckl_Sw_RL_Stat_SAM_R 2;
BA_ "FlexKomSigName" SG_ 643 Bckl_Sw_RL_Stat_SAM_R "Bckl_Sw_RL_Stat_SAM_R";
BA_ "FlexKomSigStartPos" SG_ 643 Bckl_Sw_RL_Stat_SAM_R 49;
BA_ "FlexKomSigStartValue" SG_ 643 Bckl_Sw_RL_Stat_SAM_R "03h";
BA_ "GenSigCycleTime" SG_ 643 Bckl_Sw_RL_Stat_SAM_R 100;
BA_ "GenSigSNA" SG_ 643 Bckl_Sw_RL_Stat_SAM_R "3";
BA_ "GenSigSendType" SG_ 643 Bckl_Sw_RL_Stat_SAM_R 5;
BA_ "GenSigStartValue" SG_ 643 Bckl_Sw_RL_Stat_SAM_R 3;
BA_ "GenSigTimeout_ORC" SG_ 643 Bckl_Sw_RL_Stat_SAM_R 1050;
BA_ "FlexKomComment" SG_ 643 Bckl_Sw_RR_Stat_SAM_R "Buckle switch rear right state (by SAM_R)";
BA_ "FlexKomIsMotorola" SG_ 643 Bckl_Sw_RR_Stat_SAM_R 1;
BA_ "FlexKomSID" SG_ 643 Bckl_Sw_RR_Stat_SAM_R 117440527;
BA_ "FlexKomSigLaenge" SG_ 643 Bckl_Sw_RR_Stat_SAM_R 2;
BA_ "FlexKomSigName" SG_ 643 Bckl_Sw_RR_Stat_SAM_R "Bckl_Sw_RR_Stat_SAM_R";
BA_ "FlexKomSigStartPos" SG_ 643 Bckl_Sw_RR_Stat_SAM_R 51;
BA_ "FlexKomSigStartValue" SG_ 643 Bckl_Sw_RR_Stat_SAM_R "03h";
BA_ "GenSigCycleTime" SG_ 643 Bckl_Sw_RR_Stat_SAM_R 100;
BA_ "GenSigSNA" SG_ 643 Bckl_Sw_RR_Stat_SAM_R "3";
BA_ "GenSigSendType" SG_ 643 Bckl_Sw_RR_Stat_SAM_R 5;
BA_ "GenSigStartValue" SG_ 643 Bckl_Sw_RR_Stat_SAM_R 3;
BA_ "GenSigTimeout_ORC" SG_ 643 Bckl_Sw_RR_Stat_SAM_R 1050;
BA_ "FlexKomComment" SG_ 643 Bckl_Sw_RM_Stat_SAM_R "Buckle switch rear middle state (by SAM_R)";
BA_ "FlexKomIsMotorola" SG_ 643 Bckl_Sw_RM_Stat_SAM_R 1;
BA_ "FlexKomSID" SG_ 643 Bckl_Sw_RM_Stat_SAM_R 117440528;
BA_ "FlexKomSigLaenge" SG_ 643 Bckl_Sw_RM_Stat_SAM_R 2;
BA_ "FlexKomSigName" SG_ 643 Bckl_Sw_RM_Stat_SAM_R "Bckl_Sw_RM_Stat_SAM_R";
BA_ "FlexKomSigStartPos" SG_ 643 Bckl_Sw_RM_Stat_SAM_R 53;
BA_ "FlexKomSigStartValue" SG_ 643 Bckl_Sw_RM_Stat_SAM_R "03h";
BA_ "GenSigCycleTime" SG_ 643 Bckl_Sw_RM_Stat_SAM_R 100;
BA_ "GenSigSNA" SG_ 643 Bckl_Sw_RM_Stat_SAM_R "3";
BA_ "GenSigSendType" SG_ 643 Bckl_Sw_RM_Stat_SAM_R 5;
BA_ "GenSigStartValue" SG_ 643 Bckl_Sw_RM_Stat_SAM_R 3;
BA_ "GenSigTimeout_ORC" SG_ 643 Bckl_Sw_RM_Stat_SAM_R 1050;
BA_ "FlexKomComment" SG_ 643 StW_Cond_Stat "Steering wheel conditioning state";
BA_ "FlexKomIsMotorola" SG_ 643 StW_Cond_Stat 1;
BA_ "FlexKomSID" SG_ 643 StW_Cond_Stat 117441026;
BA_ "FlexKomSigLaenge" SG_ 643 StW_Cond_Stat 2;
BA_ "FlexKomSigName" SG_ 643 StW_Cond_Stat "StW_Cond_Stat";
BA_ "FlexKomSigStartPos" SG_ 643 StW_Cond_Stat 55;
BA_ "FlexKomSigStartValue" SG_ 643 StW_Cond_Stat "00h";
BA_ "GenSigCycleTime" SG_ 643 StW_Cond_Stat 100;
BA_ "GenSigSendType" SG_ 643 StW_Cond_Stat 5;
BA_ "GenSigTimeout_SCCM" SG_ 643 StW_Cond_Stat 1050;
BA_ "FlexKomComment" SG_ 643 AirTemp_Outsd "Outside air temperature";
BA_ "FlexKomIsMotorola" SG_ 643 AirTemp_Outsd 1;
BA_ "FlexKomSID" SG_ 643 AirTemp_Outsd 117440542;
BA_ "FlexKomSigLaenge" SG_ 643 AirTemp_Outsd 8;
BA_ "FlexKomSigName" SG_ 643 AirTemp_Outsd "AirTemp_Outsd";
BA_ "FlexKomSigStartPos" SG_ 643 AirTemp_Outsd 63;
BA_ "FlexKomSigStartValue" SG_ 643 AirTemp_Outsd "FFh";
BA_ "GenSigCycleTime" SG_ 643 AirTemp_Outsd 100;
BA_ "GenSigSNA" SG_ 643 AirTemp_Outsd "255";
BA_ "GenSigSendType" SG_ 643 AirTemp_Outsd 7;
BA_ "GenSigStartValue" SG_ 643 AirTemp_Outsd 255;
BA_ "GenSigTimeout_ESP_ABR" SG_ 643 AirTemp_Outsd 1550;
BA_ "GenSigTimeout_RBTM_FL" SG_ 643 AirTemp_Outsd 2050;
BA_ "GenSigTimeout_RBTM_FR" SG_ 643 AirTemp_Outsd 2050;
BA_ "GenSigTimeout_SPC" SG_ 643 AirTemp_Outsd 1050;
BA_ "FlexKomComment" SG_ 15 CGW_Rout_Stat "CGW routing status";
BA_ "FlexKomIsMotorola" SG_ 15 CGW_Rout_Stat 1;
BA_ "FlexKomSID" SG_ 15 CGW_Rout_Stat 117442887;
BA_ "FlexKomSigLaenge" SG_ 15 CGW_Rout_Stat 2;
BA_ "FlexKomSigName" SG_ 15 CGW_Rout_Stat "CGW_Rout_Stat";
BA_ "FlexKomSigStartPos" SG_ 15 CGW_Rout_Stat 1;
BA_ "FlexKomSigStartValue" SG_ 15 CGW_Rout_Stat "00h";
BA_ "GenSigCycleTime" SG_ 15 CGW_Rout_Stat 20;
BA_ "GenSigSendType" SG_ 15 CGW_Rout_Stat 9;
BA_ "GenSigTimeout_PTS" SG_ 15 CGW_Rout_Stat 210;
BA_ "FlexKomComment" SG_ 15 BusFlt_PrmntActv "Bus faulty, permanent active";
BA_ "FlexKomIsMotorola" SG_ 15 BusFlt_PrmntActv 1;
BA_ "FlexKomSID" SG_ 15 BusFlt_PrmntActv 117443540;
BA_ "FlexKomSigLaenge" SG_ 15 BusFlt_PrmntActv 1;
BA_ "FlexKomSigName" SG_ 15 BusFlt_PrmntActv "BusFlt_PrmntActv";
BA_ "FlexKomSigStartPos" SG_ 15 BusFlt_PrmntActv 2;
BA_ "FlexKomSigStartValue" SG_ 15 BusFlt_PrmntActv "00h";
BA_ "GenSigCycleTime" SG_ 15 BusFlt_PrmntActv 20;
BA_ "GenSigSendType" SG_ 15 BusFlt_PrmntActv 9;
BA_ "FieldType" SG_ 556 CHG_mainState "CHG_mainState";
BA_ "FieldType" SG_ 556 CHG_proximity "CHG_proximity";
BA_ "GenSigSNA" SG_ 556 CHG_proximity "0";
BA_ "FieldType" SG_ 556 CHG_pilot "CHG_pilot";
BA_ "GenSigSNA" SG_ 556 CHG_pilot "7";
BA_ "FieldType" SG_ 556 CHG_cableType "CHG_cableType";
BA_ "GenSigSNA" SG_ 556 CHG_cableType "4";
BA_ "GenSigStartValue" SG_ 556 CHG_cableType 2;
BA_ "FieldType" SG_ 556 CHG_cableState "CHG_cableState";
BA_ "GenSigSNA" SG_ 556 CHG_cableState "2";
BA_ "GenSigStartValue" SG_ 556 CHG_cableState 2;
BA_ "FieldType" SG_ 556 CHG_phaseConfig "CHG_phaseConfig";
BA_ "GenSigSNA" SG_ 556 CHG_phaseConfig "4";
BA_ "GenSigStartValue" SG_ 556 CHG_phaseConfig 4;
BA_ "FieldType" SG_ 556 CHG_subState "CHG_subState";
BA_ "FieldType" SG_ 556 CHG_inputRelayState "CHG_inputRelayState";
BA_ "GenSigSNA" SG_ 556 CHG_inputRelayState "3";
BA_ "PektronUpdateBitType" SG_ 1034 CH_bcNmKeepNetwork 1;
BA_ "PektronUpdateBitType" SG_ 1034 CH_bcNmWakeNetwork 1;
BA_ "GenSigStartValue" SG_ 1032 CH_gtwNmHeartBeat_UB 1;
BA_ "PektronUpdateBitType" SG_ 1032 CH_gtwNmHeartBeat_UB 1;
BA_ "GenSigStartValue" SG_ 1032 CH_gtwNmHeartBeat 1;
BA_ "PektronUpdateBitType" SG_ 1032 CH_gtwNmHeartBeat 1;
BA_ "PektronUpdateBitType" SG_ 1032 CH_gtwNmShutUp 1;
BA_ "PektronUpdateBitType" SG_ 1030 CH_scNmWakeNetwork 1;
BA_ "PektronUpdateBitType" SG_ 1030 CH_scNmWakeNetwork_UB 1;
BA_ "FlexKomComment" SG_ 21 SwIllLvl "Switch illumination level (Term. 58d)";
BA_ "FlexKomIsMotorola" SG_ 21 SwIllLvl 1;
BA_ "FlexKomSID" SG_ 21 SwIllLvl 117440841;
BA_ "FlexKomSigLaenge" SG_ 21 SwIllLvl 8;
BA_ "FlexKomSigName" SG_ 21 SwIllLvl "SwIllLvl";
BA_ "FlexKomSigStartPos" SG_ 21 SwIllLvl 7;
BA_ "FlexKomSigStartValue" SG_ 21 SwIllLvl "FFh";
BA_ "GenSigCycleTime" SG_ 21 SwIllLvl 200;
BA_ "GenSigSNA" SG_ 21 SwIllLvl "255";
BA_ "GenSigSendType" SG_ 21 SwIllLvl 5;
BA_ "GenSigStartValue" SG_ 21 SwIllLvl 255;
BA_ "GenSigTimeout_DRVU" SG_ 21 SwIllLvl 2100;
BA_ "GenSigTimeout_SCCM" SG_ 21 SwIllLvl 2100;
BA_ "FlexKomComment" SG_ 21 DispBrt_IC "Display brightness instrument cluster";
BA_ "FlexKomIsMotorola" SG_ 21 DispBrt_IC 1;
BA_ "FlexKomSID" SG_ 21 DispBrt_IC 117442289;
BA_ "FlexKomSigLaenge" SG_ 21 DispBrt_IC 8;
BA_ "FlexKomSigName" SG_ 21 DispBrt_IC "DispBrt_IC";
BA_ "FlexKomSigStartPos" SG_ 21 DispBrt_IC 15;
BA_ "FlexKomSigStartValue" SG_ 21 DispBrt_IC "FFh";
BA_ "GenSigCycleTime" SG_ 21 DispBrt_IC 200;
BA_ "GenSigSNA" SG_ 21 DispBrt_IC "255";
BA_ "GenSigSendType" SG_ 21 DispBrt_IC 5;
BA_ "GenSigStartValue" SG_ 21 DispBrt_IC 255;
BA_ "GenSigTimeout_PTS" SG_ 21 DispBrt_IC 2100;
BA_ "FlexKomComment" SG_ 519 Group "Common vehicle identification";
BA_ "FlexKomIsMotorola" SG_ 519 Group 1;
BA_ "FlexKomSID" SG_ 519 Group 117440517;
BA_ "FlexKomSigLaenge" SG_ 519 Group 64;
BA_ "FlexKomSigName" SG_ 519 Group "VehCommonId";
BA_ "FlexKomSigStartPos" SG_ 519 Group 7;
BA_ "FlexKomSigStartValue" SG_ 519 Group "FFFF7F7FFF00EFFFh";
BA_ "GenSigCycleTime" SG_ 519 Group 300;
BA_ "GenSigSNA" SG_ 519 Group "15";
BA_ "GenSigSendType" SG_ 519 Group 7;
BA_ "GenSigStartValue" SG_ 519 Group 15;
BA_ "GenSigTimeout_ORC" SG_ 519 Group 3150;
BA_ "GenSigTimeout_RBTM_FL" SG_ 519 Group 3150;
BA_ "GenSigTimeout_RBTM_FR" SG_ 519 Group 3150;
BA_ "GenSigTimeout_SCCM" SG_ 519 Group 3150;
BA_ "FlexKomComment" SG_ 519 Country "Common vehicle identification";
BA_ "FlexKomIsMotorola" SG_ 519 Country 1;
BA_ "FlexKomSID" SG_ 519 Country 117440517;
BA_ "FlexKomSigLaenge" SG_ 519 Country 64;
BA_ "FlexKomSigName" SG_ 519 Country "VehCommonId";
BA_ "FlexKomSigStartPos" SG_ 519 Country 7;
BA_ "FlexKomSigStartValue" SG_ 519 Country "FFFF7F7FFF00EFFFh";
BA_ "GenSigCycleTime" SG_ 519 Country 300;
BA_ "GenSigSNA" SG_ 519 Country "15";
BA_ "GenSigSendType" SG_ 519 Country 7;
BA_ "GenSigStartValue" SG_ 519 Country 15;
BA_ "GenSigTimeout_MPC" SG_ 519 Country 3150;
BA_ "GenSigTimeout_NV" SG_ 519 Country 6150;
BA_ "GenSigTimeout_ORC" SG_ 519 Country 3150;
BA_ "GenSigTimeout_RBTM_FL" SG_ 519 Country 3150;
BA_ "GenSigTimeout_RBTM_FR" SG_ 519 Country 3150;
BA_ "GenSigTimeout_SPC" SG_ 519 Country 3150;
BA_ "GenSigTimeout_TPM" SG_ 519 Country 4650;
BA_ "FlexKomComment" SG_ 519 VehLine "Common vehicle identification";
BA_ "FlexKomIsMotorola" SG_ 519 VehLine 1;
BA_ "FlexKomSID" SG_ 519 VehLine 117440517;
BA_ "FlexKomSigLaenge" SG_ 519 VehLine 64;
BA_ "FlexKomSigName" SG_ 519 VehLine "VehCommonId";
BA_ "FlexKomSigStartPos" SG_ 519 VehLine 7;
BA_ "FlexKomSigStartValue" SG_ 519 VehLine "FFFF7F7FFF00EFFFh";
BA_ "GenSigCycleTime" SG_ 519 VehLine 300;
BA_ "GenSigSNA" SG_ 519 VehLine "63";
BA_ "GenSigSendType" SG_ 519 VehLine 7;
BA_ "GenSigStartValue" SG_ 519 VehLine 63;
BA_ "GenSigTimeout_MPC" SG_ 519 VehLine 3150;
BA_ "GenSigTimeout_NV" SG_ 519 VehLine 6150;
BA_ "GenSigTimeout_ORC" SG_ 519 VehLine 3150;
BA_ "GenSigTimeout_PTS" SG_ 519 VehLine 3150;
BA_ "GenSigTimeout_RBTM_FL" SG_ 519 VehLine 3150;
BA_ "GenSigTimeout_RBTM_FR" SG_ 519 VehLine 3150;
BA_ "GenSigTimeout_SCCM" SG_ 519 VehLine 3150;
BA_ "GenSigTimeout_SPC" SG_ 519 VehLine 3150;
BA_ "GenSigTimeout_TPM" SG_ 519 VehLine 4650;
BA_ "FlexKomComment" SG_ 519 Guard "Common vehicle identification";
BA_ "FlexKomIsMotorola" SG_ 519 Guard 1;
BA_ "FlexKomSID" SG_ 519 Guard 117440517;
BA_ "FlexKomSigLaenge" SG_ 519 Guard 64;
BA_ "FlexKomSigName" SG_ 519 Guard "VehCommonId";
BA_ "FlexKomSigStartPos" SG_ 519 Guard 7;
BA_ "FlexKomSigStartValue" SG_ 519 Guard "FFFF7F7FFF00EFFFh";
BA_ "GenSigCycleTime" SG_ 519 Guard 300;
BA_ "GenSigSNA" SG_ 519 Guard "3";
BA_ "GenSigSendType" SG_ 519 Guard 7;
BA_ "GenSigStartValue" SG_ 519 Guard 3;
BA_ "GenSigTimeout_MPC" SG_ 519 Guard 3150;
BA_ "GenSigTimeout_NV" SG_ 519 Guard 6150;
BA_ "GenSigTimeout_PTS" SG_ 519 Guard 3150;
BA_ "GenSigTimeout_SPC" SG_ 519 Guard 3150;
BA_ "GenSigTimeout_TPM" SG_ 519 Guard 4650;
BA_ "FlexKomComment" SG_ 519 VehLinePack "Common vehicle identification";
BA_ "FlexKomIsMotorola" SG_ 519 VehLinePack 1;
BA_ "FlexKomSID" SG_ 519 VehLinePack 117440517;
BA_ "FlexKomSigLaenge" SG_ 519 VehLinePack 64;
BA_ "FlexKomSigName" SG_ 519 VehLinePack "VehCommonId";
BA_ "FlexKomSigStartPos" SG_ 519 VehLinePack 7;
BA_ "FlexKomSigStartValue" SG_ 519 VehLinePack "FFFF7F7FFF00EFFFh";
BA_ "GenSigCycleTime" SG_ 519 VehLinePack 300;
BA_ "GenSigSendType" SG_ 519 VehLinePack 7;
BA_ "GenSigStartValue" SG_ 519 VehLinePack 3;
BA_ "GenSigTimeout_RBTM_FL" SG_ 519 VehLinePack 3150;
BA_ "GenSigTimeout_RBTM_FR" SG_ 519 VehLinePack 3150;
BA_ "GenSigTimeout_SPC" SG_ 519 VehLinePack 3150;
BA_ "GenSigTimeout_TPM" SG_ 519 VehLinePack 4650;
BA_ "FlexKomComment" SG_ 519 VehLineYear "Common vehicle identification";
BA_ "FlexKomIsMotorola" SG_ 519 VehLineYear 1;
BA_ "FlexKomSID" SG_ 519 VehLineYear 117440517;
BA_ "FlexKomSigLaenge" SG_ 519 VehLineYear 64;
BA_ "FlexKomSigName" SG_ 519 VehLineYear "VehCommonId";
BA_ "FlexKomSigStartPos" SG_ 519 VehLineYear 7;
BA_ "FlexKomSigStartValue" SG_ 519 VehLineYear "FFFF7F7FFF00EFFFh";
BA_ "GenSigCycleTime" SG_ 519 VehLineYear 300;
BA_ "GenSigSendType" SG_ 519 VehLineYear 7;
BA_ "GenSigStartValue" SG_ 519 VehLineYear 31;
BA_ "GenSigTimeout_MPC" SG_ 519 VehLineYear 3150;
BA_ "GenSigTimeout_NV" SG_ 519 VehLineYear 6150;
BA_ "GenSigTimeout_RBTM_FL" SG_ 519 VehLineYear 3150;
BA_ "GenSigTimeout_RBTM_FR" SG_ 519 VehLineYear 3150;
BA_ "GenSigTimeout_SPC" SG_ 519 VehLineYear 3150;
BA_ "GenSigTimeout_TPM" SG_ 519 VehLineYear 4650;
BA_ "FlexKomComment" SG_ 519 VSTS_Avl "Common vehicle identification";
BA_ "FlexKomIsMotorola" SG_ 519 VSTS_Avl 1;
BA_ "FlexKomSID" SG_ 519 VSTS_Avl 117440517;
BA_ "FlexKomSigLaenge" SG_ 519 VSTS_Avl 64;
BA_ "FlexKomSigName" SG_ 519 VSTS_Avl "VehCommonId";
BA_ "FlexKomSigStartPos" SG_ 519 VSTS_Avl 7;
BA_ "FlexKomSigStartValue" SG_ 519 VSTS_Avl "FFFF7F7FFF00EFFFh";
BA_ "GenSigCycleTime" SG_ 519 VSTS_Avl 300;
BA_ "GenSigSendType" SG_ 519 VSTS_Avl 7;
BA_ "GenSigTimeout_MPC" SG_ 519 VSTS_Avl 3150;
BA_ "GenSigTimeout_NV" SG_ 519 VSTS_Avl 6150;
BA_ "GenSigTimeout_PTS" SG_ 519 VSTS_Avl 3150;
BA_ "FlexKomComment" SG_ 519 BodyStyle "Common vehicle identification";
BA_ "FlexKomIsMotorola" SG_ 519 BodyStyle 1;
BA_ "FlexKomSID" SG_ 519 BodyStyle 117440517;
BA_ "FlexKomSigLaenge" SG_ 519 BodyStyle 64;
BA_ "FlexKomSigName" SG_ 519 BodyStyle "VehCommonId";
BA_ "FlexKomSigStartPos" SG_ 519 BodyStyle 7;
BA_ "FlexKomSigStartValue" SG_ 519 BodyStyle "FFFF7F7FFF00EFFFh";
BA_ "GenSigCycleTime" SG_ 519 BodyStyle 300;
BA_ "GenSigSNA" SG_ 519 BodyStyle "31";
BA_ "GenSigSendType" SG_ 519 BodyStyle 7;
BA_ "GenSigStartValue" SG_ 519 BodyStyle 31;
BA_ "GenSigTimeout_MPC" SG_ 519 BodyStyle 3150;
BA_ "GenSigTimeout_NV" SG_ 519 BodyStyle 6150;
BA_ "GenSigTimeout_ORC" SG_ 519 BodyStyle 3150;
BA_ "GenSigTimeout_PTS" SG_ 519 BodyStyle 3150;
BA_ "GenSigTimeout_SPC" SG_ 519 BodyStyle 3150;
BA_ "GenSigTimeout_TPM" SG_ 519 BodyStyle 4650;
BA_ "FlexKomComment" SG_ 519 StStyle "Common vehicle identification";
BA_ "FlexKomIsMotorola" SG_ 519 StStyle 1;
BA_ "FlexKomSID" SG_ 519 StStyle 117440517;
BA_ "FlexKomSigLaenge" SG_ 519 StStyle 64;
BA_ "FlexKomSigName" SG_ 519 StStyle "VehCommonId";
BA_ "FlexKomSigStartPos" SG_ 519 StStyle 7;
BA_ "FlexKomSigStartValue" SG_ 519 StStyle "FFFF7F7FFF00EFFFh";
BA_ "GenSigCycleTime" SG_ 519 StStyle 300;
BA_ "GenSigSNA" SG_ 519 StStyle "3";
BA_ "GenSigSendType" SG_ 519 StStyle 7;
BA_ "GenSigStartValue" SG_ 519 StStyle 3;
BA_ "GenSigTimeout_MPC" SG_ 519 StStyle 3150;
BA_ "GenSigTimeout_NV" SG_ 519 StStyle 6150;
BA_ "GenSigTimeout_ORC" SG_ 519 StStyle 3150;
BA_ "GenSigTimeout_PTS" SG_ 519 StStyle 3150;
BA_ "GenSigTimeout_RBTM_FL" SG_ 519 StStyle 3150;
BA_ "GenSigTimeout_RBTM_FR" SG_ 519 StStyle 3150;
BA_ "GenSigTimeout_SCCM" SG_ 519 StStyle 3150;
BA_ "FlexKomComment" SG_ 519 PSTS_Avl "Common vehicle identification";
BA_ "FlexKomIsMotorola" SG_ 519 PSTS_Avl 1;
BA_ "FlexKomSID" SG_ 519 PSTS_Avl 117440517;
BA_ "FlexKomSigLaenge" SG_ 519 PSTS_Avl 64;
BA_ "FlexKomSigName" SG_ 519 PSTS_Avl "VehCommonId";
BA_ "FlexKomSigStartPos" SG_ 519 PSTS_Avl 7;
BA_ "FlexKomSigStartValue" SG_ 519 PSTS_Avl "FFFF7F7FFF00EFFFh";
BA_ "GenSigCycleTime" SG_ 519 PSTS_Avl 300;
BA_ "GenSigSendType" SG_ 519 PSTS_Avl 7;
BA_ "GenSigTimeout_MPC" SG_ 519 PSTS_Avl 3150;
BA_ "GenSigTimeout_NV" SG_ 519 PSTS_Avl 6150;
BA_ "FlexKomComment" SG_ 519 EngStyle "Engine identification";
BA_ "FlexKomIsMotorola" SG_ 519 EngStyle 1;
BA_ "FlexKomSID" SG_ 519 EngStyle 117441537;
BA_ "FlexKomSigLaenge" SG_ 519 EngStyle 32;
BA_ "FlexKomSigName" SG_ 519 EngStyle "Eng_Id";
BA_ "FlexKomSigStartPos" SG_ 519 EngStyle 7;
BA_ "FlexKomSigStartValue" SG_ 519 EngStyle "FF0000FFh";
BA_ "GenSigCycleTime" SG_ 519 EngStyle 300;
BA_ "GenSigSNA" SG_ 519 EngStyle "255";
BA_ "GenSigSendType" SG_ 519 EngStyle 7;
BA_ "GenSigStartValue" SG_ 519 EngStyle 255;
BA_ "GenSigTimeout_CGW" SG_ 519 EngStyle 3150;
BA_ "FlexKomComment" SG_ 519 TCM_Avl "Common vehicle identification";
BA_ "FlexKomIsMotorola" SG_ 519 TCM_Avl 1;
BA_ "FlexKomSID" SG_ 519 TCM_Avl 117440517;
BA_ "FlexKomSigLaenge" SG_ 519 TCM_Avl 64;
BA_ "FlexKomSigName" SG_ 519 TCM_Avl "VehCommonId";
BA_ "FlexKomSigStartPos" SG_ 519 TCM_Avl 7;
BA_ "FlexKomSigStartValue" SG_ 519 TCM_Avl "FFFF7F7FFF00EFFFh";
BA_ "GenSigCycleTime" SG_ 519 TCM_Avl 300;
BA_ "GenSigSendType" SG_ 519 TCM_Avl 7;
BA_ "GenSigTimeout_PTS" SG_ 519 TCM_Avl 3150;
BA_ "FlexKomComment" SG_ 519 HVAC_Avl "Common vehicle identification";
BA_ "FlexKomIsMotorola" SG_ 519 HVAC_Avl 1;
BA_ "FlexKomSID" SG_ 519 HVAC_Avl 117440517;
BA_ "FlexKomSigLaenge" SG_ 519 HVAC_Avl 64;
BA_ "FlexKomSigName" SG_ 519 HVAC_Avl "VehCommonId";
BA_ "FlexKomSigStartPos" SG_ 519 HVAC_Avl 7;
BA_ "FlexKomSigStartValue" SG_ 519 HVAC_Avl "FFFF7F7FFF00EFFFh";
BA_ "GenSigCycleTime" SG_ 519 HVAC_Avl 300;
BA_ "GenSigSendType" SG_ 519 HVAC_Avl 7;
BA_ "FlexKomComment" SG_ 519 TrlrHtch_Avl "Common vehicle identification";
BA_ "FlexKomIsMotorola" SG_ 519 TrlrHtch_Avl 1;
BA_ "FlexKomSID" SG_ 519 TrlrHtch_Avl 117440517;
BA_ "FlexKomSigLaenge" SG_ 519 TrlrHtch_Avl 64;
BA_ "FlexKomSigName" SG_ 519 TrlrHtch_Avl "VehCommonId";
BA_ "FlexKomSigStartPos" SG_ 519 TrlrHtch_Avl 7;
BA_ "FlexKomSigStartValue" SG_ 519 TrlrHtch_Avl "FFFF7F7FFF00EFFFh";
BA_ "GenSigCycleTime" SG_ 519 TrlrHtch_Avl 300;
BA_ "GenSigSendType" SG_ 519 TrlrHtch_Avl 7;
BA_ "GenSigTimeout_ESP_ABR" SG_ 519 TrlrHtch_Avl 4650;
BA_ "GenSigTimeout_PTS" SG_ 519 TrlrHtch_Avl 3150;
BA_ "FlexKomComment" SG_ 519 VTA_Avl "Common vehicle identification";
BA_ "FlexKomIsMotorola" SG_ 519 VTA_Avl 1;
BA_ "FlexKomSID" SG_ 519 VTA_Avl 117440517;
BA_ "FlexKomSigLaenge" SG_ 519 VTA_Avl 64;
BA_ "FlexKomSigName" SG_ 519 VTA_Avl "VehCommonId";
BA_ "FlexKomSigStartPos" SG_ 519 VTA_Avl 7;
BA_ "FlexKomSigStartValue" SG_ 519 VTA_Avl "FFFF7F7FFF00EFFFh";
BA_ "GenSigCycleTime" SG_ 519 VTA_Avl 300;
BA_ "GenSigSendType" SG_ 519 VTA_Avl 7;
BA_ "FlexKomComment" SG_ 519 PCD_Avl "Common vehicle identification";
BA_ "FlexKomIsMotorola" SG_ 519 PCD_Avl 1;
BA_ "FlexKomSID" SG_ 519 PCD_Avl 117440517;
BA_ "FlexKomSigLaenge" SG_ 519 PCD_Avl 64;
BA_ "FlexKomSigName" SG_ 519 PCD_Avl "VehCommonId";
BA_ "FlexKomSigStartPos" SG_ 519 PCD_Avl 7;
BA_ "FlexKomSigStartValue" SG_ 519 PCD_Avl "FFFF7F7FFF00EFFFh";
BA_ "GenSigCycleTime" SG_ 519 PCD_Avl 300;
BA_ "GenSigSendType" SG_ 519 PCD_Avl 8;
BA_ "FlexKomComment" SG_ 519 ICH_Avl "Common vehicle identification";
BA_ "FlexKomIsMotorola" SG_ 519 ICH_Avl 1;
BA_ "FlexKomSID" SG_ 519 ICH_Avl 117440517;
BA_ "FlexKomSigLaenge" SG_ 519 ICH_Avl 64;
BA_ "FlexKomSigName" SG_ 519 ICH_Avl "VehCommonId";
BA_ "FlexKomSigStartPos" SG_ 519 ICH_Avl 7;
BA_ "FlexKomSigStartValue" SG_ 519 ICH_Avl "FFFF7F7FFF00EFFFh";
BA_ "GenSigCycleTime" SG_ 519 ICH_Avl 300;
BA_ "GenSigSendType" SG_ 519 ICH_Avl 7;
BA_ "FlexKomComment" SG_ 519 LgtSens_Avl "Common vehicle identification";
BA_ "FlexKomIsMotorola" SG_ 519 LgtSens_Avl 1;
BA_ "FlexKomSID" SG_ 519 LgtSens_Avl 117440517;
BA_ "FlexKomSigLaenge" SG_ 519 LgtSens_Avl 64;
BA_ "FlexKomSigName" SG_ 519 LgtSens_Avl "VehCommonId";
BA_ "FlexKomSigStartPos" SG_ 519 LgtSens_Avl 7;
BA_ "FlexKomSigStartValue" SG_ 519 LgtSens_Avl "FFFF7F7FFF00EFFFh";
BA_ "GenSigCycleTime" SG_ 519 LgtSens_Avl 300;
BA_ "GenSigSendType" SG_ 519 LgtSens_Avl 7;
BA_ "GenSigTimeout_PTS" SG_ 519 LgtSens_Avl 3150;
BA_ "FlexKomComment" SG_ 519 RainSens_Avl "Common vehicle identification";
BA_ "FlexKomIsMotorola" SG_ 519 RainSens_Avl 1;
BA_ "FlexKomSID" SG_ 519 RainSens_Avl 117440517;
BA_ "FlexKomSigLaenge" SG_ 519 RainSens_Avl 64;
BA_ "FlexKomSigName" SG_ 519 RainSens_Avl "VehCommonId";
BA_ "FlexKomSigStartPos" SG_ 519 RainSens_Avl 7;
BA_ "FlexKomSigStartValue" SG_ 519 RainSens_Avl "FFFF7F7FFF00EFFFh";
BA_ "GenSigCycleTime" SG_ 519 RainSens_Avl 300;
BA_ "GenSigSendType" SG_ 519 RainSens_Avl 7;
BA_ "GenSigTimeout_MPC" SG_ 519 RainSens_Avl 3150;
BA_ "FlexKomComment" SG_ 519 HVACStyle "Common vehicle identification";
BA_ "FlexKomIsMotorola" SG_ 519 HVACStyle 1;
BA_ "FlexKomSID" SG_ 519 HVACStyle 117440517;
BA_ "FlexKomSigLaenge" SG_ 519 HVACStyle 64;
BA_ "FlexKomSigName" SG_ 519 HVACStyle "VehCommonId";
BA_ "FlexKomSigStartPos" SG_ 519 HVACStyle 7;
BA_ "FlexKomSigStartValue" SG_ 519 HVACStyle "FFFF7F7FFF00EFFFh";
BA_ "GenSigCycleTime" SG_ 519 HVACStyle 300;
BA_ "GenSigSendType" SG_ 519 HVACStyle 7;
BA_ "GenSigStartValue" SG_ 519 HVACStyle 3;
BA_ "FlexKomComment" SG_ 519 VehOPTPack "Common vehicle identification";
BA_ "FlexKomIsMotorola" SG_ 519 VehOPTPack 1;
BA_ "FlexKomSID" SG_ 519 VehOPTPack 117440517;
BA_ "FlexKomSigLaenge" SG_ 519 VehOPTPack 64;
BA_ "FlexKomSigName" SG_ 519 VehOPTPack "VehCommonId";
BA_ "FlexKomSigStartPos" SG_ 519 VehOPTPack 7;
BA_ "FlexKomSigStartValue" SG_ 519 VehOPTPack "FFFF7F7FFF00EFFFh";
BA_ "GenSigCycleTime" SG_ 519 VehOPTPack 300;
BA_ "GenSigSNA" SG_ 519 VehOPTPack "3";
BA_ "GenSigSendType" SG_ 519 VehOPTPack 7;
BA_ "GenSigStartValue" SG_ 519 VehOPTPack 3;
BA_ "GenSigTimeout_MPC" SG_ 519 VehOPTPack 3150;
BA_ "GenSigTimeout_SPC" SG_ 519 VehOPTPack 3150;
BA_ "FlexKomComment" SG_ 519 Cplt_SL_Enbl "Common vehicle identification";
BA_ "FlexKomIsMotorola" SG_ 519 Cplt_SL_Enbl 1;
BA_ "FlexKomSID" SG_ 519 Cplt_SL_Enbl 117440517;
BA_ "FlexKomSigLaenge" SG_ 519 Cplt_SL_Enbl 64;
BA_ "FlexKomSigName" SG_ 519 Cplt_SL_Enbl "VehCommonId";
BA_ "FlexKomSigStartPos" SG_ 519 Cplt_SL_Enbl 7;
BA_ "FlexKomSigStartValue" SG_ 519 Cplt_SL_Enbl "FFFF7F7FFF00EFFFh";
BA_ "GenSigCycleTime" SG_ 519 Cplt_SL_Enbl 300;
BA_ "GenSigSendType" SG_ 519 Cplt_SL_Enbl 7;
BA_ "FlexKomComment" SG_ 519 RoofStyle "Common vehicle identification";
BA_ "FlexKomIsMotorola" SG_ 519 RoofStyle 1;
BA_ "FlexKomSID" SG_ 519 RoofStyle 117440517;
BA_ "FlexKomSigLaenge" SG_ 519 RoofStyle 64;
BA_ "FlexKomSigName" SG_ 519 RoofStyle "VehCommonId";
BA_ "FlexKomSigStartPos" SG_ 519 RoofStyle 7;
BA_ "FlexKomSigStartValue" SG_ 519 RoofStyle "FFFF7F7FFF00EFFFh";
BA_ "GenSigCycleTime" SG_ 519 RoofStyle 300;
BA_ "GenSigSNA" SG_ 519 RoofStyle "7";
BA_ "GenSigSendType" SG_ 519 RoofStyle 7;
BA_ "GenSigStartValue" SG_ 519 RoofStyle 7;
BA_ "FlexKomComment" SG_ 519 CRC_CVI "Common vehicle identification";
BA_ "FlexKomIsMotorola" SG_ 519 CRC_CVI 1;
BA_ "FlexKomSID" SG_ 519 CRC_CVI 117440517;
BA_ "FlexKomSigLaenge" SG_ 519 CRC_CVI 64;
BA_ "FlexKomSigName" SG_ 519 CRC_CVI "VehCommonId";
BA_ "FlexKomSigStartPos" SG_ 519 CRC_CVI 7;
BA_ "FlexKomSigStartValue" SG_ 519 CRC_CVI "FFFF7F7FFF00EFFFh";
BA_ "GenSigCycleTime" SG_ 519 CRC_CVI 300;
BA_ "GenSigSendType" SG_ 519 CRC_CVI 7;
BA_ "GenSigStartValue" SG_ 519 CRC_CVI 255;
BA_ "GenSigTimeout_ESP_ABR" SG_ 519 CRC_CVI 4650;
BA_ "GenSigTimeout_MPC" SG_ 519 CRC_CVI 3150;
BA_ "GenSigTimeout_RBTM_FL" SG_ 519 CRC_CVI 3150;
BA_ "GenSigTimeout_RBTM_FR" SG_ 519 CRC_CVI 3150;
BA_ "FieldType" SG_ 1465 DAS_alertID "DAS_alertID";
BA_ "GenSigStartValue" SG_ 1465 DAS_sw018_maxThreshold 50;
BA_ "GenSigStartValue" SG_ 1465 DAS_sw019_numFreeBytes 191;
BA_ "FieldType" SG_ 1465 DAS_sw024_currentVehicleApp "DAS_vehicleApp";
BA_ "GenSigSNA" SG_ 1465 DAS_sw042_health_state "7";
BA_ "GenSigSNA" SG_ 1465 DAS_sw042_epas_error_code "15";
BA_ "FieldType" SG_ 1465 DAS_sw060_collisionWarningSource "FCM_collisionWarningSource";
BA_ "GenSigStartValue" SG_ 1465 DAS_sw062_HorizontalMisalignment 32767.3084205;
BA_ "GenSigStartValue" SG_ 1465 DAS_sw062_VerticalMisalignment 511.497323164;
BA_ "GenSigSNA" SG_ 1465 DAS_sw069_diAPState "15";
BA_ "GenSigSNA" SG_ 1465 DAS_sw070_currTireFitment "3";
BA_ "GenSigSNA" SG_ 1465 DAS_sw070_lastTireFitment "3";
BA_ "GenSigSNA" SG_ 1465 DAS_sw070_diGear "7";
BA_ "GenSigSNA" SG_ 1465 DAS_sw071_selfParkType "7";
BA_ "GenSigSNA" SG_ 1465 DAS_sw071_roadClass "0";
BA_ "FieldType" SG_ 1465 DAS_sw073_escalateLDWreason "LC_escalateLDWreason";
BA_ "GenSigSNA" SG_ 1465 DAS_sw074_roadClass "0";
BA_ "GenSigSNA" SG_ 1465 DAS_sw194_leadDx "255";
BA_ "GenSigSNA" SG_ 1465 DAS_sw194_leadVx "31";
BA_ "GenSigSNA" SG_ 1465 DAS_sw194_leadAx "31";
BA_ "GenSigSNA" SG_ 1465 DAS_sw194_reasonForHold "15";
BA_ "GenSigSNA" SG_ 1465 DAS_sw199_abortCodePARK "31";
BA_ "GenSigSNA" SG_ 1465 DAS_sw203_roadClass "0";
BA_ "GenSigSNA" SG_ 1465 DAS_sw203_controlType "15";
BA_ "GenSigSNA" SG_ 1465 DAS_sw204_frLeftMiddle "255";
BA_ "GenSigSNA" SG_ 1465 DAS_sw204_frRightMiddle "255";
BA_ "GenSigSNA" SG_ 1465 DAS_sw204_frRight "255";
BA_ "GenSigSNA" SG_ 1465 DAS_sw204_frLeft "255";
BA_ "GenSigSNA" SG_ 1465 DAS_sw204_frMiddle "255";
BA_ "GenSigSNA" SG_ 1465 DAS_sw205_rrRightMiddle "255";
BA_ "GenSigSNA" SG_ 1465 DAS_sw205_rrLeftMiddle "255";
BA_ "GenSigSNA" SG_ 1465 DAS_sw205_rrRight "255";
BA_ "GenSigSNA" SG_ 1465 DAS_sw205_rrLeft "255";
BA_ "GenSigSNA" SG_ 1465 DAS_sw205_rrMiddle "255";
BA_ "GenSigSNA" SG_ 1465 DAS_sw205_oocDistance "255";
BA_ "FieldType" SG_ 1465 DAS_sw207_lcUnavailableReason "LC_unavailableReason";
BA_ "GenSigSNA" SG_ 1465 DAS_sw218_handsOnState "15";
BA_ "FieldType" SG_ 583 DAS_roadEstimator "DAS_roadEstimator";
BA_ "FieldType" SG_ 583 DAS_arbiterBehavior "DAS_arbiterBehavior";
BA_ "LogSignal" SG_ 583 DAS_arbiterBehavior "onChange";
BA_ "FieldType" SG_ 583 DAS_mapAvailability "DAS_mapAvailability";
BA_ "FieldType" SG_ 583 DAS_controllerRef "DAS_controllerRef";
BA_ "FieldType" SG_ 583 DAS_alcInternalState "DAS_alcInternalState";
BA_ "LogSignal" SG_ 583 DAS_alcInternalState "onChange";
BA_ "FieldType" SG_ 583 DAS_behaviorReport "DAS_behaviorReport";
BA_ "LogSignal" SG_ 583 DAS_behaviorReport "onChange";
BA_ "FieldType" SG_ 583 DAS_controllerHealth "DAS_controllerHealth";
BA_ "FieldType" SG_ 583 DAS_autopilotAbortReason "DAS_autopilotAbortReason";
BA_ "FieldType" SG_ 583 DAS_rqstedBehaviorStatus "DAS_rqstedBehaviorStatus";
BA_ "LogSignal" SG_ 583 DAS_rqstedBehaviorStatus "onChange";
BA_ "FieldType" SG_ 583 DAS_forkState "DAS_forkState";
BA_ "LogSignal" SG_ 583 DAS_forkState "onChange";
BA_ "FieldType" SG_ 583 DAS_laneChangeState "DAS_laneChangeState";
BA_ "LogSignal" SG_ 583 DAS_laneChangeState "onChange";
BA_ "FieldType" SG_ 583 DAS_lastWatchdogCode "DAS_lastWatchdogCode";
BA_ "LogSignal" SG_ 583 DAS_lastWatchdogCode "onChange";
BA_ "FieldType" SG_ 1001 DAS_headlightRequest "DAS_headlightRequest";
BA_ "LogSignal" SG_ 1001 DAS_headlightRequest "onChange";
BA_ "FieldType" SG_ 1001 DAS_hazardLightRequest "DAS_hazardLightRequest";
BA_ "GenSigSNA" SG_ 1001 DAS_hazardLightRequest "3";
BA_ "FieldType" SG_ 1001 DAS_wiperSpeed "DAS_wiperSpeed";
BA_ "LogSignal" SG_ 1001 DAS_wiperSpeed "onChange";
BA_ "FieldType" SG_ 1001 DAS_turnIndicatorRequest "DAS_turnIndicatorRequest";
BA_ "FieldType" SG_ 1001 DAS_highLowBeamDecision "DAS_highLowBeamDecision";
BA_ "GenSigSNA" SG_ 1001 DAS_highLowBeamDecision "3";
BA_ "LogSignal" SG_ 1001 DAS_highLowBeamDecision "onChange";
BA_ "FieldType" SG_ 1001 DAS_highLowBeamOffReason "DAS_highLowBeamOffReason";
BA_ "GenSigSNA" SG_ 1001 DAS_highLowBeamOffReason "5";
BA_ "LogSignal" SG_ 1001 DAS_highLowBeamOffReason "onChange";
BA_ "LogSignal" SG_ 1001 DAS_emergencyChimeRequest "onChange";
BA_ "FieldType" SG_ 1001 DAS_turnIndicatorRequestReason "DAS_turnIndicatorRequestReason";
BA_ "LogSignal" SG_ 1001 DAS_turnIndicatorRequestReason "onChange";
BA_ "LogSignal" SG_ 1001 DAS_ahlbOverride "onChange";
VAL_ 643 DrRLtch_FL_Stat 3 "SNA" 2 "OPN" 1 "CLS" 0 "NDEF0" ;
VAL_ 643 DrRLtch_FR_Stat 3 "SNA" 2 "OPN" 1 "CLS" 0 "NDEF0" ;
VAL_ 643 DrRLtch_RL_Stat 3 "SNA" 2 "OPN" 1 "CLS" 0 "NDEF0" ;
VAL_ 643 DrRLtch_RR_Stat 3 "SNA" 2 "OPN" 1 "CLS" 0 "NDEF0" ;
VAL_ 643 DL_RLtch_Stat 3 "SNA" 2 "OPN" 1 "CLS" 0 "NDEF0" ;
VAL_ 643 EngHd_Stat 3 "SNA" 2 "OPN" 1 "CLS" 0 "NDEF0" ;
VAL_ 643 LgtSens_Night 1 "NIGHT" 0 "DAY" ;
VAL_ 643 Trlr_Stat 3 "SNA" 2 "NDEF2" 1 "OK" 0 "NONE" ;
VAL_ 643 MPkBrk_Stat 1 "ENGG" 0 "RELS" ;
VAL_ 643 RevGr_Engg 3 "SNA" 2 "NDEF2" 1 "ENGG" 0 "DISENGG" ;
VAL_ 643 AirTemp_Insd 255 "SNA" ;
VAL_ 643 Bckl_Sw_RL_Stat_SAM_R 3 "SNA" 2 "FLT" 1 "NOT" 0 "OK" ;
VAL_ 643 Bckl_Sw_RR_Stat_SAM_R 3 "SNA" 2 "FLT" 1 "NOT" 0 "OK" ;
VAL_ 643 Bckl_Sw_RM_Stat_SAM_R 3 "SNA" 2 "FLT" 1 "NOT" 0 "OK" ;
VAL_ 643 StW_Cond_Stat 3 "BLINK" 2 "ON" 1 "NDEF1" 0 "OFF" ;
VAL_ 643 AirTemp_Outsd 255 "SNA" 254 "INIT" ;
VAL_ 15 CGW_Rout_Stat 3 "NDEF3" 2 "NDEF2" 1 "DSABL_TO_MON" 0 "ACTIVE" ;
VAL_ 15 BusFlt_PrmntActv 1 "BUS_FLT_KPT_AWAKE" 0 "NO_FLT" ;
VAL_ 556 CHG_mainState 6 "CHG_MAIN_STATE_FC_ENABLE" 5 "CHG_MAIN_STATE_FC_STARTUP" 4 "CHG_MAIN_STATE_ENABLE" 3 "CHG_MAIN_STATE_PRECHARGE" 2 "CHG_MAIN_STATE_FAULT" 1 "CHG_MAIN_STATE_CLEAR_FAULT" 0 "CHG_MAIN_STATE_STANDBY" ;
VAL_ 556 CHG_proximity 3 "CHG_PROXIMITY_LATCHED" 2 "CHG_PROXIMITY_UNLATCHED" 1 "CHG_PROXIMITY_DISCONNECTED" 0 "CHG_PROXIMITY_SNA" ;
VAL_ 556 CHG_pilot 7 "CHG_PILOT_SNA" 6 "CHG_PILOT_UNUSED_6" 5 "CHG_PILOT_INVALID" 4 "CHG_PILOT_IDLE" 3 "CHG_PILOT_FAST_CHARGE" 2 "CHG_PILOT_LINE_CHARGE" 1 "CHG_PILOT_FAULTED" 0 "CHG_PILOT_NONE" ;
VAL_ 556 CHG_cableType 4 "CHG_CABLE_TYPE_SNA" 3 "CHG_CABLE_TYPE_GB_DC" 2 "CHG_CABLE_TYPE_GB_AC" 1 "CHG_CABLE_TYPE_SAE" 0 "CHG_CABLE_TYPE_IEC" ;
VAL_ 556 CHG_cableState 2 "CABLE_STATE_UNKNOWN_SNA" 1 "CABLE_STATE_CONNECTED" 0 "CABLE_STATE_NOT_CONNECTED" ;
VAL_ 556 CHG_phaseConfig 4 "PHASE_CONFIG_SNA" 3 "TWO_PHASE_DELTA_THREE_CHGPH" 2 "TWO_PHASE_DELTA_TWO_CHGPH" 1 "THREE_PHASE" 0 "SINGLE_PHASE" ;
VAL_ 556 CHG_subState 50 "CHG_STATE_50" 49 "CHG_STATE_49" 48 "CHG_STATE_48" 47 "CHG_STATE_47" 46 "CHG_STATE_46" 45 "CHG_STATE_45" 44 "CHG_STATE_44" 43 "CHG_STATE_WAIT_CHGPH_SHUTDOWN" 42 "CHG_STATE_DIGITAL_COMMS" 41 "CHG_STATE_WAIT_DIGITAL_COMMS" 40 "CHG_STATE_ACCEPT_DIGITAL_COMMS" 39 "CHG_STATE_WAIT_ACCEPT_DIGITAL_COMMS" 38 "CHG_STATE_SET_PRECHARGE_TARGET" 37 "CHG_STATE_WAIT_NUMPHASES" 36 "CHG_STATE_FORCE_SHUTDOWN" 35 "CHG_STATE_RETRY" 34 "CHG_STATE_DELAY_TO_IDLE" 33 "CHG_STATE_CHECK_USER_ALERTS" 32 "CHG_STATE_OPEN_RELAYS" 31 "CHG_STATE_CURRENT_OFF" 30 "CHG_STATE_SOFT_SHUTDOWN" 29 "CHG_STATE_CLRFLT_DONE" 28 "CHG_STATE_CLRFLT_DRV_STABLE" 27 "CHG_STATE_CLRFLT_GATE_DRV_ON" 26 "CHG_STATE_CLRFLT_GATE_DRV_OFF_2" 25 "CHG_STATE_CLRFLT_GATE_DRV_OFF_1" 24 "CHG_STATE_CLRFLT" 23 "CHG_STATE_FAULTED" 22 "CHG_STATE_SOFTWARE_FAULT" 21 "CHG_STATE_CHARGING" 20 "CHG_STATE_RAMP_CURRENT" 19 "CHG_STATE_PRECHARGE_OFF" 18 "CHG_STATE_ENABLE_PID" 17 "CHG_STATE_ANTISPARK_CLOSED" 16 "CHG_STATE_ANTISPARK_ON" 15 "CHG_STATE_PWM_ON" 14 "CHG_STATE_TRANSITION_TO_ENABLE" 13 "CHG_STATE_CHECK_PWM_ENABLED" 12 "CHG_STATE_ARM_PWM" 11 "CHG_STATE_WAIT_ARM_PWM" 10 "CHG_STATE_PRECHARGE_FINAL_TEST" 9 "CHG_STATE_PRECHARGE_WAIT_FINAL" 8 "CHG_STATE_PRECHARGE_INITIAL_TEST" 7 "CHG_STATE_PRECHARGE" 6 "CHG_STATE_FAILED_TO_START" 5 "CHG_STATE_HAVE_VLINE" 4 "CHG_STATE_ACCEPT" 3 "CHG_STATE_WAIT_ACCEPT" 2 "CHG_STATE_TRANSITION_TO_PRECHARGE" 1 "CHG_STATE_IDLE" 0 "CHG_STATE_STARTUP" ;
VAL_ 556 CHG_inputRelayState 3 "CHG_INPUT_RELAY_SNA" 2 "CHG_INPUT_RELAY_OPEN" 1 "CHG_INPUT_RELAY_L1_CLOSED" 0 "CHG_INPUT_RELAY_L2_CLOSED" ;
VAL_ 21 SwIllLvl 255 "SNA" ;
VAL_ 21 DispBrt_IC 255 "SNA" 254 "DISP_LGT_ON" ;
VAL_ 519 Group 15 "SNA" 3 "MMC" 2 "CG" 1 "SMART" 0 "MB" ;
VAL_ 519 Country 15 "SNA" 8 "CHN" 7 "UK" 6 "GULF" 5 "AUS" 4 "SWI" 3 "JAP" 2 "CAN" 1 "USA" 0 "ROW" ;
VAL_ 519 VehLine 63 "SNA" 36 "BR156" 35 "BR117" 34 "BR197" 33 "BR246" 32 "BR218" 22 "BR216" 19 "BR164" 17 "BR251" 9 "BR207" 8 "BR166" 7 "BR176" 5 "BR172" 3 "BR204" 2 "BR212" 1 "BR231" 0 "BR221" ;
VAL_ 519 Guard 3 "SNA" 2 "B6" 1 "B4" 0 "NO" ;
VAL_ 519 VehLinePack 3 "PACKX" 2 "PACK2" 1 "PACK1" 0 "PACK0" ;
VAL_ 519 VehLineYear 31 "START" 30 "NDEF30" ;
VAL_ 519 BodyStyle 31 "SNA" 13 "X" 12 "T" 11 "GV" 10 "G" 9 "F" 8 "VF" 7 "VV" 6 "CL" 5 "R" 4 "A" 3 "S" 2 "C" 1 "V" 0 "W" ;
VAL_ 519 StStyle 3 "SNA" 2 "RHD" 1 "LHD" 0 "NDEF0" ;
VAL_ 519 EngStyle 255 "SNA" 141 "OM645DE18LA100" 140 "OM645DE18LA80" 139 "OM642DE30LA185" 138 "OM651DE22LA80" 137 "OM651DE22LA100" 136 "OM651DE22LA120" 135 "OM651DE22LA150" 134 "OM646EVODE22LA85" 133 "OM646EVODE22LA100" 132 "OM646EVODE22LA125" 131 "OM642DE30LA140" 130 "OM629DE40LA" 129 "OM642DE30LA160" 126 "AMGM156E63" 125 "AMGM157E60LA" 124 "AMGM275E60LA" 123 "AMGM156E63HP" 122 "AMGM278E55DEHLA" 121 "AMGM278E55DE" 120 "AMGM159E63" 26 "M276E30DEH" 25 "M276E35DEH" 24 "M270DE20LA150" 23 "M270DE16LA115" 22 "M270DE16" 21 "M271E18LAEVO135" 20 "M271E18LAEVO150" 19 "M271E18LAEVO115" 18 "M278E46DEHLA" 17 "M276E30DES" 16 "M276E35DES" 15 "M276E35DEHLA" 14 "M272E35_224" 13 "M271E18ML115ATT" 12 "M271E18ML135ATT" 9 "M272E35DE" 5 "M272E25" 4 "M272E30" 3 "M272E35" 2 "M273E46" 1 "M273E55" 0 "M275E55" ;
VAL_ 519 HVACStyle 3 "FOUR_ZONE" 2 "THREE_ZONE" 1 "TWO_ZONE" 0 "ONE_ZONE" ;
VAL_ 519 VehOPTPack 3 "SNA" 2 "AVANTGARDE" 1 "ELEGANCE" 0 "CLASSIC" ;
VAL_ 519 RoofStyle 7 "SNA" 4 "EXTRUN_TSSR_CLS" 3 "TSSR_RCLS" 2 "EXTRUN_TSSR" 1 "TSSR" 0 "NORM" ;
VAL_ 1465 DAS_alertID 233 "DAS_w233_laneChangeCancelled" 232 "DAS_w232_laneChangeRequested" 231 "DAS_w231_idfEvent" 230 "DAS_w230_alcUltrasoundBlocked" 229 "DAS_w229_alcUltrasoundDamaged" 227 "DAS_w227_virtualWallBlocked" 226 "DAS_w226_lcCamCalNeededSpeedLmt" 225 "DAS_w225_lcDegradedVisSpeedLmt" 224 "DAS_w224_accCameraCalibration" 223 "DAS_w223_accObjectInPath" 222 "DAS_w222_accCameraBlind" 221 "DAS_w221_accRadarBlind" 220 "DAS_w220_lcTempUnavailableRoad" 219 "DAS_w219_lcTempUnavailableSpeed" 218 "DAS_w218_lcSpeedExceededLimit" 217 "DAS_w217_lcUnavailableSpeeding" 216 "DAS_w216_driverOverriding" 215 "DAS_w215_contDriverNotIntracting" 214 "DAS_w214_driverNotIntracting" 213 "DAS_w213_autosteerStruckOut" 212 "DAS_w212_lcUnavailableStrikeOut" 211 "DAS_w211_accNoSeatBelt" 210 "DAS_w210_camObstrcted" 209 "DAS_w209_autoSummonRequest" 208 "DAS_w208_rackDetected" 207 "DAS_w207_autosteerUnavailable" 206 "DAS_w206_autosteerNotEnabled" 205 "DAS_w205_apcFinalRear" 204 "DAS_w204_apcFinalFront" 203 "DAS_w203_apcActivation" 202 "DAS_w202_scwNoisyEnvironment" 201 "DAS_w201_lcAborting" 200 "DAS_w200_lcSlowdown" 199 "DAS_w199_apcAbort" 198 "DAS_w198_tsrUnavailable" 197 "DAS_w197_redLightWarning" 196 "DAS_w196_stopSignWarning" 195 "DAS_w195_scwUnavailable" 194 "DAS_w194_accDriverResumeRqrd" 193 "DAS_w193_camWindshieldUnclean" 106 "DAS_w106_torsionBarCalibrated" 103 "DAS_w103_robExperimentalAEB" 86 "DAS_w086_robCollision" 85 "DAS_w085_pmmSteering" 84 "DAS_w084_pmmIPSO" 83 "DAS_w083_inPathRADObject" 82 "DAS_w082_inPathFSviolation" 81 "DAS_w081_pmmActiveBraking" 80 "DAS_w080_accFailedActivation" 79 "DAS_w079_edrAvailable" 78 "DAS_w078_pmmActive2" 77 "DAS_w077_pmmActive" 76 "DAS_w076_mobilEyeSetC" 75 "DAS_w075_scMia" 74 "DAS_w074_inPathStationaryObst" 73 "DAS_w073_issueEscalatedLDW" 72 "DAS_w072_selfparkComplete" 71 "DAS_w071_selfparkStarted" 70 "DAS_w070_apcIncompleteCal" 69 "DAS_w069_apcSpaceMasked" 68 "DAS_w068_vlInconsistency" 67 "DAS_w067_steeringAlignment" 66 "DAS_w066_deserializerLockLost" 65 "DAS_w065_deserializerOvercurrent" 64 "DAS_w064_epasMia" 63 "DAS_w063_parkVersionMismatch" 62 "DAS_w062_radcAlignment" 61 "DAS_w061_airSuspensionMia" 60 "DAS_w060_fcw_event" 59 "DAS_w059_parkMia" 58 "DAS_w058_epbMia" 57 "DAS_w057_mcuMia" 56 "DAS_w056_diMia" 55 "DAS_w055_radcVersionMismatch" 54 "DAS_w054_camAutofix" 53 "DAS_w053_radcCommIssue" 52 "DAS_w052_radcSensorIssue" 51 "DAS_w051_radcEcuIssue" 50 "DAS_w050_aeb_event" 49 "DAS_w049_eyeqVersionMismatch" 48 "DAS_w048_DAS_Features_Disabled" 47 "DAS_w047_edrEvent" 46 "DAS_w046_eepromRecordAbsent" 45 "DAS_w045_radMia" 44 "DAS_w044_appMobileyeFailure" 43 "DAS_w043_camLongRunTime" 42 "DAS_w042_autopilotAborting" 41 "DAS_w041_autopilotRateSaturated" 40 "DAS_w040_autopilotAngleSaturated" 39 "DAS_w039_sdm_rcm_Mia" 38 "DAS_w038_camFailure" 37 "DAS_w037_camTacIssue" 36 "DAS_w036_bdyMia" 35 "DAS_w035_espMia" 34 "DAS_w034_sccmMia" 33 "DAS_w033_gtwMia" 32 "DAS_w032_canTxError" 31 "DAS_w031_canRxError" 30 "DAS_w030_Heater_Issue" 29 "DAS_w029_spi_tx_error" 28 "DAS_w028_spi_rx_error" 27 "DAS_w027_ECU_Reset_Fault" 26 "DAS_w026_ECU_timingIssue" 25 "DAS_w025_LC_Steering_Override" 24 "DAS_w024_ECU_Watchdog_Reset" 23 "DAS_w023_ECU_Cam_Statemismatch" 22 "DAS_w022_ECU_EEPROM_Failure" 21 "DAS_w021_ECU_Temperature_Issue" 20 "DAS_w020_ECU_checkstopError" 19 "DAS_w019_ECU_Stack_Overflow" 18 "DAS_w018_ECU_Power_Issue" 17 "DAS_w017_Cam_Msg_MIA" 16 "DAS_w016_aeb_e_event" 15 "DAS_w015_Camera_Failsafes" 14 "DAS_w014_swAssert" 13 "DAS_w013_Cam_Watchdog" 12 "DAS_w012_Cam_BootFailure" 11 "DAS_w011_scaEvent" 10 "DAS_w010_radcCalibIssue" 9 "DAS_w009_aebFault" 8 "DAS_w008_parkDisabled" 7 "DAS_w007_ahlbDisabled" 6 "DAS_w006_aebCancelled" 5 "DAS_w005_fcwCancelled" 4 "DAS_w004_accDisabled" 3 "DAS_w003_isaDisabled" 2 "DAS_w002_ldwDisabled" 0 "DAS_w000_reserved" ;
VAL_ 1465 DAS_sw004_accState 11 "CANCEL_OUT_OF_CALIBRATION" 10 "CANCEL_GENERIC_SILENT" 9 "CANCEL_PATH_NOT_CLEAR" 8 "FAULT" 7 "CANCEL_RADAR" 6 "CANCEL_CAMERA" 5 "CANCEL_GENERIC" 4 "READY_FOR_RESUME" 3 "HOLD" 2 "STANDSTILL" 1 "ACTIVE" 0 "IDLE" ;
VAL_ 1465 DAS_sw004_appMobileyeStatus 24 "MOBILEYE_STATUS_UNDEFINED" 23 "MOBILEYE_STATUS_TEARDOWN_FLASH_ACCESS_MODE" 22 "MOBILEYE_STATUS_FLASH_READ_MODE" 21 "MOBILEYE_STATUS_SETUP_FLASH_ACCESS_MODE" 20 "MOBILEYE_STATUS_RUNNING_SPTAC_MODE" 19 "MOBILEYE_STATUS_SPTAC_INIT_SENT" 18 "MOBILEYE_STATUS_WAITING_FOR_SPTAC_INIT" 17 "MOBILEYE_STATUS_BURN_EDR_MODE" 16 "MOBILEYE_STATUS_SPC_INIT_SENT" 15 "MOBILEYE_STATUS_WAITING_FOR_SPC_INIT" 14 "MOBILEYE_STATUS_ERROR" 13 "MOBILEYE_STATUS_LATCHING_FAILURE" 12 "MOBILEYE_STATUS_UPDATING" 11 "MOBILEYE_STATUS_RUNNING_DV_MODE" 10 "MOBILEYE_STATUS_WAITING_FOR_DV" 9 "MOBILEYE_STATUS_RUNNING_TAC_MODE" 8 "MOBILEYE_STATUS_RUNNING_SPC_MODE" 7 "MOBILEYE_STATUS_RUNNING_VISION_MODE" 6 "MOBILEYE_STATUS_TAC_INIT_SENT" 5 "MOBILEYE_STATUS_WAITING_FOR_TAC_INIT" 4 "MOBILEYE_STATUS_VISION_INIT_SENT" 3 "MOBILEYE_STATUS_WAITING_FOR_VISION_INIT" 2 "MOBILEYE_STATUS_WAITING_FOR_BOOT" 1 "MOBILEYE_STATUS_POWER_OFF" 0 "MOBILEYE_STATUS_POWER_CYCLE" ;
VAL_ 1465 DAS_sw006_timeOfDay 2 "TIME_DUSK" 1 "TIME_NIGHT" 0 "TIME_DAY" ;
VAL_ 1465 DAS_sw010_a04calibNotDone 1 "True" 0 "False" ;
VAL_ 1465 DAS_sw010_a05calibReqd 1 "True" 0 "False" ;
VAL_ 1465 DAS_sw010_a06calibNotOK 1 "True" 0 "False" ;
VAL_ 1465 DAS_sw010_a08PlantMode 1 "True" 0 "False" ;
VAL_ 1465 DAS_sw011_scaState 4 "FAULT" 3 "AVOIDANCE" 2 "AVAILABLE" 1 "UNAVAILABLE" 0 "DISABLED" ;
VAL_ 1465 DAS_sw012_bootDDRTempStatus 3 "SDRAM high temperature" 2 "temperature grater than 85 C" 1 "temperature less or equal to 85 C" 0 "SDRAM low temperatue" ;
VAL_ 1465 DAS_sw012_mespDDRTempStatus 7 "Temperature error" 3 "Temperature above 85" 2 "Termperature above spec" 1 "Temperature below spec" 0 "Temperature ok" ;
VAL_ 1465 DAS_sw013_stateBeforeWatchdog 24 "MOBILEYE_STATUS_UNDEFINED" 23 "MOBILEYE_STATUS_TEARDOWN_FLASH_ACCESS_MODE" 22 "MOBILEYE_STATUS_FLASH_READ_MODE" 21 "MOBILEYE_STATUS_SETUP_FLASH_ACCESS_MODE" 20 "MOBILEYE_STATUS_RUNNING_SPTAC_MODE" 19 "MOBILEYE_STATUS_SPTAC_INIT_SENT" 18 "MOBILEYE_STATUS_WAITING_FOR_SPTAC_INIT" 17 "MOBILEYE_STATUS_BURN_EDR_MODE" 16 "MOBILEYE_STATUS_SPC_INIT_SENT" 15 "MOBILEYE_STATUS_WAITING_FOR_SPC_INIT" 14 "MOBILEYE_STATUS_ERROR" 13 "MOBILEYE_STATUS_LATCHING_FAILURE" 12 "MOBILEYE_STATUS_UPDATING" 11 "MOBILEYE_STATUS_RUNNING_DV_MODE" 10 "MOBILEYE_STATUS_WAITING_FOR_DV" 9 "MOBILEYE_STATUS_RUNNING_TAC_MODE" 8 "MOBILEYE_STATUS_RUNNING_SPC_MODE" 7 "MOBILEYE_STATUS_RUNNING_VISION_MODE" 6 "MOBILEYE_STATUS_TAC_INIT_SENT" 5 "MOBILEYE_STATUS_WAITING_FOR_TAC_INIT" 4 "MOBILEYE_STATUS_VISION_INIT_SENT" 3 "MOBILEYE_STATUS_WAITING_FOR_VISION_INIT" 2 "MOBILEYE_STATUS_WAITING_FOR_BOOT" 1 "MOBILEYE_STATUS_POWER_OFF" 0 "MOBILEYE_STATUS_POWER_CYCLE" ;
VAL_ 1465 DAS_sw014_fileNameHash 32617 "HW_GPIO_PAD.c" 32602 "UDS_FlowControl.c" 32601 "ACC_compute.c" 32576 "app_CAN.c" 32563 "IO_RGM.c" 32315 "IQmath.c" 32314 "HW_CGM.c" 32299 "HW_RGM.c" 32074 "trajectory_planner_main.c" 32054 "HW_ADC.c" 32006 "NVM_Manager_component_specific.c" 31862 "IO_queue_component_specific.c" 31831 "fixquat.c" 31790 "IO_ADC.c" 31784 "UDS_TP.c" 31764 "lib_UDS_EEPROM.c" 31604 "HW_GPIO_pad_definitions.c" 31348 "app_mobileye_version_matrix.c" 31343 "HW_ECSM.c" 31291 "UDS_RC.c" 31247 "fixvector2d.c" 31246 "fixvector3d.c" 31032 "IO_radar_alert.c" 31009 "IO_CAN.c" 30055 "UDS_TRD.c" 29810 "app_tsr.c" 29797 "IO_watchdog.c" 29787 "SCA_monitor.c" 29561 "UDS_ctrlDTC.c" 29531 "IO_Mobileye.c" 29280 "AlertManagerCfg.c" 29243 "Interpolate_IQ15.c" 29033 "app_ahb.c" 29024 "UDS_readDTC.c" 28726 "HW_LIN.c" 28722 "HW_SIU.c" 28720 "HW_PIT.c" 28519 "IO_PWMInput.c" 28465 "IO_PWM.c" 28459 "IO_SWT.c" 28211 "HW_SWT.c" 28197 "HW_DAS_SIU.c" 27947 "HW_OTP.c" 27946 "HW_STM.c" 27914 "util_queue.c" 27750 "IO_mutex_component_specific.c" 27699 "IO_OTP.c" 27516 "IO_CAN_data.c" 27451 "UDS_CC.c" 27444 "HW_CRC.c" 27262 "HW_WKPU.c" 27233 "app_vehicle.c" 27179 "HW_MSR.c" 26995 "xcp_par.c" 26981 "app_ldw.c" 26926 "HW_SPI.c" 26232 "ACC_speed_limit.c" 25952 "das_app.c" 25866 "RTOS_interrupt.c" 25713 "ACC_fleet_speed.c" 25691 "ACC_monitor.c" 25190 "UDS_DSC.c" 25164 "road_furniture_main.c" 25154 "app_ECU.c" 24957 "CSA.c" 24907 "lib_HSD.c" 24678 "IO_UART.c" 24636 "HW_RGM_DAS.c" 24145 "fix16_exp.c" 23589 "app_mobileye_country_codes.c" 22573 "utils_math.c" 22548 "IO_Vehicle.c" 22364 "util_codeDescriptor_ghs.c" 22082 "NVM_Manager.c" 21614 "LC_calculate_health.c" 21599 "watchdog_manager_component_specific.c" 21295 "app_heater.c" 21266 "IO_Environment.c" 21063 "lib_mobileye_mesp_utils.c" 20331 "util_ringBuffer.c" 20237 "UDS_SecurityAccess.c" 19731 "LC_follow_path.c" 19318 "fix16.c" 19037 "fix16_str.c" 18253 "Interpolate.c" 17980 "HW_interrupt_componentSpecific.c" 17972 "UDS_SendSM.c" 17933 "IO_quadDecoder.c" 17433 "util_crc_j1850.c" 17419 "UDS_RQ_ULDL_common.c" 17259 "util_codeDescriptor.c" 17168 "ACC_filter.c" 17016 "lib_mobileye_mesp_basic_service.c" 16910 "ACC_output.c" 16194 "UDS_SIDs.c" 16151 "IO_ECU_component_specific.c" 15973 "UDS_RQDL.c" 15965 "app_mobileye_EDR.c" 15928 "UDS_Processor.c" 15733 "UDS_WDBI.c" 15732 "UDS_WMBA.c" 15721 "profiler.c" 15678 "task_mobileye.c" 15616 "lib_mobileye_mesp.c" 15378 "HW_CAN_component_specific.c" 15375 "lib_NVRAM.c" 15211 "HW_EMIOS.c" 15197 "app_mobileye_TAC.c" 15181 "app_watchdog.c" 15121 "lib_mobileye_mesp_calibration_service.c" 14931 "lib_mobileye.c" 14684 "lib_math.c" 14453 "UDS_RDBI.c" 14452 "UDS_RMBA.c" 14448 "SCA_main.c" 14446 "UDS_ECUReset.c" 14425 "IO_reset.c" 14206 "PMM_main.c" 14185 "rijndael.c" 14180 "task_CAN.c" 14118 "util_counters.c" 13912 "utils_DAS_assert.c" 13572 "virtual_wall_main.c" 13383 "IO_timer.c" 13130 "app_vehicle_driving_side.c" 12911 "task_UDS.c" 12645 "IO_Failsafes.c" 12596 "HW_ME.c" 12339 "LC_hands_on_detection.c" 12133 "UDS_RQUL.c" 12091 "IO_EEPROM.c" 11884 "UDS_RQTE.c" 11877 "world_model_main.c" 11811 "HW_EEPROM.c" 11615 "lib_mobileye_mesp_frame_data_service.c" 11568 "RTOS_time.c" 11525 "HW_SPI_component_specific.c" 11277 "virtual_lane_main.c" 11132 "CalcFilt.c" 11089 "lateral_control_angle_tables.c" 10860 "main.c" 10840 "LC_telemetry.c" 10530 "ACC_target_assessment.c" 10524 "app_system_health.c" 10352 "ACC_main.c" 10339 "APC_main.c" 10317 "IO_mutex.c" 10007 "IO_digOut.c" 10004 "lib_mobileye_mesp_edr_service.c" 9784 "UDS_IOCBI.c" 9750 "HW_LIN_processor_specific.c" 9729 "IO_board_test.c" 9546 "app_mobileye.c" 9257 "FCM_threat_assessment.c" 9082 "lib_mobileye_mesp_camera_service.c" 9056 "fixarray.c" 8801 "UDS_ECU_shim.c" 8716 "fract32.c" 8560 "FCM_main.c" 8537 "IO_MobileyeFlash.c" 8493 "UDS_ECU_Hooks.c" 8310 "util_bitManipulation.c" 8286 "IO_MobileyeFlashTestStub.c" 8274 "UDS_MasterSM.c" 8000 "AlertMap.c" 7969 "fixkalman.c" 7477 "TSR_telemetry.c" 7434 "FCM_state_machine.c" 7252 "HW_CAN_processorSpecific.c" 7223 "_xcp_appl.c" 7025 "fix16_trig.c" 6987 "AlertManager.c" 6941 "utils_ttc.c" 6209 "IO_digIn.c" 5924 "tasks.c" 5745 "task_vehicle.c" 5687 "fixmatrix.c" 5677 "IO_Heater.c" 5479 "UDS_ECU_Services.c" 5392 "UDS_ReceiveSM.c" 5158 "LC_health_monitor.c" 5145 "APC_state_machine.c" 5130 "ACC_state_machine.c" 4970 "Selfpark.c" 4950 "AlertManagerHeaderConfig.c" 4656 "SCA_angle.c" 4212 "watchdog_manager.c" 3931 "lib_IQ28QorivvaMathLib.c" 3666 "XcpBasic.c" 3145 "util_CRC32.c" 3113 "ACC_input.c" 2934 "ACC_target_selection.c" 2878 "HW_I2C.c" 2640 "app_mobileye_spi.c" 2632 "IO_ADC_componentSpecific.c" 2598 "IO_I2C.c" 2162 "UDS_clearDTC.c" 1889 "fix16_sqrt.c" 1612 "uint32.c" 1564 "IO_CAN_alerts.c" 1365 "LC_state_machine.c" 1151 "IO_EEPROM_component_specific.c" 1034 "SCA_state_machine.c" 605 "HW_EEPROM_common.c" 297 "CanReceiver_Generated.c" 48 "IO_edgeDetect.c" ;
VAL_ 1465 DAS_sw015_RadarLowVisibility 3 "True_High_Severity" 2 "True_Medium_Severity" 1 "True_Low_Severity" 0 "False" ;
VAL_ 1465 DAS_sw015_RadarMisalignment 3 "True_High_Severity" 2 "True_Medium_Severity" 1 "True_Low_Severity" 0 "False" ;
VAL_ 1465 DAS_sw015_LowSun 3 "True_High_Severity" 2 "True_Medium_Severity" 1 "True_Low_Severity" 0 "False" ;
VAL_ 1465 DAS_sw015_BlurredImage 3 "True_High_Severity" 2 "True_Medium_Severity" 1 "True_Low_Severity" 0 "False" ;
VAL_ 1465 DAS_sw015_FullBlockage 3 "True_High_Severity" 2 "True_Medium_Severity" 1 "True_Low_Severity" 0 "False" ;
VAL_ 1465 DAS_sw015_PartialBlockage 3 "True_High_Severity" 2 "True_Medium_Severity" 1 "True_Low_Severity" 0 "False" ;
VAL_ 1465 DAS_sw015_AutofixOutOfCalib 3 "True_High_Severity" 2 "True_Medium_Severity" 1 "True_Low_Severity" 0 "False" ;
VAL_ 1465 DAS_sw015_AutofixOutOfCalibYaw 3 "True_High_Severity" 2 "True_Medium_Severity" 1 "True_Low_Severity" 0 "False" ;
VAL_ 1465 DAS_sw015_AutofixOOfCalibHorizon 3 "True_High_Severity" 2 "True_Medium_Severity" 1 "True_Low_Severity" 0 "False" ;
VAL_ 1465 DAS_sw015_Splashes 3 "True_High_Severity" 2 "True_Medium_Severity" 1 "True_Low_Severity" 0 "False" ;
VAL_ 1465 DAS_sw015_SmearedSpots 3 "True_High_Severity" 2 "True_Medium_Severity" 1 "True_Low_Severity" 0 "False" ;
VAL_ 1465 DAS_sw015_SmearedHalos 3 "True_High_Severity" 2 "True_Medium_Severity" 1 "True_Low_Severity" 0 "False" ;
VAL_ 1465 DAS_sw015_FoggyLights 3 "True_High_Severity" 2 "True_Medium_Severity" 1 "True_Low_Severity" 0 "False" ;
VAL_ 1465 DAS_sw015_SunRay 3 "True_High_Severity" 2 "True_Medium_Severity" 1 "True_Low_Severity" 0 "False" ;
VAL_ 1465 DAS_sw015_ImpairedVD 3 "True_High_Severity" 2 "True_Medium_Severity" 1 "True_Low_Severity" 0 "False" ;
VAL_ 1465 DAS_sw015_SelfGlare 3 "True_High_Severity" 2 "True_Medium_Severity" 1 "True_Low_Severity" 0 "False" ;
VAL_ 1465 DAS_sw015_OutOfFocusImage 3 "True_High_Severity" 2 "True_Medium_Severity" 1 "True_Low_Severity" 0 "False" ;
VAL_ 1465 DAS_sw017_Camera_Msg_Lanes_MIA 1 "True" 0 "False" ;
VAL_ 1465 DAS_sw017_Camera_Msg_Objects_MIA 1 "True" 0 "False" ;
VAL_ 1465 DAS_sw017_Camera_Msg_Tsr_MIA 1 "True" 0 "False" ;
VAL_ 1465 DAS_sw017_Camera_Msg_Hlb_MIA 1 "True" 0 "False" ;
VAL_ 1465 DAS_sw017_Camera_Msg_Common_MIA 1 "True" 0 "False" ;
VAL_ 1465 DAS_sw017_Camera_Msg_FCW_PCW_MIA 1 "True" 0 "False" ;
VAL_ 1465 DAS_sw017_Camera_Msg_TFL_MIA 1 "True" 0 "False" ;
VAL_ 1465 DAS_sw017_Any_Lanes_Msg_Recd 1 "True" 0 "False" ;
VAL_ 1465 DAS_sw017_Any_Objects_Msg_Recd 1 "True" 0 "False" ;
VAL_ 1465 DAS_sw017_Any_TFL_Msg_Recd 1 "True" 0 "False" ;
VAL_ 1465 DAS_sw017_Any_Tsr_Msg_Recd 1 "True" 0 "False" ;
VAL_ 1465 DAS_sw017_Any_Hlb_Msg_Recd 1 "True" 0 "False" ;
VAL_ 1465 DAS_sw017_Any_Common_Msg_Recd 1 "True" 0 "False" ;
VAL_ 1465 DAS_sw017_Any_FCW_PCW_Msg_Recd 1 "True" 0 "False" ;
VAL_ 1465 DAS_sw018_railID 3 "1v2_rail" 2 "1v8_rail" 1 "3v3_rail" 0 "5v0_rail" ;
VAL_ 1465 DAS_sw018_powerSequnceError 1 "True" 0 "False" ;
VAL_ 1465 DAS_sw018_railControl 1 "RAIL_ENABLED" 0 "RAIL_DISABLED" ;
VAL_ 1465 DAS_sw019_taskId 32 "MAX_TASK_ID" 31 "TASKS_ISOTERM_A72" 30 "TASKS_ISOTERM_SMS" 29 "TASKS_APP_1HZ" 28 "TASKS_APP_1KHZ" 27 "TASKS_SMS_SERIAL" 26 "TASKS_CAN_AP_RX" 25 "TASKS_CAN_AP_TX" 24 "TASKS_TMU" 23 "TASKS_WDG_TASK" 22 "TASKS_MBX_RELAY" 21 "TASKS_MBX_SCS_RX_HIGH" 20 "TASKS_MBX_SCS_RX_LOW" 19 "TASKS_MBX_SCS_TX_HIGH" 18 "TASKS_MBX_SCS_TX_LOW" 17 "TASKS_MBX_AP_RX_HIGH" 16 "TASKS_MBX_AP_RX_LOW" 15 "TASKS_MBX_AP_TX_HIGH" 14 "TASKS_MBX_AP_TX_LOW" 13 "TASKS_VEH_CAN" 12 "TASKS_RADAR_CAN" 11 "TASKS_CH_CAN" 10 "TASKS_PARTY_CAN" 9 "TASK_DEBUG_SMS_SERIAL_RX" 8 "TASK_DEBUG_SERIAL_TX" 7 "TASKS_SMS_SMS_UART_RX" 6 "TASKS_SMS_SMS_UART_TX" 5 "TASKS_VEHICLE" 4 "TASKS_MOBILEYE" 3 "TASKS_UDS" 2 "TASKS_CAN" 1 "TASKS_INIT" 0 "TASKS_RESERVED" ;
VAL_ 1465 DAS_sw021_tempSensorId 4 "DDR_TEMP_SENSOR" 3 "CAMERA_TEMP_SENSOR" 2 "EYE_Q_TEMP_SENSOR_1" 1 "EYE_Q_TEMP_SENSOR_0" 0 "EXTERNAL_TEMP_SENSOR" ;
VAL_ 1465 DAS_sw022_operation 4 "Erase All" 3 "Delete" 2 "Read" 1 "Write" 0 "Initialize" ;
VAL_ 1465 DAS_sw024_currentVehicleApp 162 "DAS_VA_LOC_MONITOR" 161 "DAS_VA_EAC_MONITOR" 160 "DAS_VA_VL_PROFILER" 159 "DAS_VA_VL_GM_VEH_EXIT" 158 "DAS_VA_VL_GM_MISC_END_VEH_ID5" 157 "DAS_VA_VL_GM_MISC_END_VEH_ID4" 156 "DAS_VA_VL_GM_MISC_END_VEH_ID3" 155 "DAS_VA_VL_GM_MISC_END_VEH_ID2" 154 "DAS_VA_VL_GM_MISC_END_VEH_ID1" 153 "DAS_VA_VL_GM_MISC_END_VEH_ID0" 152 "DAS_VA_VL_GM_HEADING_VEH_ID5" 151 "DAS_VA_VL_GM_HEADING_VEH_ID4" 150 "DAS_VA_VL_GM_HEADING_VEH_ID3" 149 "DAS_VA_VL_GM_HEADING_VEH_ID2" 148 "DAS_VA_VL_GM_HEADING_VEH_ID1" 147 "DAS_VA_VL_GM_HEADING_VEH_ID0" 146 "DAS_VA_VL_GM_NODP_LONG_VEH_ID5" 145 "DAS_VA_VL_GM_NODP_LONG_VEH_ID4" 144 "DAS_VA_VL_GM_NODP_LONG_VEH_ID3" 143 "DAS_VA_VL_GM_NODP_LONG_VEH_ID2" 142 "DAS_VA_VL_GM_NODP_LONG_VEH_ID1" 141 "DAS_VA_VL_GM_NODP_LONG_VEH_ID0" 140 "DAS_VA_VL_GM_NODP_LAT_VEH_ID5" 139 "DAS_VA_VL_GM_NODP_LAT_VEH_ID4" 138 "DAS_VA_VL_GM_NODP_LAT_VEH_ID3" 137 "DAS_VA_VL_GM_NODP_LAT_VEH_ID2" 136 "DAS_VA_VL_GM_NODP_LAT_VEH_ID1" 135 "DAS_VA_VL_GM_NODP_LAT_VEH_ID0" 134 "DAS_VA_VL_GM_NODP_FUSE_VEH_ID5" 133 "DAS_VA_VL_GM_NODP_FUSE_VEH_ID4" 132 "DAS_VA_VL_GM_NODP_FUSE_VEH_ID3" 131 "DAS_VA_VL_GM_NODP_FUSE_VEH_ID2" 130 "DAS_VA_VL_GM_NODP_FUSE_VEH_ID1" 129 "DAS_VA_VL_GM_NODP_FUSE_VEH_ID0" 128 "DAS_VA_VL_GM_DP_FUSE_VEH_ID5" 127 "DAS_VA_VL_GM_DP_FUSE_VEH_ID4" 126 "DAS_VA_VL_GM_DP_FUSE_VEH_ID3" 125 "DAS_VA_VL_GM_DP_FUSE_VEH_ID2" 124 "DAS_VA_VL_GM_DP_FUSE_VEH_ID1" 123 "DAS_VA_VL_GM_DP_FUSE_VEH_ID0" 122 "DAS_VA_VL_GM_DP_OLD_VEH_ID5" 121 "DAS_VA_VL_GM_DP_OLD_VEH_ID4" 120 "DAS_VA_VL_GM_DP_OLD_VEH_ID3" 119 "DAS_VA_VL_GM_DP_OLD_VEH_ID2" 118 "DAS_VA_VL_GM_DP_OLD_VEH_ID1" 117 "DAS_VA_VL_GM_DP_OLD_VEH_ID0" 116 "DAS_VA_VL_GM_DP_NEW_VEH_ID5" 115 "DAS_VA_VL_GM_DP_NEW_VEH_ID4" 114 "DAS_VA_VL_GM_DP_NEW_VEH_ID3" 113 "DAS_VA_VL_GM_DP_NEW_VEH_ID2" 112 "DAS_VA_VL_GM_DP_NEW_VEH_ID1" 111 "DAS_VA_VL_GM_DP_NEW_VEH_ID0" 110 "DAS_VA_VL_GM_DP_PRECHK_VEH_ID5" 109 "DAS_VA_VL_GM_DP_PRECHK_VEH_ID4" 108 "DAS_VA_VL_GM_DP_PRECHK_VEH_ID3" 107 "DAS_VA_VL_GM_DP_PRECHK_VEH_ID2" 106 "DAS_VA_VL_GM_DP_PRECHK_VEH_ID1" 105 "DAS_VA_VL_GM_DP_PRECHK_VEH_ID0" 104 "DAS_VA_VL_GM_INV_COV_VEH_ID5" 103 "DAS_VA_VL_GM_INV_COV_VEH_ID4" 102 "DAS_VA_VL_GM_INV_COV_VEH_ID3" 101 "DAS_VA_VL_GM_INV_COV_VEH_ID2" 100 "DAS_VA_VL_GM_INV_COV_VEH_ID1" 99 "DAS_VA_VL_GM_INV_COV_VEH_ID0" 98 "DAS_VA_VL_GM_OBS_XFM_VEH_ID5" 97 "DAS_VA_VL_GM_OBS_XFM_VEH_ID4" 96 "DAS_VA_VL_GM_OBS_XFM_VEH_ID3" 95 "DAS_VA_VL_GM_OBS_XFM_VEH_ID2" 94 "DAS_VA_VL_GM_OBS_XFM_VEH_ID1" 93 "DAS_VA_VL_GM_OBS_XFM_VEH_ID0" 92 "DAS_VA_VL_GM_COV_VEH_ID5" 91 "DAS_VA_VL_GM_COV_VEH_ID4" 90 "DAS_VA_VL_GM_COV_VEH_ID3" 89 "DAS_VA_VL_GM_COV_VEH_ID2" 88 "DAS_VA_VL_GM_COV_VEH_ID1" 87 "DAS_VA_VL_GM_COV_VEH_ID0" 86 "DAS_VA_VL_GM_CHK_LANE_VEH_ID5" 85 "DAS_VA_VL_GM_CHK_LANE_VEH_ID4" 84 "DAS_VA_VL_GM_CHK_LANE_VEH_ID3" 83 "DAS_VA_VL_GM_CHK_LANE_VEH_ID2" 82 "DAS_VA_VL_GM_CHK_LANE_VEH_ID1" 81 "DAS_VA_VL_GM_CHK_LANE_VEH_ID0" 80 "DAS_VA_VL_GM_CHK_ID_VEH_ID5" 79 "DAS_VA_VL_GM_CHK_ID_VEH_ID4" 78 "DAS_VA_VL_GM_CHK_ID_VEH_ID3" 77 "DAS_VA_VL_GM_CHK_ID_VEH_ID2" 76 "DAS_VA_VL_GM_CHK_ID_VEH_ID1" 75 "DAS_VA_VL_GM_CHK_ID_VEH_ID0" 74 "DAS_VA_ROB" 73 "DAS_VA_VL_GM_EVAL_SAVE" 72 "DAS_VA_VL_GM_EVAL_NEW_VEH_5" 71 "DAS_VA_VL_GM_EVAL_NEW_VEH_4" 70 "DAS_VA_VL_GM_EVAL_NEW_VEH_3" 69 "DAS_VA_VL_GM_EVAL_NEW_VEH_2" 68 "DAS_VA_VL_GM_EVAL_NEW_VEH_1" 67 "DAS_VA_VL_GM_EVAL_NEW_VEH_0" 66 "DAS_VA_VL_GM_EVAL_VEH_5" 65 "DAS_VA_VL_GM_EVAL_VEH_4" 64 "DAS_VA_VL_GM_EVAL_VEH_3" 63 "DAS_VA_VL_GM_EVAL_VEH_2" 62 "DAS_VA_VL_GM_EVAL_VEH_1" 61 "DAS_VA_VL_GM_EVAL_VEH_0" 60 "DAS_VA_VL_GM_EVAL_NAV" 59 "DAS_VA_VL_GM_EVAL_HPP" 58 "DAS_VA_VL_GM_EVAL_RL" 57 "DAS_VA_VL_GM_EVAL_LL" 56 "DAS_VA_VL_GM_EVAL_MODEL" 55 "DAS_VA_VL_GM_EVAL_SETUP" 54 "DAS_VA_VL_GM_EVAL" 53 "DAS_VA_VL_GM_VEH_ID5" 52 "DAS_VA_VL_GM_VEH_ID4" 51 "DAS_VA_VL_GM_VEH_ID3" 50 "DAS_VA_VL_GM_VEH_ID2" 49 "DAS_VA_VL_GM_VEH_ID1" 48 "DAS_VA_VL_GM_VEH_ID0" 47 "DAS_VA_VL_GM_VEH_2" 46 "DAS_VA_VL_GM_NAV_2" 45 "DAS_VA_VL_GM_FS_2" 44 "DAS_VA_VL_GM_HPP_2" 43 "DAS_VA_VL_GM_LANE_2" 42 "DAS_VA_VL_GM_NAV_1" 41 "DAS_VA_VL_GM_VEH_1" 40 "DAS_VA_VL_GM_FS_1" 39 "DAS_VA_VL_GM_HPP_1" 38 "DAS_VA_VL_GM_LANE_1" 37 "DAS_VA_VL_GM_SETUP" 36 "DAS_VA_VL_UU" 35 "DAS_VA_VL_CDH" 34 "DAS_VA_VL_MP" 33 "DAS_VA_VL_ETC" 32 "DAS_VA_VL_GM" 31 "DAS_VA_VL_CMC" 30 "DAS_VA_VL_CFELC" 29 "DAS_VA_VL_UELP" 28 "DAS_VA_VL_CCM" 27 "DAS_VA_VL_CDE" 26 "DAS_VA_VL_SM" 25 "DAS_VA_VL_UFC" 24 "DAS_VA_VL_FM" 23 "DAS_VA_VL_UNO" 22 "DAS_VA_VL_ULWE" 21 "DAS_VA_VL_CFKO" 20 "DAS_VA_VL_RLV" 19 "DAS_VA_VL_SO" 18 "DAS_VA_ROAD_FURNITURE" 17 "DAS_VA_VIRTUAL_WALL" 16 "DAS_VA_VIRTUAL_LANE" 15 "DAS_VA_WORLD_MODEL" 14 "DAS_VA_TRAJECTORY_PLANNER" 13 "DAS_VA_CSA" 12 "DAS_VA_TSR" 11 "DAS_VA_LDW" 10 "DAS_VA_ACC" 9 "DAS_VA_FCM" 8 "DAS_VA_LC" 7 "DAS_VA_BSD" 6 "DAS_VA_AHB" 5 "DAS_VA_SCA" 4 "DAS_VA_APC" 3 "DAS_VA_PMM" 2 "DAS_VA_VEHICLE" 1 "DAS_VA_INIT" 0 "DAS_VA_NONE" ;
VAL_ 1465 DAS_sw025_state_before_override 14 "LC_INTERNAL_STATE_NUM_STATES" 13 "LC_INTERNAL_STATE_FULL_ABORTED" 12 "LC_INTERNAL_STATE_FULL_ABORTING" 11 "LC_INTERNAL_STATE_AUTOSTEER_ABORTED" 10 "LC_INTERNAL_STATE_AUTOSTEER_ABORTING" 9 "LC_INTERNAL_STATE_AUTOSTEER_CANCELING" 8 "LC_INTERNAL_STATE_AUTOSTEER_ACTIVE" 7 "LC_INTERNAL_STATE_AUTOSTEER_PREACTIVE" 6 "LC_INTERNAL_STATE_ACC_ACTIVE_AUTOSTEER_AVAILABLE" 5 "LC_INTERNAL_STATE_ACC_ACTIVE_AUTOSTEER_UNAVAILABLE" 4 "LC_INTERNAL_STATE_AUTOSTEER_AVAILABLE" 3 "LC_INTERNAL_STATE_ACC_AVAIALABLE" 2 "LC_INTERNAL_STATE_UNAVAILABLE" 1 "LC_INTERNAL_STATE_DISABLED" 0 "LC_INTERNAL_STATE_FAULT" ;
VAL_ 1465 DAS_sw025_leftLaneUsage 3 "BLACKLISTED" 2 "FUSED" 1 "AVAILABLE" 0 "REJECTED_UNAVAILABLE" ;
VAL_ 1465 DAS_sw025_rightLaneUsage 3 "BLACKLISTED" 2 "FUSED" 1 "AVAILABLE" 0 "REJECTED_UNAVAILABLE" ;
VAL_ 1465 DAS_sw025_vehiclesUsage 3 "BLACKLISTED" 2 "FUSED" 1 "AVAILABLE" 0 "REJECTED_UNAVAILABLE" ;
VAL_ 1465 DAS_sw025_hppUsage 3 "BLACKLISTED" 2 "FUSED" 1 "AVAILABLE" 0 "REJECTED_UNAVAILABLE" ;
VAL_ 1465 DAS_sw025_navigationUsage 3 "BLACKLISTED" 2 "FUSED" 1 "AVAILABLE" 0 "REJECTED_UNAVAILABLE" ;
VAL_ 1465 DAS_sw025_modelUsage 3 "BLACKLISTED" 2 "FUSED" 1 "AVAILABLE" 0 "REJECTED_UNAVAILABLE" ;
VAL_ 1465 DAS_sw025_bottsDotsUsage 3 "BLACKLISTED" 2 "FUSED" 1 "AVAILABLE" 0 "REJECTED_UNAVAILABLE" ;
VAL_ 1465 DAS_sw025_offsetSide 3 "OFFSET_BOTH_OBJECTS" 2 "OFFSET_LEFT_OBJECT" 1 "OFFSET_RIGHT_OBJECT" 0 "NO_OFFSET" ;
VAL_ 1465 DAS_sw026_task_id 3 "Vehicle" 2 "Mobileye" 1 "UDS" 0 "CAN" ;
VAL_ 1465 DAS_sw030_heaterState 3 "UNAVAILABLE" 2 "SHORT" 1 "OPEN" 0 "NORMAL" ;
VAL_ 1465 DAS_sw031_canBus 7 "Unknown" 3 "PT" 2 "PARTY" 1 "RAD0" 0 "CH" ;
VAL_ 1465 DAS_sw031_errorType 8 "Generic" 7 "CAN Bus" 6 "Mailbox" 5 "Overrun" 4 "Invalid Data" 3 "Sequence" 2 "Checksum" 1 "Length" 0 "None" ;
VAL_ 1465 DAS_sw032_canBus 7 "Unknown" 3 "PT" 2 "PARTY" 1 "RAD0" 0 "CH" ;
VAL_ 1465 DAS_sw032_errorType 2 "Generic" 1 "Overrun" 0 "None" ;
VAL_ 1465 DAS_sw033_gtwMia 128 "CH_BC_status_MIA" 7 "CH_GTW_carConfig2_MIA" 6 "CH_VIP_405HS_MIA" 5 "CH_GTW_time_MIA" 4 "CH_GTW_status_MIA" 3 "CH_GTW_odo_MIA" 2 "CH_GTW_chNm_MIA" 1 "CH_GTW_carConfig_MIA" 0 "Nominal" ;
VAL_ 1465 DAS_sw034_sccmMia 2 "CH_STW_ANGLHP_STAT_MIA" 1 "CH_STW_ACTN_RQ_MIA" 0 "Nominal" ;
VAL_ 1465 DAS_sw035_espMia 9 "ESP_B_MIA" 8 "ESP_wheelSpeeds_MIA" 7 "ESP_115h_MIA" 6 "DISCONTINUED_ESP_E_MIA" 5 "ESP_C_MIA" 4 "DISCONTINUED_ESP_A_MIA" 3 "ESP_145h_MIA" 2 "ESP_135h_MIA" 1 "ESP_125h_MIA" 0 "Nominal" ;
VAL_ 1465 DAS_sw036_bdyMia 130 "CH_BCS2C_restraintStatus_MIA" 129 "CH_BCS2L_restraintStatus_MIA" 128 "CH_BCS2R_restraintStatus_MIA" 1 "BDY_status_MIA" 0 "Nominal" ;
VAL_ 1465 DAS_sw037_issue 1 "Invalid parameters" 0 "Failed to read" ;
VAL_ 1465 DAS_sw038_RadarMisalignment 1 "True" 0 "False" ;
VAL_ 1465 DAS_sw038_OutOfFocusImage 1 "True" 0 "False" ;
VAL_ 1465 DAS_sw038_AutofixOutOfCalib 1 "True" 0 "False" ;
VAL_ 1465 DAS_sw038_AutofixOutOfCalibHorzn 1 "True" 0 "False" ;
VAL_ 1465 DAS_sw038_AutofixOutOfCalibYaw 1 "True" 0 "False" ;
VAL_ 1465 DAS_sw038_FullBlockage 1 "True" 0 "False" ;
VAL_ 1465 DAS_sw039_sdm_rcm_Mia 128 "CH_RCM_STATUS_MIA" 1 "CH_SDM1_MIA" 0 "Nominal" ;
VAL_ 1465 DAS_sw042_health_state 7 "AP_HEALTH_SNA" 6 "AP_HEALTH_UNUSED" 5 "AP_HEALTH_FAULT" 4 "AP_HEALTH_ABORTING" 3 "AP_HEALTH_SEVERELY_DEGRADED" 2 "AP_HEALTH_DEGRADED" 1 "AP_HEALTH_NOMINAL" 0 "AP_HEALTH_UNAVAILABLE" ;
VAL_ 1465 DAS_sw042_abort_reason 27 "LC_ABORT_USER_OVERRIDE_STRIKEOUT" 26 "LC_ABORT_SEATBELT_UNBUCKLED" 25 "LC_ABORT_AEB" 24 "LC_ABORT_DRIVE_ON_MAPS" 23 "LC_ABORT_ECU_THERMAL_ISSUE" 22 "LC_ABORT_CRUISE_WENT_UNAVAILABLE" 21 "RR_ABORT_CONTROL_NOT_ALLOWED" 20 "RR_ABORT_CONTROLLER_HEALTH" 19 "RR_ABORT_WATCHDOG_HEALTH_CRITICAL" 18 "LC_ABORT_APP_ME_STATE" 17 "LC_ABORT_ME_MAIN_STATE" 16 "LC_ABORT_CAMERA_MSG_MIA" 15 "LC_ABORT_CAMERA_WATCHDOG" 14 "LC_ABORT_TRAILER_MODE_ACTIVATION" 13 "LC_ABORT_SIDE_COLLISION_IMMINENT" 12 "LC_ABORT_ACC_CANCEL" 11 "LC_ABORT_CAMERA_FAILSAFES" 10 "LC_ABORT_EPAS_ERROR_CODE" 9 "LC_ABORT_PLANNER_OUTPUT_INVALID" 8 "LC_ABORT_FOLLOWER_OUTPUT_INVALID" 7 "LC_ABORT_VEHICLE_SPEED_ABOVE_MAX" 6 "LC_ABORT_HEALTH_MONITOR" 5 "LC_ABORT_DRIVING_OFF_NAV" 4 "LC_ABORT_CID_SWITCH_DISABLED" 3 "LC_ABORT_CRUISE_FAULT" 2 "LC_ABORT_COMPONENT_MIA" 1 "LC_ABORT_EPAS_EAC_DENIED" 0 "LC_ABORT_NONE" ;
VAL_ 1465 DAS_sw042_state_before_abort 15 "LC_INTERNAL_STATE_PRECANCEL" 14 "LC_INTERNAL_STATE_DRIVER_STEERING_OVERRIDE" 13 "LC_INTERNAL_STATE_PREABORTED" 12 "LC_INTERNAL_STATE_FAULT" 11 "LC_INTERNAL_STATE_ABORTED" 10 "LC_INTERNAL_STATE_ABORTING" 9 "LC_INTERNAL_STATE_CHECK_ACTIVATION_WHILE_UNAVAILABLE" 8 "LC_INTERNAL_STATE_CHECK_ACTIVATION_WHILE_DISABLED" 7 "LC_INTERNAL_STATE_ACTIVE_RESTRICTED" 6 "LC_INTERNAL_STATE_ACTIVE_NOMINAL" 5 "LC_INTERNAL_STATE_PREACTIVATION" 4 "LC_INTERNAL_STATE_CHECK_FOR_ACTIVATION" 3 "LC_INTERNAL_STATE_AVAILABLE" 2 "LC_INTERNAL_STATE_UNAVAILABLE" 1 "LC_INTERNAL_STATE_DISABLED" 0 "LC_INTERNAL_STATE_NO_AUTOPILOT" ;
VAL_ 1465 DAS_sw042_epas_error_code 15 "SNA" 13 "EAC_ERROR_PINION_VEL_DIFF" 12 "EAC_ERROR_LOW_ASSIST" 11 "EAC_ERROR_HIGH_TORSION_SAFETY" 10 "EAC_ERROR_HIGH_MMOT_SAFETY" 9 "EAC_ERROR_HIGH_ANGLE_RATE_SAFETY" 8 "EAC_ERROR_HIGH_ANGLE_SAFETY" 7 "EAC_ERROR_HIGH_ANGLE_RATE_REQ" 6 "EAC_ERROR_HIGH_ANGLE_REQ" 5 "EAR_ERROR_MAX_STEER_DELTA" 4 "EAC_ERROR_TMP_FAULT" 3 "EAC_ERROR_HANDS_ON" 2 "EAC_ERROR_MAX_SPEED" 1 "EAC_ERROR_MIN_SPEED" 0 "EAC_ERROR_IDLE" ;
VAL_ 1465 DAS_sw043_mobileye_status 24 "MOBILEYE_STATUS_UNDEFINED" 23 "MOBILEYE_STATUS_TEARDOWN_FLASH_ACCESS_MODE" 22 "MOBILEYE_STATUS_FLASH_READ_MODE" 21 "MOBILEYE_STATUS_SETUP_FLASH_ACCESS_MODE" 20 "MOBILEYE_STATUS_RUNNING_SPTAC_MODE" 19 "MOBILEYE_STATUS_SPTAC_INIT_SENT" 18 "MOBILEYE_STATUS_WAITING_FOR_SPTAC_INIT" 17 "MOBILEYE_STATUS_BURN_EDR_MODE" 16 "MOBILEYE_STATUS_SPC_INIT_SENT" 15 "MOBILEYE_STATUS_WAITING_FOR_SPC_INIT" 14 "MOBILEYE_STATUS_ERROR" 13 "MOBILEYE_STATUS_LATCHING_FAILURE" 12 "MOBILEYE_STATUS_UPDATING" 11 "MOBILEYE_STATUS_RUNNING_DV_MODE" 10 "MOBILEYE_STATUS_WAITING_FOR_DV" 9 "MOBILEYE_STATUS_RUNNING_TAC_MODE" 8 "MOBILEYE_STATUS_RUNNING_SPC_MODE" 7 "MOBILEYE_STATUS_RUNNING_VISION_MODE" 6 "MOBILEYE_STATUS_TAC_INIT_SENT" 5 "MOBILEYE_STATUS_WAITING_FOR_TAC_INIT" 4 "MOBILEYE_STATUS_VISION_INIT_SENT" 3 "MOBILEYE_STATUS_WAITING_FOR_VISION_INIT" 2 "MOBILEYE_STATUS_WAITING_FOR_BOOT" 1 "MOBILEYE_STATUS_POWER_OFF" 0 "MOBILEYE_STATUS_POWER_CYCLE" ;
VAL_ 1465 DAS_sw043_mesp_health_main_state 172 "EYEQ_MESP_MAIN_STATE_TAC2" 170 "EYEQ_MESP_MAIN_STATE_DV" 146 "EYEQ_MESP_MAIN_STATE_VISION_INIT_PENDING" 133 "EYEQ_MESP_MAIN_STATE_TAC2_INIT_PENDING" 130 "EYEQ_MESP_MAIN_STATE_SPC_INIT_PENDING" 129 "EYEQ_MESP_MAIN_STATE_SPTAC_INIT_PENDING" 34 "EYEQ_MESP_MAIN_STATE_SPC" 33 "EYEQ_MESP_MAIN_STATE_SPTAC" 2 "EYEQ_MESP_MAIN_STATE_VISION" ;
VAL_ 1465 DAS_sw044_meMainState 8 "ERROR" 7 "DV" 6 "TAC2" 5 "TAC2_INIT_PENDING" 4 "SPC" 3 "SPC_INIT_PENDING" 2 "VISION" 1 "VISION_INIT_PENDING" 0 "NOT_INITIALIZED" ;
VAL_ 1465 DAS_sw044_appStatus 24 "MOBILEYE_STATUS_UNDEFINED" 23 "MOBILEYE_STATUS_TEARDOWN_FLASH_ACCESS_MODE" 22 "MOBILEYE_STATUS_FLASH_READ_MODE" 21 "MOBILEYE_STATUS_SETUP_FLASH_ACCESS_MODE" 20 "MOBILEYE_STATUS_RUNNING_SPTAC_MODE" 19 "MOBILEYE_STATUS_SPTAC_INIT_SENT" 18 "MOBILEYE_STATUS_WAITING_FOR_SPTAC_INIT" 17 "MOBILEYE_STATUS_BURN_EDR_MODE" 16 "MOBILEYE_STATUS_SPC_INIT_SENT" 15 "MOBILEYE_STATUS_WAITING_FOR_SPC_INIT" 14 "MOBILEYE_STATUS_ERROR" 13 "MOBILEYE_STATUS_LATCHING_FAILURE" 12 "MOBILEYE_STATUS_UPDATING" 11 "MOBILEYE_STATUS_RUNNING_DV_MODE" 10 "MOBILEYE_STATUS_WAITING_FOR_DV" 9 "MOBILEYE_STATUS_RUNNING_TAC_MODE" 8 "MOBILEYE_STATUS_RUNNING_SPC_MODE" 7 "MOBILEYE_STATUS_RUNNING_VISION_MODE" 6 "MOBILEYE_STATUS_TAC_INIT_SENT" 5 "MOBILEYE_STATUS_WAITING_FOR_TAC_INIT" 4 "MOBILEYE_STATUS_VISION_INIT_SENT" 3 "MOBILEYE_STATUS_WAITING_FOR_VISION_INIT" 2 "MOBILEYE_STATUS_WAITING_FOR_BOOT" 1 "MOBILEYE_STATUS_POWER_OFF" 0 "MOBILEYE_STATUS_POWER_CYCLE" ;
VAL_ 1465 DAS_sw045_radMia 21 "RAD0_RADC_TGU_info_MIA" 20 "RAD0_RADC_SGU_info_MIA" 19 "RAD0_RADC_ACCTargObj1_A_MIA" 18 "RAD0_RADC_ACCTargObj1_B_MIA" 17 "RAD0_RADC_ACCTargObj1_C_MIA" 16 "RAD0_RADC_ACCTargObj2_A_MIA" 15 "RAD0_RADC_ACCTargObj2_B_MIA" 14 "RAD0_RADC_ACCTargObj2_C_MIA" 13 "RAD0_RADC_ACCTargObj3_C_MIA" 12 "RAD0_RADC_ACCTargObj4_C_MIA" 11 "RAD0_RADC_ACCTargObj5_A_MIA" 10 "RAD0_RADC_ACCTargObj5_B_MIA" 9 "RAD0_RADC_ACCTargObj5_C_MIA" 8 "RAD0_RADC_FCWTargObj_A_MIA" 7 "RAD0_RADC_FCWTargObj_B_MIA" 6 "RAD0_RADC_FCWTargObj_C_MIA" 5 "RAD0_RADC_Packet_Ender_MIA" 4 "RAD0_RADC_Packet_Starter_MIA" 3 "RAD0_RADC_info_MIA" 2 "RAD0_RADRL_alertMatrix_MIA" 1 "RAD0_RADC_alertMatrix_MIA" 0 "Nominal" ;
VAL_ 1465 DAS_sw047_edrStatus 6 "EVENT_TRIGGER_REJECTED" 5 "EVENT_SAVED_TO_FLASH" 4 "EVENT_SAVED_TO_LB" 3 "EVENT_TRIGGERED" 2 "EVENT_ERASED" 1 "FAULTED" 0 "EMPTY" ;
VAL_ 1465 DAS_sw047_edrType 13 "PMM_IPSO_TYPE" 12 "ROB_SILENT_TYPE" 11 "ROB_ACTIVE_TYPE" 10 "FREESPACE_ELDW" 9 "AIRBAG_NEAR_DEPLOY" 8 "PMM" 7 "IN_PATH_STAT_OBJ" 6 "SILENT_AEB" 5 "UDS" 4 "FCW" 3 "HEAVY_BRAKING" 2 "AEB" 1 "AIRBAG_DEPLOY" 0 "UNDEFINED" ;
VAL_ 1465 DAS_sw047_edrReturn 4000 "ERROR_EDR_MANAGER" 3000 "ERROR_DUMP_FAILED" 2000 "ERROR_LOG_DATA_FAILED" 1027 "ERROR_EDR_MANAGER_INVALID" 1026 "ERROR_POST_TRIGGER_NUM_TOO_LARGE" 1025 "ERROR_BB_NOT_FORMATTED" 1024 "ERROR_BB_VALIDATE_PROBLEM" 1023 "ERROR_FAILED_NO_DESC_AVALIABLE" 1022 "ERROR_NOT_ENOUGH_FRAMES_IN_LB" 1021 "ERROR_FAILED_WRITE_DATA_TO_BB" 1020 "ERROR_FAILED_NO_DATA_AVALIABLE" 1019 "ERROR_LB_CLIP_NOT_AVALIABLE" 1018 "ERROR_LB_ALREADY_CURRENT" 1017 "ERROR_WRONG_STATE" 1016 "ERROR_WRONG_LOGGER_BUFFER" 1015 "ERROR_FAILED_DUMP_LB_TO_BB" 1014 "ERROR_FAILED_FORMAT_BB" 1013 "ERROR_FAILED_TO_BURN_TO_REG_BB" 1012 "ERROR_NOTHING_TO_UPDATE" 1011 "ERROR_WRONG_CURR_TAG" 1010 "ERROR_BB_REG_ERROROR" 1009 "ERROR_DATA_SIZE_MISMATCH" 1008 "ERROR_FUNC_FAILED" 1006 "ERROR_PROCESS_OTHER_TASK" 1005 "ERROR_NO_DATA_TO_SAVE" 1004 "ERROR_FLASH_BB_LOCK" 1003 "ERROR_IMAGE_LOGGER_NOT_FOUND" 1002 "ERROR_BB_NOT_FOUND" 1001 "ERROR_INIT" 1000 "ERROR_UNDEFINED" 107 "ERROR_FUNC_NOT_EXIST" 0 "SUCCESS" ;
VAL_ 1465 DAS_sw047_edrStateMachine 255 "EDR_FATAL_ERROR" 54 "PROCESS_EDR_NB_EXECUTE" 53 "PROCESS_EDR_EXECUTE_PART_2" 52 "PROCESS_EDR_EXECUTE_PART_1" 51 "PROCESS_EDR_MAP_LB_TO_BB" 34 "PROCESS_EDR_BB_CANCEL_FORMAT" 33 "PROCESS_EDR_BB_FORMAT" 32 "PROCESS_EDR_BB_GET_DESC" 30 "PROCESS_EDR_BB_QUERY" 16 "PROCESS_EDR_LB_SWITCH" 14 "PROCESS_EDR_LB_SET_DATA" 13 "PROCESS_EDR_LB_SET_DESC" 12 "PROCESS_EDR_LB_TRIGGER_EVENT" 11 "PROCESS_EDR_LB_QUERY" 10 "PROCESS_EDR_LB_GET_CURR" 4 "EDR_BURN_COMPLETE" 2 "EDR_TRIGGERED" 1 "RUNNING" 0 "IDLE" ;
VAL_ 1465 DAS_sw049_boot_version_msw 65535 "FLASH_SECTION_EMPTY" 24589 "NO_MISMATCH" 0 "FLASH_READ_FAILURE" ;
VAL_ 1465 DAS_sw049_app_version_msw 65535 "FLASH_SECTION_EMPTY" 24589 "NO_MISMATCH" 0 "FLASH_READ_FAILURE" ;
VAL_ 1465 DAS_sw049_ffs_version_msw 65535 "FLASH_SECTION_EMPTY" 24589 "NO_MISMATCH" 0 "FLASH_READ_FAILURE" ;
VAL_ 1465 DAS_sw051_a01ecuInternalPerf 1 "True" 0 "False" ;
VAL_ 1465 DAS_sw051_a02flashPerformance 1 "True" 0 "False" ;
VAL_ 1465 DAS_sw051_a03vBatHigh 1 "True" 0 "False" ;
VAL_ 1465 DAS_sw051_a09configMismatch 1 "True" 0 "False" ;
VAL_ 1465 DAS_sw051_a52radomeHtrInop 1 "True" 0 "False" ;
VAL_ 1465 DAS_sw052_a07sensorBlinded 1 "True" 0 "False" ;
VAL_ 1465 DAS_sw056_diMia 5 "CH_DI_state2_MIA" 4 "CH_DI_espControl_MIA" 3 "CH_DI_torque2_MIA" 2 "CH_DI_torque1_MIA" 1 "CH_DI_state_MIA" 0 "Nominal" ;
VAL_ 1465 DAS_sw057_chCtrlMia 1 "TRUE" 0 "FALSE" ;
VAL_ 1465 DAS_sw057_csaOfframpCurvMia 1 "TRUE" 0 "FALSE" ;
VAL_ 1465 DAS_sw057_csaRoadCurvMia 1 "TRUE" 0 "FALSE" ;
VAL_ 1465 DAS_sw057_dasControlMia 1 "TRUE" 0 "FALSE" ;
VAL_ 1465 DAS_sw057_dasMapDataMia 1 "TRUE" 0 "FALSE" ;
VAL_ 1465 DAS_sw057_gpsVehSpeedMia 1 "TRUE" 0 "FALSE" ;
VAL_ 1465 DAS_sw057_locStatusMia 1 "TRUE" 0 "FALSE" ;
VAL_ 1465 DAS_sw057_radarMapDataMia 1 "TRUE" 0 "FALSE" ;
VAL_ 1465 DAS_sw057_roadCurvMia 1 "TRUE" 0 "FALSE" ;
VAL_ 1465 DAS_sw057_solarDataMia 1 "TRUE" 0 "FALSE" ;
VAL_ 1465 DAS_sw057_telemetryControlMia 1 "TRUE" 0 "FALSE" ;
VAL_ 1465 DAS_sw057_statusMia 1 "TRUE" 0 "FALSE" ;
VAL_ 1465 DAS_sw057_autopilotControlMia 1 "TRUE" 0 "FALSE" ;
VAL_ 1465 DAS_sw058_epbMia 1 "CH_EPB_status_MIA" 0 "Nominal" ;
VAL_ 1465 DAS_sw059_parkMia 11 "CH_PARK_pasRearMiddle_MIA" 10 "CH_PARK_sensorStatusRear_MIA" 9 "CH_PARK_oloDict_MIA" 8 "CH_PARK_status2_MIA" 7 "CH_PARK_pasFrontMiddle_MIA" 6 "CH_PARK_sensorStatusFront_MIA" 5 "CH_PARK_status_MIA" 4 "CH_PARK_oocStatus_MIA" 3 "CH_PARK_sdiRear_MIA" 2 "CH_PARK_pscStatus_MIA" 1 "CH_PARK_sdiFront_MIA" 0 "Nominal" ;
VAL_ 1465 DAS_sw060_collisionWarningSource 7 "SOURCE_BCW_PEDESTRIAN" 6 "SOURCE_BCW_MCVLR" 5 "SOURCE_BCW_CIPV2" 4 "SOURCE_BCW_CIPV" 3 "SOURCE_BCW_CUTIN" 2 "SOURCE_STOPLINE" 1 "SOURCE_FCW_VEHICLE" 0 "SOURCE_FCW_PEDESTRIAN" ;
VAL_ 1465 DAS_sw061_airSuspensionMia 128 "CH_TAS_STATES_MIA" 1 "CH_ASD_A2_MIA" 0 "Nominal" ;
VAL_ 1465 DAS_sw064_epasMia 2 "PARTY_EPAS_sysStatus_MIA" 1 "CH_EPAS_sysStatus_MIA" 0 "Nominal" ;
VAL_ 1465 DAS_sw065_app_mobileye_status 24 "MOBILEYE_STATUS_UNDEFINED" 23 "MOBILEYE_STATUS_TEARDOWN_FLASH_ACCESS_MODE" 22 "MOBILEYE_STATUS_FLASH_READ_MODE" 21 "MOBILEYE_STATUS_SETUP_FLASH_ACCESS_MODE" 20 "MOBILEYE_STATUS_RUNNING_SPTAC_MODE" 19 "MOBILEYE_STATUS_SPTAC_INIT_SENT" 18 "MOBILEYE_STATUS_WAITING_FOR_SPTAC_INIT" 17 "MOBILEYE_STATUS_BURN_EDR_MODE" 16 "MOBILEYE_STATUS_SPC_INIT_SENT" 15 "MOBILEYE_STATUS_WAITING_FOR_SPC_INIT" 14 "MOBILEYE_STATUS_ERROR" 13 "MOBILEYE_STATUS_LATCHING_FAILURE" 12 "MOBILEYE_STATUS_UPDATING" 11 "MOBILEYE_STATUS_RUNNING_DV_MODE" 10 "MOBILEYE_STATUS_WAITING_FOR_DV" 9 "MOBILEYE_STATUS_RUNNING_TAC_MODE" 8 "MOBILEYE_STATUS_RUNNING_SPC_MODE" 7 "MOBILEYE_STATUS_RUNNING_VISION_MODE" 6 "MOBILEYE_STATUS_TAC_INIT_SENT" 5 "MOBILEYE_STATUS_WAITING_FOR_TAC_INIT" 4 "MOBILEYE_STATUS_VISION_INIT_SENT" 3 "MOBILEYE_STATUS_WAITING_FOR_VISION_INIT" 2 "MOBILEYE_STATUS_WAITING_FOR_BOOT" 1 "MOBILEYE_STATUS_POWER_OFF" 0 "MOBILEYE_STATUS_POWER_CYCLE" ;
VAL_ 1465 DAS_sw065_mobileye_main_state 255 "EYEQ_MESP_MAIN_STATE_UNDEFINED" 172 "EYEQ_MESP_MAIN_STATE_TAC2" 170 "EYEQ_MESP_MAIN_STATE_DV" 146 "EYEQ_MESP_MAIN_STATE_VISION_INIT_PENDING" 133 "EYEQ_MESP_MAIN_STATE_TAC2_INIT_PENDING" 130 "EYEQ_MESP_MAIN_STATE_SPC_INIT_PENDING" 129 "EYEQ_MESP_MAIN_STATE_SPTAC_INIT_PENDING" 34 "EYEQ_MESP_MAIN_STATE_SPC" 33 "EYEQ_MESP_MAIN_STATE_SPTAC" 2 "EYEQ_MESP_MAIN_STATE_VISION" ;
VAL_ 1465 DAS_sw066_app_mobileye_status 24 "MOBILEYE_STATUS_UNDEFINED" 23 "MOBILEYE_STATUS_TEARDOWN_FLASH_ACCESS_MODE" 22 "MOBILEYE_STATUS_FLASH_READ_MODE" 21 "MOBILEYE_STATUS_SETUP_FLASH_ACCESS_MODE" 20 "MOBILEYE_STATUS_RUNNING_SPTAC_MODE" 19 "MOBILEYE_STATUS_SPTAC_INIT_SENT" 18 "MOBILEYE_STATUS_WAITING_FOR_SPTAC_INIT" 17 "MOBILEYE_STATUS_BURN_EDR_MODE" 16 "MOBILEYE_STATUS_SPC_INIT_SENT" 15 "MOBILEYE_STATUS_WAITING_FOR_SPC_INIT" 14 "MOBILEYE_STATUS_ERROR" 13 "MOBILEYE_STATUS_LATCHING_FAILURE" 12 "MOBILEYE_STATUS_UPDATING" 11 "MOBILEYE_STATUS_RUNNING_DV_MODE" 10 "MOBILEYE_STATUS_WAITING_FOR_DV" 9 "MOBILEYE_STATUS_RUNNING_TAC_MODE" 8 "MOBILEYE_STATUS_RUNNING_SPC_MODE" 7 "MOBILEYE_STATUS_RUNNING_VISION_MODE" 6 "MOBILEYE_STATUS_TAC_INIT_SENT" 5 "MOBILEYE_STATUS_WAITING_FOR_TAC_INIT" 4 "MOBILEYE_STATUS_VISION_INIT_SENT" 3 "MOBILEYE_STATUS_WAITING_FOR_VISION_INIT" 2 "MOBILEYE_STATUS_WAITING_FOR_BOOT" 1 "MOBILEYE_STATUS_POWER_OFF" 0 "MOBILEYE_STATUS_POWER_CYCLE" ;
VAL_ 1465 DAS_sw066_mobileye_main_state 255 "EYEQ_MESP_MAIN_STATE_UNDEFINED" 172 "EYEQ_MESP_MAIN_STATE_TAC2" 170 "EYEQ_MESP_MAIN_STATE_DV" 146 "EYEQ_MESP_MAIN_STATE_VISION_INIT_PENDING" 133 "EYEQ_MESP_MAIN_STATE_TAC2_INIT_PENDING" 130 "EYEQ_MESP_MAIN_STATE_SPC_INIT_PENDING" 129 "EYEQ_MESP_MAIN_STATE_SPTAC_INIT_PENDING" 34 "EYEQ_MESP_MAIN_STATE_SPC" 33 "EYEQ_MESP_MAIN_STATE_SPTAC" 2 "EYEQ_MESP_MAIN_STATE_VISION" ;
VAL_ 1465 DAS_sw069_epasMia 1 "EPAS_MIA" 0 "NO_EPAS_MIA" ;
VAL_ 1465 DAS_sw069_espMia 1 "ESP_MIA" 0 "NO_ESP_MIA" ;
VAL_ 1465 DAS_sw069_parkMia 1 "PARK_MIA" 0 "NO_PARK_MIA" ;
VAL_ 1465 DAS_sw069_sccmMia 1 "SCCM_MIA" 0 "NO_SCCM_MIA" ;
VAL_ 1465 DAS_sw069_parkMismatch 1 "PARK_VERSION_MISMATCH" 0 "NO_PARK_VERSION_MISMATCH" ;
VAL_ 1465 DAS_sw069_eacStatus 7 "EAC_ELK_ACTIVE" 6 "EAC_ELK_AVAILABLE" 5 "EAC_LKA_ACTIVE" 4 "EAC_LKA_ELK_AVAILABLE" 3 "EAC_FAULT" 2 "EAC_ACTIVE" 1 "EAC_AVAILABLE" 0 "EAC_INHIBITED" ;
VAL_ 1465 DAS_sw069_diAPState 15 "DI_APC_SNA" 8 "DI_APC_UNPARK_COMPLETE" 7 "DI_APC_RESUMED" 6 "DI_APC_ABORTED" 5 "DI_APC_PAUSED" 4 "DI_APC_COMPLETE" 3 "DI_APC_ACTIVE" 2 "DI_APC_STARTED" 1 "DI_APC_STANDBY" 0 "DI_APC_UNAVAILABLE" ;
VAL_ 1465 DAS_sw069_parkCal 1 "COMPLETE" 0 "INCOMPLETE" ;
VAL_ 1465 DAS_sw070_currTireFitment 3 "SNA" 1 "STAGGERED" 0 "SQUARE" ;
VAL_ 1465 DAS_sw070_lastTireFitment 3 "SNA" 1 "STAGGERED" 0 "SQUARE" ;
VAL_ 1465 DAS_sw070_diGear 7 "DI_GEAR_SNA" 4 "DI_GEAR_D" 3 "DI_GEAR_N" 2 "DI_GEAR_R" 1 "DI_GEAR_P" 0 "DI_GEAR_INVALID" ;
VAL_ 1465 DAS_sw071_selfParkType 7 "SNA" 6 "SP_GUIDANCE_UNAVAILABLE" 5 "SP_GUIDANCE_FAULT" 4 "SP_GUIDANCE_ABORT" 3 "SP_GUIDANCE_COMPLETE" 2 "SP_GUIDANCE_UNPARK_ACTIVE" 1 "SP_GUIDANCE_PARK_ACTIVE" 0 "SP_GUIDANCE_STANDBY" ;
VAL_ 1465 DAS_sw071_roadClass 6 "CLASS_6_MINOR" 5 "CLASS_5" 4 "CLASS_4" 3 "CLASS_3" 2 "CLASS_2" 1 "CLASS_1_MAJOR" 0 "UNKNOWN_INVALID_SNA" ;
VAL_ 1465 DAS_sw071_driverPresent 1 "TRUE" 0 "FALSE" ;
VAL_ 1465 DAS_sw071_airSuspension 6 "VERY_HIGH_LEVEL" 5 "HIGH_LEVEL" 4 "NORMAL_LEVEL" 3 "LOW_LEVEL" ;
VAL_ 1465 DAS_sw071_activationType 2 "AUTOSUMMON" 1 "KEYFOB" 0 "CELL_PHONE" ;
VAL_ 1465 DAS_sw073_escalateLDWreason 3 "LC_ELDW_REASON_STW_TAKEOVER" 2 "LC_ELDW_REASON_DOUBLE_PULL" 1 "LC_ELDW_REASON_SINGLE_PULL" 0 "LC_ELDW_REASON_NONE" ;
VAL_ 1465 DAS_sw073_rawMobileyeLDW 3 "RESERVED" 2 "LDW_RIGHT" 1 "LDW_LEFT" 0 "NO_WARNING" ;
VAL_ 1465 DAS_sw073_freespaceLDW 3 "RESERVED" 2 "LDW_RIGHT" 1 "LDW_LEFT" 0 "NO_WARNING" ;
VAL_ 1465 DAS_sw074_roadClass 6 "CLASS_6_MINOR" 5 "CLASS_5" 4 "CLASS_4" 3 "CLASS_3" 2 "CLASS_2" 1 "CLASS_1_MAJOR" 0 "UNKNOWN_INVALID_SNA" ;
VAL_ 1465 DAS_sw074_cruiseActive 1 "CRUISE_ACTIVE" 0 "CRUISE_INACTIVE" ;
VAL_ 1465 DAS_sw074_autopilotActive 1 "AUTOPILOT_ACTIVE" 0 "AUTOPILOT_INACTIVE" ;
VAL_ 1465 DAS_sw075_scMia 1 "CH_SC_Status_MIA" 0 "Nominal" ;
VAL_ 1465 DAS_sw193_outOfFocusImage 1 "True" 0 "False" ;
VAL_ 1465 DAS_sw193_impairedVD 1 "True" 0 "False" ;
VAL_ 1465 DAS_sw193_blurredImage 1 "True" 0 "False" ;
VAL_ 1465 DAS_sw193_smearedSpots 1 "True" 0 "False" ;
VAL_ 1465 DAS_sw193_partialBlockage 1 "True" 0 "False" ;
VAL_ 1465 DAS_sw193_fullBlockage 1 "True" 0 "False" ;
VAL_ 1465 DAS_sw193_smearedHalos 1 "True" 0 "False" ;
VAL_ 1465 DAS_sw194_leadDx 255 "SNA" ;
VAL_ 1465 DAS_sw194_leadVx 31 "SNA" ;
VAL_ 1465 DAS_sw194_leadAx 31 "SNA" ;
VAL_ 1465 DAS_sw194_reasonForHold 15 "SNA" 12 "STOPS_BUTTON_TOGGLE" 11 "MISSION_PLANNER_SLOWDOWN_REQUEST" 10 "STANDSTILL_STEERING_OVERRIDE" 9 "CAM_ONLY_CONTROL" 8 "MCP_CONTROL" 7 "DRIVER_SEATBELT" 6 "TRAFFIC_LIGHT" 5 "STOP_SIGN" 4 "CAM_STOP_AND_GO" 3 "TARGET_LOSS" 2 "ULTRASONIC_OBSTACLE" 1 "CAM_PEDESTRIAN" 0 "TIMEOUT" ;
VAL_ 1465 DAS_sw199_internalState 14 "APC_INT_STATE_CENTER_STW" 13 "APC_INT_STATE_GEAR_CHANGE" 12 "APC_INT_STATE_PARKED" 11 "APC_INT_STATE_COMPLETE_UNPARKED" 10 "APC_INT_STATE_COMPLETE" 9 "APC_INT_STATE_ABORT" 8 "APC_INT_STATE_RESTART" 7 "APC_INT_STATE_PAUSE_USER_CONTROL" 6 "APC_INT_STATE_PAUSE_OBSTACLE_CONTROL" 5 "APC_INT_STATE_REVERSE_CONTROL" 4 "APC_INT_STATE_FORWARD_CONTROL" 3 "APC_INT_STATE_PREGUIDANCE" 2 "APC_INT_STATE_PRECRUISE" 1 "APC_INT_STATE_SEARCHING" 0 "APC_INT_STATE_DISABLED" ;
VAL_ 1465 DAS_sw199_abortCodePARK 31 "SNA" 17 "ERROR" 16 "SYSTEM_FAULT" 15 "SYSTEM_SERVICE" 14 "DAS_ABORT" 13 "EPAS_FAULT" 12 "VEHICLE_DYNAMICS_INTERVENTION" 11 "HANDS_ON_DETECTED" 10 "FULL_WARNING_ON_BOTH_SIDES" 9 "PARK_SPACE_TOO_SMALL" 8 "OBSTACLE_ON_PATH" 7 "MAX_YAW_ANGLE_REACHED" 6 "MAX_SWA_DEV_EXCEEDED" 5 "OFF_TRACK" 4 "UNCONTROLLED_TRAVEL_DIST_REACHED" 3 "NO_VALID_PATH" 2 "MAX_NUM_OF_MOVES" 1 "VELOCITY_TOO_HIGH" 0 "NONE" ;
VAL_ 1465 DAS_sw199_abortCodeDas 28 "APC_ABORT_TOO_MANY_GEAR_CHANGES" 27 "APC_ABORT_TRAILER_MODE" 26 "APC_ABORT_PARKER_HEARTBEAT_MISSING" 25 "APC_ABORT_HEARTBEAT_MISSING" 24 "APC_ABORT_APP_MIA" 23 "APC_ABORT_PAUSE_CYCLES" 22 "APC_ABORT_EPAS_INHIBITED" 21 "APC_ABORT_USER_KEYFOB" 20 "APC_ABORT_SC_MIA" 19 "APC_ABORT_SENSOR_FAILURE" 18 "APC_ABORT_PRECRUISE_TIMEOUT" 17 "APC_ABORT_UI_REQUEST" 16 "APC_ABORT_LOST_DI_CONTROL" 15 "APC_ABORT_PARK_GEAR" 14 "APC_ABORT_RESTART_TIMEOUT" 13 "APC_ABORT_PAUSE_USER_TIMEOUT" 12 "APC_ABORT_PAUSE_OBSTACLE_TIMEOUT" 11 "APC_ABORT_ESP_MIA" 10 "APC_ABORT_SCCM_MIA" 9 "APC_ABORT_MCU_MIA" 8 "APC_ABORT_DI_MIA" 7 "APC_ABORT_EPAS_MIA" 6 "APC_ABORT_PARK_MIA" 5 "APC_ABORT_PREGUIDANCE_TIMEOUT" 4 "APC_ABORT_INVALID_SPACE" 3 "APC_ABORT_MCU_REQUEST_MISMATCH" 2 "APC_ABORT_PARK_GUIDANCE_ENDED" 1 "APC_ABORT_LOST_ANGLE_CONTROL" 0 "APC_ABORT_NONE" ;
VAL_ 1465 DAS_sw200_autopilotIntState 15 "PRECANCEL" 14 "DRIVER_STEERING_OVERRIDE" 13 "PREABORTED" 12 "FAULT" 11 "ABORTED" 10 "ABORTING" 9 "CHECK_ACTIVATION_WHILE_UNAVAILABLE" 8 "CHECK_ACTIVATION_WHILE_DISABLED" 7 "ACTIVE_RESTRICTED" 6 "ACTIVE_NOMINAL" 5 "PREACTIVATION" 4 "CHECK_FOR_ACTIVATION" 3 "AVAILABLE" 2 "UNAVAILABLE" 1 "DISABLED" 0 "NO_AUTOPILOT" ;
VAL_ 1465 DAS_sw201_viewRangeOAL 5 "ANOMALY_LEVEL_5" 4 "ANOMALY_LEVEL_4" 3 "ANOMALY_LEVEL_3" 2 "ANOMALY_LEVEL_2" 1 "ANOMALY_LEVEL_1" 0 "ANOMALY_LEVEL_0" ;
VAL_ 1465 DAS_sw201_steeringErrorOAL 5 "ANOMALY_LEVEL_5" 4 "ANOMALY_LEVEL_4" 3 "ANOMALY_LEVEL_3" 2 "ANOMALY_LEVEL_2" 1 "ANOMALY_LEVEL_1" 0 "ANOMALY_LEVEL_0" ;
VAL_ 1465 DAS_sw201_virtualLaneInputOAL 5 "ANOMALY_LEVEL_5" 4 "ANOMALY_LEVEL_4" 3 "ANOMALY_LEVEL_3" 2 "ANOMALY_LEVEL_2" 1 "ANOMALY_LEVEL_1" 0 "ANOMALY_LEVEL_0" ;
VAL_ 1465 DAS_sw203_roadClass 6 "CLASS_6_MINOR" 5 "CLASS_5" 4 "CLASS_4" 3 "CLASS_3" 2 "CLASS_2" 1 "CLASS_1_MAJOR" 0 "UNKNOWN_INVALID_SNA" ;
VAL_ 1465 DAS_sw203_curbType 2 "HIGH_CURB" 1 "LOW_CURB" 0 "VIRTUAL_CURB" ;
VAL_ 1465 DAS_sw203_controlType 15 "SNA" 14 "SUMMON" 10 "PAUSE" 9 "SEARCH" 8 "COMPLETE" 7 "ABORT" 6 "PARALLEL_PULL_OUT_TO_RIGHT" 5 "PARALLEL_PULL_OUT_TO_LEFT" 4 "PARK_RIGHT_CROSS" 3 "PARK_RIGHT_PARALLEL" 2 "PARK_LEFT_CROSS" 1 "PARK_LEFT_PARALLEL" 0 "NONE" ;
VAL_ 1465 DAS_sw204_frLeftMiddle 255 "SNA" ;
VAL_ 1465 DAS_sw204_frRightMiddle 255 "SNA" ;
VAL_ 1465 DAS_sw204_frRight 255 "SNA" ;
VAL_ 1465 DAS_sw204_frLeft 255 "SNA" ;
VAL_ 1465 DAS_sw204_frMiddle 255 "SNA" ;
VAL_ 1465 DAS_sw205_rrRightMiddle 255 "SNA" ;
VAL_ 1465 DAS_sw205_rrLeftMiddle 255 "SNA" ;
VAL_ 1465 DAS_sw205_rrRight 255 "SNA" ;
VAL_ 1465 DAS_sw205_rrLeft 255 "SNA" ;
VAL_ 1465 DAS_sw205_rrMiddle 255 "SNA" ;
VAL_ 1465 DAS_sw205_oocDistance 255 "SNA" ;
VAL_ 1465 DAS_sw207_lcUnavailableReason 255 "LC_UNAVAILABLE_UNKNOWN" 80 "RR_UNAVAILABLE_SYSTEM_HEALTH_CRITICAL" 79 "RR_UNAVAILABLE_PERCEPTION_HEALTH_RADAR" 78 "RR_UNAVAILABLE_PERCEPTION_HEALTH_VISION" 77 "RR_UNAVAILABLE_RADAR_BLIND" 76 "RR_UNAVAILABLE_RADAR_FAULT" 75 "RR_UNAVAILABLE_RADAR_MIA" 74 "RR_UNAVAILABLE_ECU_THERMAL_ISSUE" 73 "RR_UNAVAILABLE_AEB_ACTIVE" 72 "RR_UNAVAILABLE_AUTOPARK_STATE" 71 "RR_UNAVAILABLE_STEERING_WHEEL_ANGLE" 70 "RR_UNAVAILABLE_FAILED_AUTOSTEER_ACTIVATION" 69 "RR_UNAVAILABLE_INVALID_DI_PEDAL_POS" 68 "RR_UNAVAILABLE_INVALID_VEHICLE_SPEED" 67 "RR_UNAVAILABLE_AP_NOT_CONFIGURED" 66 "RR_UNAVAILABLE_INTEGRATOR_HEALTH_CRITICAL" 65 "RR_UNAVAILABLE_RADAR_VERSION_MISMATCH" 64 "RR_UNAVAILABLE_TRACKED_OBSTACLE_DETECTED" 63 "RR_UNAVAILABLE_SONIC_OBSTACLE_DETECTED" 62 "RR_UNAVAILABLE_PEDESTRIAN_PRESENT_OR_NO_VEHICLE" 61 "RR_UNAVAILABLE_AVAILABILITY_CHECK_HYSTERESIS" 60 "RR_UNAVAILABLE_CAMERA_BLOCKED" 59 "RR_UNAVAILABLE_CAMERA_PITCH" 58 "RR_UNAVAILABLE_CAMERA_CALIBRATION" 57 "RR_UNAVAILABLE_DI_MIA" 56 "RR_UNAVAILABLE_GTW_MIA" 55 "RR_UNAVAILABLE_EPAS_MIA" 54 "RR_UNAVAILABLE_ESP_MIA" 53 "RR_UNAVAILABLE_DI_PARTY_MIA" 52 "RR_UNAVAILABLE_EPAS_PARTY_MIA" 51 "RR_UNAVAILABLE_ESP_PARTY_MIA" 50 "RR_UNAVAILABLE_CONTROL_REFERENCE_UNHEALTHY" 49 "RR_UNAVAILABLE_CONTROL_STALE_REFERENCE" 48 "RR_UNAVAILABLE_CONTROL_STALE_LOCALIZATION" 47 "RR_UNAVAILABLE_CONTROL_BAD_UPDATE" 46 "RR_UNAVAILABLE_CONTROL_REFERENCE_TOO_SHORT" 45 "RR_UNAVAILABLE_CONTROL_INDETERMINATE" 44 "RR_UNAVAILABLE_BELOW_MIN_SPEED" 43 "LC_UNAVAILABLE_SEATBELT_UNBUCKLED" 42 "RR_UNAVAILABLE_EPAS_STEERING_ANGLE_INVALID" 41 "RR_UNAVAILABLE_SYNTHESIZED_ACC_LANES_ACTIVE" 40 "RR_UNAVAILABLE_MCU_LATERAL_CONTROL_DISABLED" 39 "RR_UNAVAILABLE_INVALID_LANE_LINE_TYPE" 38 "RR_UNAVAILABLE_ROAD_ESTIMATOR_NOT_ALLOWED" 37 "RR_UNAVAILABLE_VEHICLE_SPEED_ABOVE_MAX_HYST" 36 "RR_UNAVAILABLE_SPEED_LIMIT_EXCEEDED" 35 "RR_UNAVAILABLE_CONTROL_SOLVER_UNHEALTHY" 34 "RR_UNAVAILABLE_CONTROL_PATH_UNHEALTHY" 33 "RR_UNAVAILABLE_CONTROL_OUTSIDE_LIMITS" 32 "RR_UNAVAILABLE_USER_STRIKEOUT" 31 "RR_UNAVAILABLE_EAC_REQUEST_TIMEOUT" 30 "RR_UNAVAILABLE_HK_TW_RESTRICTED" 29 "RR_UNAVAILABLE_TRAILER_MODE_ACTIVE" 28 "RR_UNAVAILABLE_CAMERA_FAILSAFES" 27 "RR_UNAVAILABLE_STEERING_LIMITS_EXCEEDED" 26 "RR_UNAVAILABLE_VEHICLE_SPEED_ABOVE_MAX" 25 "RR_UNAVAILABLE_VEHICLE_NOT_IN_DRIVE" 24 "RR_UNAVAILABLE_CRUISE_FAULT" 23 "RR_UNAVAILABLE_COMPONENT_NOT_READY" 22 "RR_UNAVAILABLE_COMPONENT_MIA" 21 "RR_UNAVAILABLE_EPAS_EAC_DENIED" 20 "RR_UNAVAILABLE_NONE" 19 "LC_UNAVAILABLE_VEHICLE_SPEED_ABOVE_MAX_HYST" 18 "LC_UNAVAILABLE_NOT_ON_HIGHWAY" 17 "LC_UNAVAILABLE_SPEED_LIMIT_EXCEEDED" 16 "LC_UNAVAILABLE_APP_ME_STATE_NOT_VISION" 15 "LC_UNAVAILABLE_ME_MAIN_STATE_NOT_VISION" 14 "LC_UNAVAILABLE_USER_STRIKEOUT" 13 "LC_UNAVAILABLE_EAC_REQUEST_TIMEOUT" 12 "LC_UNAVAILABLE_CAM_MSG_MIA" 11 "LC_UNAVAILABLE_HK_TW_RESTRICTED" 10 "LC_UNAVAILABLE_CAM_WATCHDOG" 9 "LC_UNAVAILABLE_TRAILER_MODE_ACTIVE" 8 "LC_UNAVAILABLE_CAMERA_FAILSAFES" 7 "LC_UNAVAILABLE_STEERING_LIMITS_EXCEEDED" 6 "LC_UNAVAILABLE_VEHICLE_SPEED_ABOVE_MAX" 5 "LC_UNAVAILABLE_VEHICLE_NOT_IN_DRIVE" 4 "LC_UNAVAILABLE_CRUISE_FAULT" 3 "LC_UNAVAILABLE_COMPONENT_NOT_READY" 2 "LC_UNAVAILABLE_COMPONENT_MIA" 1 "LC_UNAVAILABLE_EPAS_EAC_DENIED" 0 "LC_UNAVAILABLE_NONE" ;
VAL_ 1465 DAS_sw207_appMobileyeStatus 24 "MOBILEYE_STATUS_UNDEFINED" 23 "MOBILEYE_STATUS_TEARDOWN_FLASH_ACCESS_MODE" 22 "MOBILEYE_STATUS_FLASH_READ_MODE" 21 "MOBILEYE_STATUS_SETUP_FLASH_ACCESS_MODE" 20 "MOBILEYE_STATUS_RUNNING_SPTAC_MODE" 19 "MOBILEYE_STATUS_SPTAC_INIT_SENT" 18 "MOBILEYE_STATUS_WAITING_FOR_SPTAC_INIT" 17 "MOBILEYE_STATUS_BURN_EDR_MODE" 16 "MOBILEYE_STATUS_SPC_INIT_SENT" 15 "MOBILEYE_STATUS_WAITING_FOR_SPC_INIT" 14 "MOBILEYE_STATUS_ERROR" 13 "MOBILEYE_STATUS_LATCHING_FAILURE" 12 "MOBILEYE_STATUS_UPDATING" 11 "MOBILEYE_STATUS_RUNNING_DV_MODE" 10 "MOBILEYE_STATUS_WAITING_FOR_DV" 9 "MOBILEYE_STATUS_RUNNING_TAC_MODE" 8 "MOBILEYE_STATUS_RUNNING_SPC_MODE" 7 "MOBILEYE_STATUS_RUNNING_VISION_MODE" 6 "MOBILEYE_STATUS_TAC_INIT_SENT" 5 "MOBILEYE_STATUS_WAITING_FOR_TAC_INIT" 4 "MOBILEYE_STATUS_VISION_INIT_SENT" 3 "MOBILEYE_STATUS_WAITING_FOR_VISION_INIT" 2 "MOBILEYE_STATUS_WAITING_FOR_BOOT" 1 "MOBILEYE_STATUS_POWER_OFF" 0 "MOBILEYE_STATUS_POWER_CYCLE" ;
VAL_ 1465 DAS_sw207_eyeq3MainState 172 "EYEQ_MESP_MAIN_STATE_TAC2" 170 "EYEQ_MESP_MAIN_STATE_DV" 146 "EYEQ_MESP_MAIN_STATE_VISION_INIT_PENDING" 133 "EYEQ_MESP_MAIN_STATE_TAC2_INIT_PENDING" 130 "EYEQ_MESP_MAIN_STATE_SPC_INIT_PENDING" 129 "EYEQ_MESP_MAIN_STATE_SPTAC_INIT_PENDING" 34 "EYEQ_MESP_MAIN_STATE_SPC" 33 "EYEQ_MESP_MAIN_STATE_SPTAC" 2 "EYEQ_MESP_MAIN_STATE_VISION" ;
VAL_ 1465 DAS_sw218_handsOnState 15 "LC_HANDS_ON_SNA" 9 "LC_HANDS_ON_REQD_ESCALATED_CHIME_2" 8 "LC_HANDS_ON_REQD_ESCALATED_CHIME_1" 7 "LC_HANDS_ON_REQD_STRUCK_OUT" 5 "LC_HANDS_ON_REQD_CHIME_2" 4 "LC_HANDS_ON_REQD_CHIME_1" 3 "LC_HANDS_ON_REQD_VISUAL" 2 "LC_HANDS_ON_REQD_NOT_DETECTED" 1 "LC_HANDS_ON_REQD_DETECTED" 0 "LC_HANDS_ON_NOT_REQD" ;
VAL_ 1465 DAS_sw227_sensorSide 1 "VEHICLE_SIDE_RIGHT" 0 "VEHICLE_SIDE_LEFT" ;
VAL_ 1465 DAS_sw227_sensorNumber 1 "SENSOR_MIDDLE" 0 "SENSOR_FRONT" ;
VAL_ 583 DAS_roadEstimator 3 "ROAD_ESTIMATOR_CRITICAL" 2 "ROAD_ESTIMATOR_DEGRADED" 1 "ROAD_ESTIMATOR_UNSTABLE_MEASUREMENTS" 0 "ROAD_ESTIMATOR_HEALTHY" ;
VAL_ 583 DAS_arbiterBehavior 4 "ARBITER_CITY_STREETS" 3 "ARBITER_LANE_CHANGE_RIGHT" 2 "ARBITER_LANE_CHANGE_LEFT" 1 "ARBITER_IN_LANE" 0 "ARBITER_INVALID" ;
VAL_ 583 DAS_mapAvailability 1 "APM_MAP_AVAILABLE" 0 "APM_MAP_NOT_AVAILABLE" ;
VAL_ 583 DAS_controllerRef 6 "CONTROLLER_REFERENCE_INDETERMINATE" 5 "CONTROLLER_REFERENCE_REF_TOO_SHORT" 4 "CONTROLLER_REFERENCE_BAD_REF_UPDATE" 3 "CONTROLLER_REFERENCE_STALE_LOCALIZATION" 2 "CONTROLLER_REFERENCE_STALE_REFERENCE" 1 "CONTROLLER_REFERENCE_UNHEALTHY" 0 "CONTROLLER_REFERENCE_HEALTHY" ;
VAL_ 583 DAS_alcInternalState 12 "ALC_RETRY" 11 "ALC_SOFT_ABORTING_RIGHT" 10 "ALC_SOFT_ABORTING_LEFT" 9 "ALC_ACTIVE_ACC_RIGHT" 8 "ALC_ACTIVE_ACC_LEFT" 7 "ALC_ACTIVE_RIGHT" 6 "ALC_ACTIVE_LEFT" 5 "ALC_PRE_ACTIVE_RIGHT" 4 "ALC_PRE_ACTIVE_LEFT" 3 "ALC_BEHAVIOR_CHECK" 2 "ALC_ABORTING" 1 "ALC_IDLE" 0 "ALC_DISABLED" ;
VAL_ 583 DAS_behaviorReport 44 "BEHAVIOR_SUGGESTED_VISION_SPEED" 43 "BEHAVIOR_ROUNDABOUT" 42 "BEHAVIOR_TOLLBOOTH" 41 "BEHAVIOR_CROSS_TRAFFIC_AVOIDANCE" 40 "BEHAVIOR_CROSSWALK" 39 "BEHAVIOR_RELEVANT_VRU" 38 "BEHAVIOR_RISK_MANAGER" 37 "BEHAVIOR_STATIC_OBJECT_MERGE_RIGHT" 36 "BEHAVIOR_STATIC_OBJECT_MERGE_LEFT" 35 "BEHAVIOR_CUTIN_VEHICLE" 34 "BEHAVIOR_STATIC_OBJECT" 33 "BEHAVIOR_LANE_SPEED_DIFF" 32 "BEHAVIOR_END_OF_NAV_ROUTE" 31 "BEHAVIOR_STEERING_SATURATED" 30 "BEHAVIOR_ACTIVE_SAFETY_SLOWDOWN" 29 "BEHAVIOR_MP_AP_INACTIVE" 28 "BEHAVIOR_MP_ULC" 27 "BEHAVIOR_MP_DI_CRUISE" 26 "BEHAVIOR_MP_AP_STATE_MACHINE" 25 "BEHAVIOR_MP_DRIVER_MONITOR" 24 "BEHAVIOR_MP_NOT_BUCKLED" 23 "BEHAVIOR_MP_AP_RESTRICTION" 22 "BEHAVIOR_CUTIN_VEHICLE_RIGHT" 21 "BEHAVIOR_CUTIN_VEHICLE_LEFT" 20 "BEHAVIOR_MERGE_VEHICLE_RIGHT" 19 "BEHAVIOR_MERGE_VEHICLE_LEFT" 18 "BEHAVIOR_NAV_PATH_CSA" 17 "BEHAVIOR_NAV_FLEET_SPEEDS" 16 "BEHAVIOR_VISION_SPEEDS" 15 "BEHAVIOR_SLOWING_FOR_TARGET_LANE" 14 "BEHAVIOR_DRIVABLE_SPACE_VIOLATION" 13 "BEHAVIOR_MAP_LANE_GEOMETRY" 12 "BEHAVIOR_VISION_LANE_GEOMETRY" 11 "BEHAVIOR_TRAFFIC_CONTROL" 10 "BEHAVIOR_UNDERTAKE_VEHICLE" 9 "BEHAVIOR_TARGET_LANE_VEHICLE" 8 "BEHAVIOR_IN_LANE_VEHICLE" 7 "BEHAVIOR_UNDERTAKE_ASSIST_KEEP_CALM" 6 "BEHAVIOR_TRAFFIC_CONTROL_STOPPED_STATE" 5 "BEHAVIOR_FLEET_SPEEDS" 4 "BEHAVIOR_KEEP_CALM" 3 "BEHAVIOR_RADAR_ONLY_BRAKING" 2 "BEHAVIOR_CURVE_SPEED_ADAPTATION" 1 "BEHAVIOR_VIEW_RANGE" ;
VAL_ 583 DAS_controllerHealth 3 "CONTROLLER_SOLVER_FAILURE" 2 "CONTROLLER_CRITICAL" 1 "CONTROLLER_DEGRADED" 0 "CONTROLLER_HEALTHY" ;
VAL_ 583 DAS_autopilotAbortReason 49 "ABORT_ONCOMING_LANE" 48 "ABORT_HEADLIGHT_OFF_AT_NIGHT" 47 "ABORT_IBOOSTER_MIA" 46 "ABORT_INTEGRATOR_HEALTH_CRITICAL" 45 "ABORT_USER_OVERRIDE_STRIKEOUT" 44 "ABORT_SEATBELT_UNBUCKLED" 43 "ABORT_PERCEPTION_HEALTH_VISION" 42 "ABORT_INVALID_VEHICLE_SPEED" 41 "ABORT_INVALID_DI_PEDAL_POS" 40 "ABORT_W048_FEATURES_DISABLED" 39 "ABORT_EPAS_STEERING_ANGLE_INVALID" 38 "ABORT_STEERING_SATURATED_LANE_DEPARTURE" 37 "ABORT_REACHED_END_OF_NAV_STOP" 36 "ABORT_GORE_INCURSION" 35 "ABORT_MISSION_PLANNER_NO_VISION_LANES_FOUND" 34 "ABORT_CONTROLLER_REF_TOO_SHORT" 33 "ABORT_AEB" 32 "ABORT_CONTROLLER_BAD_REF_UPDATE" 31 "ABORT_CONTROLLER_STALE_LOCALIZATION" 30 "ABORT_CONTROLLER_STALE_REFERENCE" 29 "ABORT_MAP_HEALTH" 28 "ABORT_THERMAL_ISSUE" 27 "ABORT_CONTROLLER_NOT_ALLOWED" 26 "ABORT_CONTROLLER_SOLVER" 25 "ABORT_CONTROLLER_REFERENCE" 24 "ABORT_ROAD_ESTIMATOR_HEALTH" 23 "ABORT_ACC_FAULT" 22 "ABORT_ACC_CANCEL_SILENT" 21 "ABORT_ACC_CANCEL_GENERIC" 20 "ABORT_RADAR_FAULT" 19 "ABORT_RADAR_BLIND" 18 "ABORT_CAMERA_CALIBRATION" 17 "ABORT_CAMERA_FAILSAFES" 16 "ABORT_EPAS_EAC_ERROR" 15 "ABORT_EPAS_EAC_NOT_ACTIVE" 14 "ABORT_VEHICLE_SPEED_ABOVE_MAX" 13 "ABORT_TRAILER_MODE_ACTIVE" 12 "ABORT_USER_DISABLED" 11 "ABORT_CRUISE_NOT_ACTIVE" 10 "ABORT_CRUISE_FAULT" 9 "ABORT_VCRIGHT_MIA" 8 "ABORT_VCFRONT_MIA" 7 "ABORT_RADAR_MIA" 6 "ABORT_SCCM_MIA" 5 "ABORT_GTW_MIA" 4 "ABORT_EPAS_MIA" 3 "ABORT_ESP_MIA" 2 "ABORT_DI_MIA" 1 "ABORT_WATCHDOG_HEALTH" 0 "ABORT_NONE" ;
VAL_ 583 DAS_rqstedBehaviorStatus 22 "RQST_BEHAVIOR_INVALID_PLAN" 21 "RQST_BEHAVIOR_BLOCKED_BY_SLOW_TARGET_R" 20 "RQST_BEHAVIOR_BLOCKED_BY_SLOW_TARGET_L" 19 "RQST_BEHAVIOR_BAD_ORIGIN_UPDATE" 18 "RQST_BEHAVIOR_OUT_OF_DATE" 17 "RQST_BEHAVIOR_ROAD_NOT_APPROPRIATE" 16 "RQST_BEHAVIOR_BLOCKED_BY_LANE_TYPE_R" 15 "RQST_BEHAVIOR_BLOCKED_BY_ULTRASOUND_AND_CAMERA_R" 14 "RQST_BEHAVIOR_BLOCKED_BY_BLINDSPOT_CAMERA_INVALID_R" 13 "RQST_BEHAVIOR_BLOCKED_BY_BLINDSPOT_CAMERA_R" 12 "RQST_BEHAVIOR_BLOCKED_BY_ULTRASOUND_R" 11 "RQST_BEHAVIOR_BLOCKED_BY_LANE_TYPE_L" 10 "RQST_BEHAVIOR_BLOCKED_BY_ULTRASOUND_AND_CAMERA_L" 9 "RQST_BEHAVIOR_BLOCKED_BY_BLINDSPOT_CAMERA_INVALID_L" 8 "RQST_BEHAVIOR_BLOCKED_BY_BLINDSPOT_CAMERA_L" 7 "RQST_BEHAVIOR_BLOCKED_BY_ULTRASOUND_L" 6 "RQST_BEHAVIOR_BUILD_ARGUMENT_FAIL" 5 "RQST_BEHAVIOR_NO_TARGET_LANE_ON_MAP" 4 "RQST_BEHAVIOR_NO_SOURCE_LANE_ON_MAP" 3 "RQST_BEHAVIOR_MAP_NOT_INITIALIZED" 2 "RQST_BEHAVIOR_NO_DEST_POLYLANE" 1 "RQST_BEHAVIOR_NO_SRC_POLYLANE" 0 "RQST_BEHAVIOR_VALID" ;
VAL_ 583 DAS_forkState 27 "FORK_UNAVAILABLE_INTERSECTION_ACTIVE" 26 "FORK_PRE_ACTIVE_RIGHT_NAV" 25 "FORK_PRE_ACTIVE_LEFT_NAV" 24 "FORK_UNAVAILABLE_WEATHER" 23 "FORK_UNAVAILABLE_TIGHT_TURN_RADIUS" 22 "FORK_ABORT_OTHER" 21 "FORK_ABORT_DISALLOW" 20 "FORK_ABORT_NOT_RIGHT_LANE" 19 "FORK_ABORT_NOT_LEFT_LANE" 18 "FORK_ABORT_BLINKER_CHANGE" 17 "FORK_ABORT_CONTROL_INACTIVE" 16 "FORK_FORK_COMPLETE" 15 "FORK_ACTIVE_RIGHT_USER" 14 "FORK_ACTIVE_RIGHT_NAV" 13 "FORK_ACTIVE_LEFT_USER" 12 "FORK_ACTIVE_LEFT_NAV" 11 "FORK_IDLE_NO_FORKS_AVAILABLE" 10 "FORK_IDLE_RIGHT_FORK_AVAILABLE" 9 "FORK_IDLE_LEFT_FORK_AVAILABLE" 8 "FORK_IDLE_BOTH_FORKS_AVAILABLE" 7 "FORK_UNAVAILABLE_OTHER" 6 "FORK_UNAVAILABLE_TOLL_BOOTH" 5 "FORK_UNAVAILABLE_DON_INACTIVE" 4 "FORK_UNAVAILABLE_CONTROLLED_ACCESS_TOO_FAR" 3 "FORK_UNAVAILABLE_CONSTRUCTION" 2 "FORK_UNAVAILABLE_AP_INACTIVE" 1 "FORK_UNAVAILABLE_DISABLED" 0 "FORK_INVALID" ;
VAL_ 583 DAS_laneChangeState 63 "LANE_CHANGE_UNKNOWN" 43 "LANE_CHANGE_ABORTING_DESTINATION_LANE_UNSTABLE" 42 "LANE_CHANGE_UNAVAILABLE_AUTOPILOT_ABORTING" 41 "LANE_CHANGE_UNAVAILABLE_BLINKER_LATCHED" 40 "LANE_CHANGE_ABORTING_SNOOZED" 39 "LANE_CHANGE_ABORTING_SOURCE_AND_TARGET_LANES_MERGED" 38 "LANE_CHANGE_UNAVAILABLE_NO_REAR_OBJECT" 37 "LANE_CHANGE_ABORTING_NO_HANDS_ON" 36 "LANE_CHANGE_UNAVAILABLE_BLINDSPOT_RESTRICTED" 35 "LANE_CHANGE_ABORTING_WEATHER" 34 "LANE_CHANGE_ABORTING_TIGHT_TURN_RADIUS" 33 "LANE_CHANGE_ABORTING_TOLL_BOOTH_DETECTED" 32 "LANE_CHANGE_ABORTING_CONSTRUCTION_DETECTED" 31 "LANE_CHANGE_ABORTING_GORE_POINT" 30 "LANE_CHANGE_BLOCKED_RIGHT" 29 "LANE_CHANGE_BLOCKED_LEFT" 28 "LANE_CHANGE_IN_PROGRESS_RIGHT" 27 "LANE_CHANGE_IN_PROGRESS_LEFT" 26 "LANE_CHANGE_ABORTING_ALC_REQUEST_BEFORE_ULC_CONFIRM" 25 "LANE_CHANGE_ABORTING_ULC_CONFIRMATION_TIMEOUT" 24 "LANE_CHANGE_ABORTING_HIGH_ALC_PROGRESS_ERROR" 23 "LANE_CHANGE_ABORTING_BEHAVIOR_CHANGED" 22 "LANE_CHANGE_ABORTING_BELOW_MIN_SPEED" 21 "LANE_CHANGE_ABORTING_INVALID_BEHAVIOR" 20 "LANE_CHANGE_ABORTING_ULC_BLINKER_TIMEOUT" 19 "LANE_CHANGE_ABORTING_ACC_AUTOSTEER_ACTIVATED" 18 "LANE_CHANGE_ABORTING_LOST_VISION_POSE" 17 "LANE_CHANGE_ABORTING_FORK_AVAILABLE" 16 "LANE_CHANGE_ABORTING_LINE_TYPE" 15 "LANE_CHANGE_ABORTING_INVALID_MODE" 14 "LANE_CHANGE_ABORTING_BLIND_SPOT_OCCUPIED" 13 "LANE_CHANGE_ABORTING_TIMEOUT" 12 "LANE_CHANGE_ABORTING_BLINKER" 11 "LANE_CHANGE_ABORTING_INACTIVE" 10 "LANE_CHANGE_AVAILABLE_BOTH" 9 "LANE_CHANGE_AVAILABLE_RIGHT_ONLY" 8 "LANE_CHANGE_AVAILABLE_LEFT_ONLY" 7 "LANE_CHANGE_UNAVAILABLE_INVALID_MODE" 6 "LANE_CHANGE_UNAVAILABLE_ULTRASONICS_NOT_READY" 5 "LANE_CHANGE_UNAVAILABLE_FORK_MODE" 4 "LANE_CHANGE_UNAVAILABLE_INACTIVE" 3 "LANE_CHANGE_UNAVAILABLE_NO_LANES" 2 "LANE_CHANGE_UNAVAILABLE_SPEED" 1 "LANE_CHANGE_UNAVAILABLE_ROAD_NOT_APPROPRIATE" 0 "LANE_CHANGE_UNAVAILABLE_DISABLED" ;
VAL_ 583 DAS_lastWatchdogCode 80 "ULTRASONICS_FAILED" 79 "BEV_GRAPH_FAILED" 78 "CITY_STREETS_BEHAVIOR_FAILED" 77 "BRIDGE_FAILED" 76 "SCHEDULER_FAILED" 75 "DRIVABLE_SPACE_TRACKER_FAILED" 74 "CLIP_LOGGER_FAILED" 73 "HW_MONITOR_FAILED" 72 "PARKING_BEHAVIOR_FAILED" 71 "FIELD_CALIBRATION_FAILED" 70 "DYNAMICS_FAILED" 69 "UI_SERVER_FAILED" 68 "ACTIVE_SAFETY_FAILED" 67 "CAMERA_FAILED" 66 "MAP_MANAGER_FAILED" 65 "DRIVER_MONITOR_FAILED" 63 "LANE_CHANGE_BEHAVIOR_FAILED" 62 "UBX_LOG_FAILED" 61 "IMU_FAILED" 60 "RAIN_LIGHT_SENSING_FAILED" 59 "SNAPSHOT_TRIGGER_CLIENT_FAILED" 58 "STAY_IN_LANE_BEHAVIOR_FAILED" 57 "ATLAS_FAILED" 56 "ROAD_ESTIMATOR_FAILED" 55 "PERCEPTION_FAILED" 54 "MISSION_PLANNER_FAILED" 53 "LOCALIZER_FAILED" 52 "CONTROLLER_FAILED" 51 "AP_STATE_MACHINE_FAILED" 50 "ARBITER_FAILED" 49 "GPS_FAILED" 48 "INERTIATOR_FAILED" 47 "TEMPERATURE_MONITOR_FAILED" 46 "CAN_TX_FAILED" 45 "CAN_RX_FAILED" 44 "WATCHDOG_FAILED" 43 "LEGACY_FAILED" 42 "VISION_FAILED" 41 "SNAPSHOT_FAILED" 40 "TELEMETRY_FAILED" 39 "TELEMETRY_PACKAGER_FAILED" 30 "UNKNOWN_TASK_FAILED" 0 "NO_TASK_FAILED" ;
VAL_ 1001 DAS_headlightRequest 3 "DAS_HEADLIGHT_REQUEST_INVALID" 1 "DAS_HEADLIGHT_REQUEST_ON" 0 "DAS_HEADLIGHT_REQUEST_OFF" ;
VAL_ 1001 DAS_hazardLightRequest 3 "DAS_REQUEST_HAZARDS_SNA" 2 "DAS_REQUEST_HAZARDS_UNUSED" 1 "DAS_REQUEST_HAZARDS_ON" 0 "DAS_REQUEST_HAZARDS_OFF" ;
VAL_ 1001 DAS_wiperSpeed 15 "DAS_WIPER_SPEED_INVALID" 14 "DAS_WIPER_SPEED_14" 13 "DAS_WIPER_SPEED_13" 12 "DAS_WIPER_SPEED_12" 11 "DAS_WIPER_SPEED_11" 10 "DAS_WIPER_SPEED_10" 9 "DAS_WIPER_SPEED_9" 8 "DAS_WIPER_SPEED_8" 7 "DAS_WIPER_SPEED_7" 6 "DAS_WIPER_SPEED_6" 5 "DAS_WIPER_SPEED_5" 4 "DAS_WIPER_SPEED_4" 3 "DAS_WIPER_SPEED_3" 2 "DAS_WIPER_SPEED_2" 1 "DAS_WIPER_SPEED_1" 0 "DAS_WIPER_SPEED_OFF" ;
VAL_ 1001 DAS_turnIndicatorRequest 3 "DAS_TURN_INDICATOR_CANCEL" 2 "DAS_TURN_INDICATOR_RIGHT" 1 "DAS_TURN_INDICATOR_LEFT" 0 "DAS_TURN_INDICATOR_NONE" ;
VAL_ 1001 DAS_highLowBeamDecision 3 "DAS_HIGH_BEAM_SNA" 2 "DAS_HIGH_BEAM_ON" 1 "DAS_HIGH_BEAM_OFF" 0 "DAS_HIGH_BEAM_UNDECIDED" ;
VAL_ 1001 DAS_highLowBeamOffReason 5 "HIGH_BEAM_OFF_REASON_SNA" 4 "HIGH_BEAM_OFF_REASON_HEAD_LIGHT" 3 "HIGH_BEAM_OFF_REASON_AMBIENT_LIGHT" 2 "HIGH_BEAM_OFF_REASON_MOVING_RADAR_TARGET" 1 "HIGH_BEAM_OFF_REASON_MOVING_VISION_TARGET" 0 "HIGH_BEAM_ON" ;
VAL_ 1001 DAS_turnIndicatorRequestReason 12 "DAS_CANCEL_SUMMMON" 11 "DAS_ACTIVE_SUMMMON" 10 "DAS_CANCEL_INTERSECTION" 9 "DAS_ACTIVE_INTERSECTION" 8 "DAS_ACTIVE_COMMANDED_LANE_CHANGE" 7 "DAS_CANCEL_MERGE" 6 "DAS_ACTIVE_MERGE" 5 "DAS_CANCEL_FORK" 4 "DAS_CANCEL_LANE_CHANGE" 3 "DAS_ACTIVE_FORK" 2 "DAS_ACTIVE_SPEED_LANE_CHANGE" 1 "DAS_ACTIVE_NAV_LANE_CHANGE" 0 "DAS_NONE" ;
SIG_GROUP_ 643 ExtLmp_Stat 1 : LoBm_On_Rq;
SIG_GROUP_ 643 LgtSens_Stat_C 1 : ADL_LoBm_On_Rq LgtSens_Flt LgtSens_Night LgtSens_SNA LgtSens_Tunnel LgtSens_Twlgt;
